VERSION "HNNBNNNYNNNNNNNNNNNNNNNNNNNNNNNNNNNNNNNNNN/4/%%%/4/'%**4NNN///"

NS_ :

BS_:

BU_: Allrad_Haldex AreaView_MQB BAP_Tester Bremse_ABS_MK100 Bremse_ESP_EPB_EBC460Vi Bremse_ESP_EPB_MK100 Bremse_ESP_MK100 Daempfer Gateway_MQB Lenkhilfe_EPS PDC PDC_PLA

BO_ 2617020934 DEV_Lenkhilfe_Resp_06: 8 Lenkhilfe_EPS
 SG_ DEV_Lenkhilfe_Resp_06_Data : 0|64@1+ (1.0,0.0) [0.0|18446744073709551615] ""  Vector__XXX

BO_ 2617020935 DEV_Lenkhilfe_Resp_07: 8 Lenkhilfe_EPS
 SG_ DEV_Lenkhilfe_Resp_07_Data : 0|64@1+ (1.0,0.0) [0.0|18446744073709551615] ""  Vector__XXX

BO_ 2617020936 DEV_Lenkhilfe_Resp_08: 8 Lenkhilfe_EPS
 SG_ DEV_Lenkhilfe_Resp_08_Data : 0|64@1+ (1.0,0.0) [0.0|18446744073709551615] ""  Vector__XXX

BO_ 2617020937 DEV_Lenkhilfe_Resp_09: 8 Lenkhilfe_EPS
 SG_ DEV_Lenkhilfe_Resp_09_Data : 0|64@1+ (1.0,0.0) [0.0|18446744073709551615] ""  Vector__XXX

BO_ 2617020938 DEV_Lenkhilfe_Resp_10: 8 Lenkhilfe_EPS
 SG_ DEV_Lenkhilfe_Resp_10_Data : 0|64@1+ (1.0,0.0) [0.0|18446744073709551615] ""  Vector__XXX

BO_ 2617020939 DEV_Lenkhilfe_Resp_11: 8 Lenkhilfe_EPS
 SG_ DEV_Lenkhilfe_Resp_11_Data : 0|64@1+ (1.0,0.0) [0.0|18446744073709551615] ""  Vector__XXX

BO_ 2617020940 DEV_Lenkhilfe_Resp_12: 8 Lenkhilfe_EPS
 SG_ DEV_Lenkhilfe_Resp_12_Data : 0|64@1+ (1.0,0.0) [0.0|18446744073709551615] ""  Vector__XXX

BO_ 2617020941 DEV_Lenkhilfe_Resp_13: 8 Lenkhilfe_EPS
 SG_ DEV_Lenkhilfe_Resp_13_Data : 0|64@1+ (1.0,0.0) [0.0|18446744073709551615] ""  Vector__XXX

BO_ 2617020960 DEV_Lenkhilfe_SIC_Resp_01: 8 Lenkhilfe_EPS
 SG_ DEV_Lenkhilfe_SIC_Resp_01_Data : 0|64@1+ (1.0,0.0) [0.0|18446744073709551615] ""  Vector__XXX

BO_ 2617020961 DEV_Lenkhilfe_SIC_Resp_02: 8 Lenkhilfe_EPS
 SG_ DEV_Lenkhilfe_SIC_Resp_02_Data : 0|64@1+ (1.0,0.0) [0.0|18446744073709551615] ""  Vector__XXX

BO_ 2617004544 DEV_PDC_Resp_00: 8 PDC
 SG_ DEV_PDC_Resp_00_Data : 0|64@1+ (1.0,0.0) [0.0|18446744073709551615] ""  Vector__XXX

BO_ 2617004545 DEV_PDC_Resp_01: 8 PDC
 SG_ DEV_PDC_Resp_01_Data : 0|64@1+ (1.0,0.0) [0.0|18446744073709551615] ""  Vector__XXX

BO_ 2617004546 DEV_PDC_Resp_02: 8 PDC
 SG_ DEV_PDC_Resp_02_Data : 0|64@1+ (1.0,0.0) [0.0|18446744073709551615] ""  Vector__XXX

BO_ 2617004547 DEV_PDC_Resp_03: 8 PDC
 SG_ DEV_PDC_Resp_03_Data : 0|64@1+ (1.0,0.0) [0.0|18446744073709551615] ""  Vector__XXX

BO_ 2617004548 DEV_PDC_Resp_04: 8 PDC
 SG_ DEV_PDC_Resp_04_Data : 0|64@1+ (1.0,0.0) [0.0|18446744073709551615] ""  Vector__XXX

BO_ 2617004549 DEV_PDC_Resp_05: 8 PDC
 SG_ DEV_PDC_Resp_05_Data : 0|64@1+ (1.0,0.0) [0.0|18446744073709551615] ""  Vector__XXX

BO_ 2617004550 DEV_PDC_Resp_06: 8 PDC
 SG_ DEV_PDC_Resp_06_Data : 0|64@1+ (1.0,0.0) [0.0|18446744073709551615] ""  Vector__XXX

BO_ 2617004551 DEV_PDC_Resp_07: 8 PDC
 SG_ DEV_PDC_Resp_07_Data : 0|64@1+ (1.0,0.0) [0.0|18446744073709551615] ""  Vector__XXX

BO_ 2617004552 DEV_PDC_Resp_08: 8 PDC
 SG_ DEV_PDC_Resp_08_Data : 0|64@1+ (1.0,0.0) [0.0|18446744073709551615] ""  Vector__XXX

BO_ 2617004553 DEV_PDC_Resp_09: 8 PDC
 SG_ DEV_PDC_Resp_09_Data : 0|64@1+ (1.0,0.0) [0.0|18446744073709551615] ""  Vector__XXX

BO_ 2617004554 DEV_PDC_Resp_10: 8 PDC
 SG_ DEV_PDC_Resp_10_Data : 0|64@1+ (1.0,0.0) [0.0|18446744073709551615] ""  Vector__XXX

BO_ 2617004555 DEV_PDC_Resp_11: 8 PDC
 SG_ DEV_PDC_Resp_11_Data : 0|64@1+ (1.0,0.0) [0.0|18446744073709551615] ""  Vector__XXX

BO_ 2617004556 DEV_PDC_Resp_12: 8 PDC
 SG_ DEV_PDC_Resp_12_Data : 0|64@1+ (1.0,0.0) [0.0|18446744073709551615] ""  Vector__XXX

BO_ 2617004557 DEV_PDC_Resp_13: 8 PDC
 SG_ DEV_PDC_Resp_13_Data : 0|64@1+ (1.0,0.0) [0.0|18446744073709551615] ""  Vector__XXX

BO_ 2617004558 DEV_PDC_Resp_14: 8 PDC
 SG_ DEV_PDC_Resp_14_Data : 0|64@1+ (1.0,0.0) [0.0|18446744073709551615] ""  Vector__XXX

BO_ 2617004559 DEV_PDC_Resp_15: 8 PDC
 SG_ DEV_PDC_Resp_15_Data : 0|64@1+ (1.0,0.0) [0.0|18446744073709551615] ""  Vector__XXX

BO_ 2617004560 DEV_PDC_Resp_16: 8 PDC_PLA
 SG_ DEV_PDC_Resp_16_Data : 0|64@1+ (1.0,0.0) [0.0|18446744073709551615] ""  Vector__XXX

BO_ 2617004561 DEV_PDC_Resp_17: 8 PDC_PLA
 SG_ DEV_PDC_Resp_17_Data : 0|64@1+ (1.0,0.0) [0.0|18446744073709551615] ""  Vector__XXX

BO_ 2617004562 DEV_PDC_Resp_18: 8 PDC_PLA
 SG_ DEV_PDC_Resp_18_Data : 0|64@1+ (1.0,0.0) [0.0|18446744073709551615] ""  Vector__XXX

BO_ 2617004563 DEV_PDC_Resp_19: 8 PDC_PLA
 SG_ DEV_PDC_Resp_19_Data : 0|64@1+ (1.0,0.0) [0.0|18446744073709551615] ""  Vector__XXX

BO_ 2617004564 DEV_PDC_Resp_20: 8 PDC_PLA
 SG_ DEV_PDC_Resp_20_Data : 0|64@1+ (1.0,0.0) [0.0|18446744073709551615] ""  Vector__XXX

BO_ 2617004565 DEV_PDC_Resp_21: 8 PDC_PLA
 SG_ DEV_PDC_Resp_21_Data : 0|64@1+ (1.0,0.0) [0.0|18446744073709551615] ""  Vector__XXX

BO_ 2617004566 DEV_PDC_Resp_22: 8 PDC_PLA
 SG_ DEV_PDC_Resp_22_Data : 0|64@1+ (1.0,0.0) [0.0|18446744073709551615] ""  Vector__XXX

BO_ 2617004567 DEV_PDC_Resp_23: 8 PDC_PLA
 SG_ DEV_PDC_Resp_23_Data : 0|64@1+ (1.0,0.0) [0.0|18446744073709551615] ""  Vector__XXX

BO_ 2617004568 DEV_PDC_Resp_24: 8 PDC_PLA
 SG_ DEV_PDC_Resp_24_Data : 0|64@1+ (1.0,0.0) [0.0|18446744073709551615] ""  Vector__XXX

BO_ 2617004569 DEV_PDC_Resp_25: 8 PDC_PLA
 SG_ DEV_PDC_Resp_25_Data : 0|64@1+ (1.0,0.0) [0.0|18446744073709551615] ""  Vector__XXX

BO_ 2617004570 DEV_PDC_Resp_26: 8 PDC_PLA
 SG_ DEV_PDC_Resp_26_Data : 0|64@1+ (1.0,0.0) [0.0|18446744073709551615] ""  Vector__XXX

BO_ 2617004571 DEV_PDC_Resp_27: 8 PDC_PLA
 SG_ DEV_PDC_Resp_27_Data : 0|64@1+ (1.0,0.0) [0.0|18446744073709551615] ""  Vector__XXX

BO_ 2617004572 DEV_PDC_Resp_28: 8 PDC_PLA
 SG_ DEV_PDC_Resp_28_Data : 0|64@1+ (1.0,0.0) [0.0|18446744073709551615] ""  Vector__XXX

BO_ 2617004573 DEV_PDC_Resp_29: 8 PDC_PLA
 SG_ DEV_PDC_Resp_29_Data : 0|64@1+ (1.0,0.0) [0.0|18446744073709551615] ""  Vector__XXX

BO_ 2617004574 DEV_PDC_Resp_30: 8 PDC_PLA
 SG_ DEV_PDC_Resp_30_Data : 0|64@1+ (1.0,0.0) [0.0|18446744073709551615] ""  Vector__XXX

BO_ 2617004575 DEV_PDC_Resp_31: 8 PDC_PLA
 SG_ DEV_PDC_Resp_31_Data : 0|64@1+ (1.0,0.0) [0.0|18446744073709551615] ""  Vector__XXX

BO_ 2617199104 DEV_RearView_Resp_00: 8 AreaView_MQB
 SG_ DEV_RearView_Resp_00_Data : 0|64@1+ (1.0,0.0) [0.0|18446744073709551615] ""  Vector__XXX

BO_ 2617199105 DEV_RearView_Resp_01: 8 AreaView_MQB
 SG_ DEV_RearView_Resp_01_Data : 0|64@1+ (1.0,0.0) [0.0|18446744073709551615] ""  Vector__XXX

BO_ 2617199106 DEV_RearView_Resp_02: 8 AreaView_MQB
 SG_ DEV_RearView_Resp_02_Data : 0|64@1+ (1.0,0.0) [0.0|18446744073709551615] ""  Vector__XXX

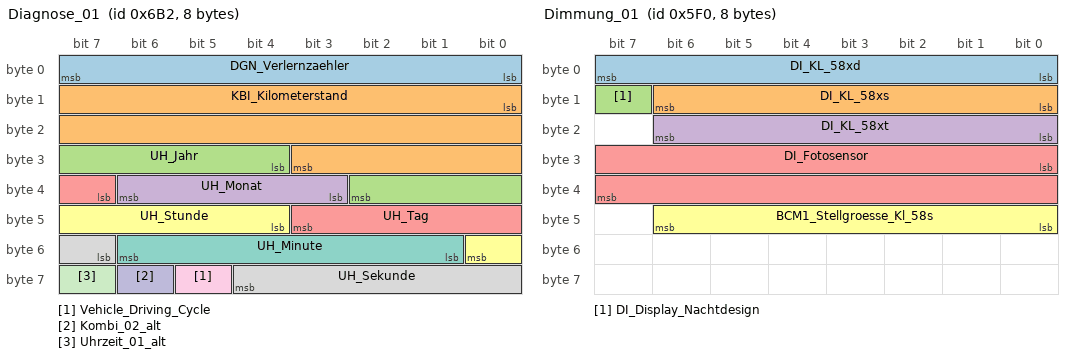
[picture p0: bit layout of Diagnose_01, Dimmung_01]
BO_ 1714 Diagnose_01: 8 Gateway_MQB
 SG_ DGN_Verlernzaehler : 0|8@1+ (1,0) [0|254] ""  Allrad_Haldex,AreaView_MQB,Bremse_ABS_MK100,Bremse_ESP_EPB_EBC460Vi,Bremse_ESP_EPB_MK100,Bremse_ESP_MK100,Daempfer,Lenkhilfe_EPS,PDC,PDC_PLA
 SG_ KBI_Kilometerstand : 8|20@1+ (1,0) [0|1048573] "Unit_KiloMeter"  Allrad_Haldex,AreaView_MQB,Bremse_ABS_MK100,Bremse_ESP_EPB_EBC460Vi,Bremse_ESP_EPB_MK100,Bremse_ESP_MK100,Daempfer,Lenkhilfe_EPS,PDC,PDC_PLA
 SG_ UH_Jahr : 28|7@1+ (1,2000) [2000|2127] "Unit_Year"  Allrad_Haldex,AreaView_MQB,Bremse_ABS_MK100,Bremse_ESP_EPB_EBC460Vi,Bremse_ESP_EPB_MK100,Bremse_ESP_MK100,Daempfer,Lenkhilfe_EPS,PDC,PDC_PLA
 SG_ UH_Monat : 35|4@1+ (1,0) [1|12] "Unit_Month"  Allrad_Haldex,AreaView_MQB,Bremse_ABS_MK100,Bremse_ESP_EPB_EBC460Vi,Bremse_ESP_EPB_MK100,Bremse_ESP_MK100,Daempfer,Lenkhilfe_EPS,PDC,PDC_PLA
 SG_ UH_Tag : 39|5@1+ (1,0) [1|31] "Unit_Day"  Allrad_Haldex,AreaView_MQB,Bremse_ABS_MK100,Bremse_ESP_EPB_EBC460Vi,Bremse_ESP_EPB_MK100,Bremse_ESP_MK100,Daempfer,Lenkhilfe_EPS,PDC,PDC_PLA
 SG_ UH_Stunde : 44|5@1+ (1,0) [0|23] "Unit_Hours"  Allrad_Haldex,AreaView_MQB,Bremse_ABS_MK100,Bremse_ESP_EPB_EBC460Vi,Bremse_ESP_EPB_MK100,Bremse_ESP_MK100,Daempfer,Lenkhilfe_EPS,PDC,PDC_PLA
 SG_ UH_Minute : 49|6@1+ (1,0) [0|59] "Unit_Minut"  Allrad_Haldex,AreaView_MQB,Bremse_ABS_MK100,Bremse_ESP_EPB_EBC460Vi,Bremse_ESP_EPB_MK100,Bremse_ESP_MK100,Daempfer,Lenkhilfe_EPS,PDC,PDC_PLA
 SG_ UH_Sekunde : 55|6@1+ (1,0) [0|59] "Unit_Secon"  Allrad_Haldex,AreaView_MQB,Bremse_ABS_MK100,Bremse_ESP_EPB_EBC460Vi,Bremse_ESP_EPB_MK100,Bremse_ESP_MK100,Daempfer,Lenkhilfe_EPS,PDC,PDC_PLA
 SG_ Vehicle_Driving_Cycle : 61|1@1+ (1.0,0.0) [0.0|1] ""  Vector__XXX
 SG_ Kombi_02_alt : 62|1@1+ (1.0,0.0) [0.0|1] ""  AreaView_MQB,Bremse_ABS_MK100,Bremse_ESP_EPB_EBC460Vi,Bremse_ESP_EPB_MK100,Bremse_ESP_MK100,Lenkhilfe_EPS
 SG_ Uhrzeit_01_alt : 63|1@1+ (1.0,0.0) [0.0|1] ""  AreaView_MQB,Bremse_ABS_MK100,Bremse_ESP_EPB_EBC460Vi,Bremse_ESP_EPB_MK100,Bremse_ESP_MK100,Lenkhilfe_EPS,PDC,PDC_PLA

BO_ 1520 Dimmung_01: 8 Gateway_MQB
 SG_ DI_KL_58xd : 0|8@1+ (1,0) [0|253] ""  AreaView_MQB,Bremse_ESP_EPB_EBC460Vi,Bremse_ESP_EPB_MK100,PDC,PDC_PLA
 SG_ DI_KL_58xs : 8|7@1+ (1,0) [0|100] "Unit_PerCent"  Vector__XXX
 SG_ DI_Display_Nachtdesign : 15|1@1+ (1.0,0.0) [0.0|1] ""  Vector__XXX
 SG_ DI_KL_58xt : 16|7@1+ (1,0) [0|100] "Unit_PerCent"  Vector__XXX
 SG_ DI_Fotosensor : 24|16@1+ (1,0) [0|65535] ""  Vector__XXX
 SG_ BCM1_Stellgroesse_Kl_58s : 40|7@1+ (1,0) [0|100] ""  Vector__XXX

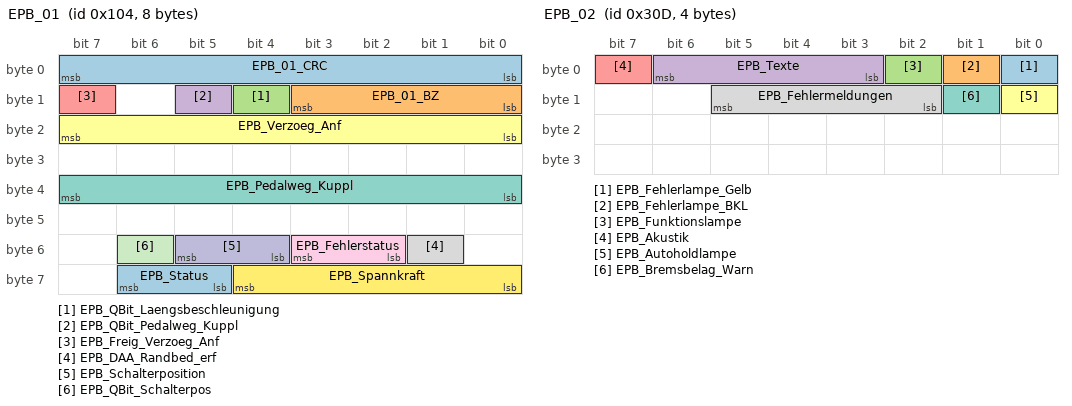
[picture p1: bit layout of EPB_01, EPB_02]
BO_ 260 EPB_01: 8 Bremse_ESP_EPB_EBC460Vi
 SG_ EPB_01_CRC : 0|8@1+ (1,0) [0|255] ""  Gateway_MQB
 SG_ EPB_01_BZ : 8|4@1+ (1,0) [0|15] ""  Gateway_MQB
 SG_ EPB_QBit_Laengsbeschleunigung : 12|1@1+ (1.0,0.0) [0.0|1] ""  Gateway_MQB
 SG_ EPB_QBit_Pedalweg_Kuppl : 13|1@1+ (1.0,0.0) [0.0|1] ""  Gateway_MQB
 SG_ EPB_Freig_Verzoeg_Anf : 15|1@1+ (1.0,0.0) [0.0|1] ""  Daempfer,Gateway_MQB
 SG_ EPB_Verzoeg_Anf : 16|8@1+ (0.048,-7.968) [-7.968|4.224] "Unit_MeterPerSeconSquar"  Daempfer,Gateway_MQB
 SG_ EPB_Pedalweg_Kuppl : 32|8@1+ (0.4,0) [8.0|92.0] "Unit_PerCent"  Gateway_MQB
 SG_ EPB_DAA_Randbed_erf : 49|1@1+ (1.0,0.0) [0.0|1] ""  Gateway_MQB
 SG_ EPB_Fehlerstatus : 50|2@1+ (1.0,0.0) [0.0|3] ""  Gateway_MQB,PDC,PDC_PLA
 SG_ EPB_Schalterposition : 52|2@1+ (1.0,0.0) [0.0|3] ""  Gateway_MQB
 SG_ EPB_QBit_Schalterpos : 54|1@1+ (1.0,0.0) [0.0|1] ""  Gateway_MQB
 SG_ EPB_Spannkraft : 56|5@1+ (1,0) [0|29] "Unit_KiloNewto"  Gateway_MQB
 SG_ EPB_Status : 61|2@1+ (1.0,0.0) [0.0|3] ""  AreaView_MQB,Gateway_MQB,PDC,PDC_PLA

BO_ 781 EPB_02: 4 Bremse_ESP_EPB_EBC460Vi
 SG_ EPB_Fehlerlampe_Gelb : 0|1@1+ (1.0,0.0) [0.0|1] ""  Gateway_MQB
 SG_ EPB_Fehlerlampe_BKL : 1|1@1+ (1.0,0.0) [0.0|1] ""  Gateway_MQB
 SG_ EPB_Funktionslampe : 2|1@1+ (1.0,0.0) [0.0|1] ""  Gateway_MQB
 SG_ EPB_Texte : 3|4@1+ (1.0,0.0) [0.0|15] ""  Gateway_MQB
 SG_ EPB_Akustik : 7|1@1+ (1.0,0.0) [0.0|1] ""  Gateway_MQB
 SG_ EPB_Autoholdlampe : 8|1@1+ (1.0,0.0) [0.0|1] ""  Gateway_MQB
 SG_ EPB_Bremsbelag_Warn : 9|1@1+ (1.0,0.0) [0.0|1] ""  Gateway_MQB
 SG_ EPB_Fehlermeldungen : 10|4@1+ (1.0,0.0) [0.0|15] ""  Gateway_MQB

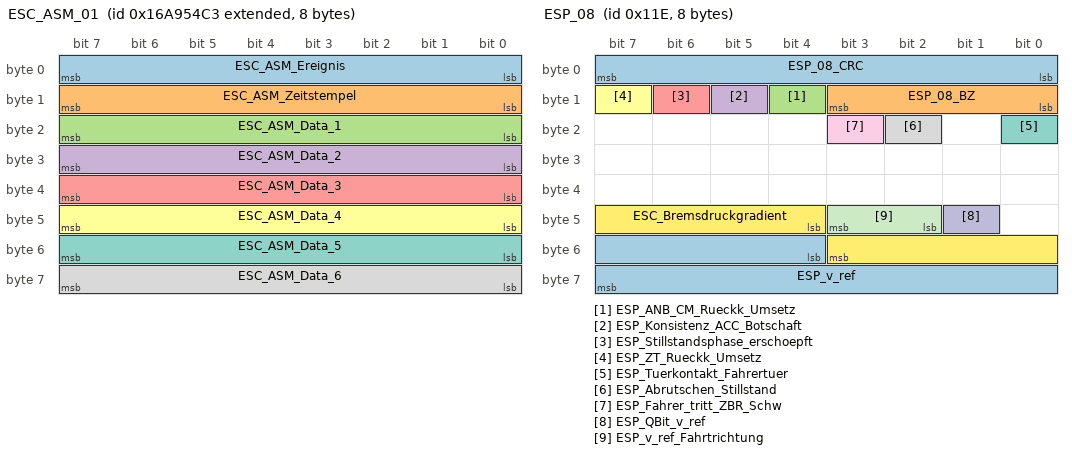
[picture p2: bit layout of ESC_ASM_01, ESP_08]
BO_ 2527679683 ESC_ASM_01: 8 Bremse_ESP_EPB_EBC460Vi
 SG_ ESC_ASM_Ereignis : 0|8@1+ (1.0,0.0) [0.0|255] ""  Gateway_MQB
 SG_ ESC_ASM_Zeitstempel : 8|8@1+ (0.08,0) [0.00|20.32] "Unit_Secon"  Gateway_MQB
 SG_ ESC_ASM_Data_1 : 16|8@1+ (1,0) [0|255] ""  Gateway_MQB
 SG_ ESC_ASM_Data_2 : 24|8@1+ (1,0) [0|255] ""  Gateway_MQB
 SG_ ESC_ASM_Data_3 : 32|8@1+ (1,0) [0|255] ""  Gateway_MQB
 SG_ ESC_ASM_Data_4 : 40|8@1+ (1,0) [0|255] ""  Gateway_MQB
 SG_ ESC_ASM_Data_5 : 48|8@1+ (1,0) [0|255] ""  Gateway_MQB
 SG_ ESC_ASM_Data_6 : 56|8@1+ (1,0) [0|255] ""  Gateway_MQB

BO_ 257 ESP_02: 8 Bremse_ABS_MK100
 SG_ ESP_02_CRC : 0|8@1+ (1,0) [0|255] ""  Gateway_MQB,Lenkhilfe_EPS,PDC_PLA
 SG_ ESP_02_BZ : 8|4@1+ (1,0) [0|15] ""  Allrad_Haldex,Gateway_MQB,Lenkhilfe_EPS,PDC_PLA
 SG_ ESP_QBit_Gierrate : 12|1@1+ (1.0,0.0) [0.0|1] ""  Allrad_Haldex,AreaView_MQB,Daempfer,Gateway_MQB,Lenkhilfe_EPS,PDC_PLA
 SG_ ESP_QBit_Laengsbeschl : 13|1@1+ (1.0,0.0) [0.0|1] ""  Allrad_Haldex,AreaView_MQB,Daempfer,Gateway_MQB,Lenkhilfe_EPS,PDC_PLA
 SG_ ESP_QBit_Querb : 14|1@1+ (1.0,0.0) [0.0|1] ""  Allrad_Haldex,AreaView_MQB,Daempfer,Gateway_MQB,Lenkhilfe_EPS
 SG_ ESP_Stillstandsflag : 15|1@1+ (1.0,0.0) [0.0|1] ""  Gateway_MQB
 SG_ ESP_Querbeschleunigung : 16|8@1+ (0.01,-1.27) [-1.27|1.27] "Unit_ForceOfGravi"  Allrad_Haldex,AreaView_MQB,Daempfer,Gateway_MQB,Lenkhilfe_EPS
 SG_ ESP_Laengsbeschl : 24|10@1+ (0.03125,-16) [-16.00000|15.90625] "Unit_MeterPerSeconSquar"  Allrad_Haldex,AreaView_MQB,Daempfer,Gateway_MQB,Lenkhilfe_EPS,PDC_PLA
 SG_ ESC_Motorstartverzoegerung : 34|1@1+ (1.0,0.0) [0.0|1] ""  Gateway_MQB
 SG_ ESC_SeitenwindAssistent_Eingriff : 35|1@1+ (1.0,0.0) [0.0|1] ""  Gateway_MQB
 SG_ ESP_Anschleppstart_Freigabe : 36|2@1+ (1.0,0.0) [0.0|3] ""  Gateway_MQB
 SG_ ESP_QBit_Anf_Vert_Wank : 39|1@1+ (1.0,0.0) [0.0|1] ""  Gateway_MQB
 SG_ ESP_Gierrate : 40|14@1+ (0.01,0) [0.00|163.82] "Unit_DegreOfArcPerSecon"  Allrad_Haldex,AreaView_MQB,Daempfer,Gateway_MQB,Lenkhilfe_EPS,PDC,PDC_PLA
 SG_ ESP_VZ_Gierrate : 54|1@1+ (1.0,0.0) [0.0|1] ""  Allrad_Haldex,AreaView_MQB,Daempfer,Gateway_MQB,Lenkhilfe_EPS,PDC,PDC_PLA
 SG_ ESP_Notbremsanzeige : 55|1@1+ (1.0,0.0) [0.0|1] ""  Gateway_MQB
 SG_ ESP_SpannungsAnf : 56|1@1+ (1.0,0.0) [0.0|1] ""  Gateway_MQB
 SG_ ESP_PLA_Abbruch : 57|3@1+ (1.0,0.0) [0.0|7] ""  Gateway_MQB,PDC_PLA
 SG_ ESP_Status_ESP_PLA : 60|4@1+ (1.0,0.0) [0.0|15] ""  Gateway_MQB,PDC_PLA

BO_ 262 ESP_05: 8 Bremse_ABS_MK100
 SG_ ESP_05_CRC : 0|8@1+ (1,0) [0|255] ""  Gateway_MQB,Lenkhilfe_EPS,PDC_PLA
 SG_ ESP_05_BZ : 8|4@1+ (1,0) [0|15] ""  Allrad_Haldex,Gateway_MQB,Lenkhilfe_EPS,PDC_PLA
 SG_ ESP_QBit_Bremsdruck : 12|1@1+ (1.0,0.0) [0.0|1] ""  Daempfer,Gateway_MQB,Lenkhilfe_EPS,PDC_PLA
 SG_ ESP_QBit_Fahrer_bremst : 13|1@1+ (1.0,0.0) [0.0|1] ""  Allrad_Haldex,Gateway_MQB,Lenkhilfe_EPS
 SG_ ESP_Schwelle_Unterdruck : 14|2@1+ (1.0,0.0) [0.0|3] ""  Gateway_MQB
 SG_ ESP_Bremsdruck : 16|10@1+ (0.3,-30) [-30.0|276.6] "Unit_Bar"  Allrad_Haldex,Daempfer,Gateway_MQB,Lenkhilfe_EPS,PDC_PLA
 SG_ ESP_Fahrer_bremst : 26|1@1+ (1.0,0.0) [0.0|1] ""  Allrad_Haldex,Gateway_MQB,Lenkhilfe_EPS
 SG_ ESP_Verz_TSK_aktiv : 27|1@1+ (1.0,0.0) [0.0|1] ""  Allrad_Haldex,Gateway_MQB
 SG_ ESP_Lenkeingriff_ADS : 28|1@1+ (1.0,0.0) [0.0|1] ""  Gateway_MQB
 SG_ ESP_Konsistenz_TSK : 29|1@1+ (1.0,0.0) [0.0|1] ""  Gateway_MQB
 SG_ ESP_Bremsruck_AWV2 : 30|1@1+ (1.0,0.0) [0.0|1] ""  Gateway_MQB
 SG_ ESP_Konsistenz_AWV2 : 31|1@1+ (1.0,0.0) [0.0|1] ""  Gateway_MQB
 SG_ ECD_Fehler : 32|1@1+ (1.0,0.0) [0.0|1] ""  Gateway_MQB
 SG_ ECD_nicht_verfuegbar : 33|1@1+ (1.0,0.0) [0.0|1] ""  Gateway_MQB
 SG_ ESP_Status_Bremsentemp : 34|1@1+ (1.0,0.0) [0.0|1] ""  Gateway_MQB
 SG_ ESP_Autohold_Standby : 35|1@1+ (1.0,0.0) [0.0|1] ""  Gateway_MQB
 SG_ ESP_HDC_Standby : 36|1@1+ (1.0,0.0) [0.0|1] ""  Gateway_MQB
 SG_ ESP_HBA_aktiv : 37|1@1+ (1.0,0.0) [0.0|1] ""  Gateway_MQB
 SG_ ESP_Prefill_ausgeloest : 38|1@1+ (1.0,0.0) [0.0|1] ""  Gateway_MQB
 SG_ ESP_Rueckwaertsfahrt_erkannt : 39|1@1+ (1.0,0.0) [0.0|1] ""  Gateway_MQB
 SG_ ESP_Status_Anfahrhilfe : 40|1@1+ (1.0,0.0) [0.0|1] ""  Gateway_MQB
 SG_ ESP_HDC_aktiv : 41|1@1+ (1.0,0.0) [0.0|1] ""  Gateway_MQB
 SG_ ESP_StartStopp_Info : 42|2@1+ (1.0,0.0) [0.0|3] ""  Gateway_MQB
 SG_ ESP_Eingr_HL : 44|1@1+ (1.0,0.0) [0.0|1] ""  Gateway_MQB
 SG_ ESP_Eingr_HR : 45|1@1+ (1.0,0.0) [0.0|1] ""  Gateway_MQB
 SG_ ESP_Eingr_VL : 46|1@1+ (1.0,0.0) [0.0|1] ""  Gateway_MQB
 SG_ ESP_Eingr_VR : 47|1@1+ (1.0,0.0) [0.0|1] ""  Gateway_MQB
 SG_ ESP_BKV_Unterdruck : 48|8@1+ (4,0) [4|1012] "Unit_MilliBar"  Gateway_MQB
 SG_ ESP_Autohold_aktiv : 56|1@1+ (1.0,0.0) [0.0|1] ""  Gateway_MQB
 SG_ ESP_FStatus_Anfahrhilfe : 57|1@1+ (1.0,0.0) [0.0|1] ""  Gateway_MQB
 SG_ ESP_Verz_EPB_aktiv : 58|1@1+ (1.0,0.0) [0.0|1] ""  Allrad_Haldex,Gateway_MQB
 SG_ ECD_Bremslicht : 59|1@1+ (1.0,0.0) [0.0|1] ""  Gateway_MQB
 SG_ ESP_Verzoeg_EPB_verf : 60|1@1+ (1.0,0.0) [0.0|1] ""  Gateway_MQB
 SG_ ESP_Status_Bremsdruck : 61|1@1+ (1.0,0.0) [0.0|1] ""  Gateway_MQB
 SG_ ESP_Anforderung_EPB : 62|2@1+ (1.0,0.0) [0.0|3] ""  Gateway_MQB

BO_ 914 ESP_07: 8 Bremse_ABS_MK100
 SG_ ESP_07_CRC : 0|8@1+ (1,0) [0|255] ""  Gateway_MQB
 SG_ ESP_07_BZ : 8|4@1+ (1,0) [0|15] ""  Gateway_MQB
 SG_ ESP_ACC_LDE : 12|1@1+ (1.0,0.0) [0.0|1] ""  Gateway_MQB
 SG_ ESP_Allrad_Antrieb : 13|1@1+ (1.0,0.0) [0.0|1] ""  Gateway_MQB
 SG_ ESP_Codierung_ADS : 14|2@1+ (1.0,0.0) [0.0|3] ""  Gateway_MQB
 SG_ ESP_RTA_HL : 16|8@1+ (0.048828125,-6.20117) [-6.201170000|6.152345625] "Unit_PerCent"  Gateway_MQB
 SG_ ESP_RTA_HR : 24|8@1+ (0.048828125,-6.20117) [-6.201170000|6.152345625] "Unit_PerCent"  Gateway_MQB
 SG_ ESP_RTA_VR : 32|8@1+ (0.048828125,-6.20117) [-6.201170000|6.152345625] "Unit_PerCent"  Gateway_MQB
 SG_ OBD_Fehler_Radsensor_HL : 40|4@1+ (1.0,0.0) [0.0|15] ""  Gateway_MQB
 SG_ OBD_Fehler_Radsensor_HR : 44|4@1+ (1.0,0.0) [0.0|15] ""  Gateway_MQB
 SG_ OBD_Fehler_Radsensor_VL : 48|4@1+ (1.0,0.0) [0.0|15] ""  Gateway_MQB
 SG_ OBD_Fehler_Radsensor_VR : 52|4@1+ (1.0,0.0) [0.0|15] ""  Gateway_MQB
 SG_ ESP_Qualifizierung_Antriebsart : 56|1@1+ (1.0,0.0) [0.0|1] ""  Gateway_MQB
 SG_ ESP_Offroad_Modus : 57|1@1+ (1.0,0.0) [0.0|1] ""  Gateway_MQB
 SG_ ESP_MKB_ausloesbar : 58|1@1+ (1.0,0.0) [0.0|1] ""  Gateway_MQB
 SG_ ESP_Stat_FallBack_eBKV : 59|1@1+ (1.0,0.0) [0.0|1] ""  Gateway_MQB
 SG_ ESP_CM_Variante : 60|1@1+ (1.0,0.0) [0.0|1] ""  Gateway_MQB
 SG_ ESP_OBD_Status : 61|1@1+ (1.0,0.0) [0.0|1] ""  Gateway_MQB
 SG_ ESP_Rollenmodus_Deaktivieren : 62|1@1+ (1.0,0.0) [0.0|1] ""  Allrad_Haldex,Daempfer,Gateway_MQB,PDC,PDC_PLA
 SG_ ESP_nachtr_Stopp_Anf : 63|1@1+ (1.0,0.0) [0.0|1] ""  Gateway_MQB

BO_ 286 ESP_08: 8 Bremse_ESP_EPB_EBC460Vi
 SG_ ESP_08_CRC : 0|8@1+ (1,0) [0|255] ""  Gateway_MQB
 SG_ ESP_08_BZ : 8|4@1+ (1,0) [0|15] ""  Gateway_MQB
 SG_ ESP_ANB_CM_Rueckk_Umsetz : 12|1@1+ (1.0,0.0) [0.0|1] ""  Gateway_MQB
 SG_ ESP_Konsistenz_ACC_Botschaft : 13|1@1+ (1.0,0.0) [0.0|1] ""  Gateway_MQB
 SG_ ESP_Stillstandsphase_erschoepft : 14|1@1+ (1.0,0.0) [0.0|1] ""  Gateway_MQB
 SG_ ESP_ZT_Rueckk_Umsetz : 15|1@1+ (1.0,0.0) [0.0|1] ""  Gateway_MQB
 SG_ ESP_Tuerkontakt_Fahrertuer : 16|1@1+ (1.0,0.0) [0.0|1] ""  Gateway_MQB
 SG_ ESP_Abrutschen_Stillstand : 18|1@1+ (1.0,0.0) [0.0|1] ""  Gateway_MQB
 SG_ ESP_Fahrer_tritt_ZBR_Schw : 19|1@1+ (1.0,0.0) [0.0|1] ""  Gateway_MQB
 SG_ ESP_QBit_v_ref : 41|1@1+ (1.0,0.0) [0.0|1] ""  Gateway_MQB
 SG_ ESP_v_ref_Fahrtrichtung : 42|2@1+ (1.0,0.0) [0.0|3] ""  Gateway_MQB
 SG_ ESC_Bremsdruckgradient : 44|8@1+ (10,0) [0|2500] "Unit_BarPerSecon"  Gateway_MQB
 SG_ ESP_v_ref : 52|12@1+ (0.125,0) [0.000|511.500] "Unit_KiloMeterPerHour"  Gateway_MQB

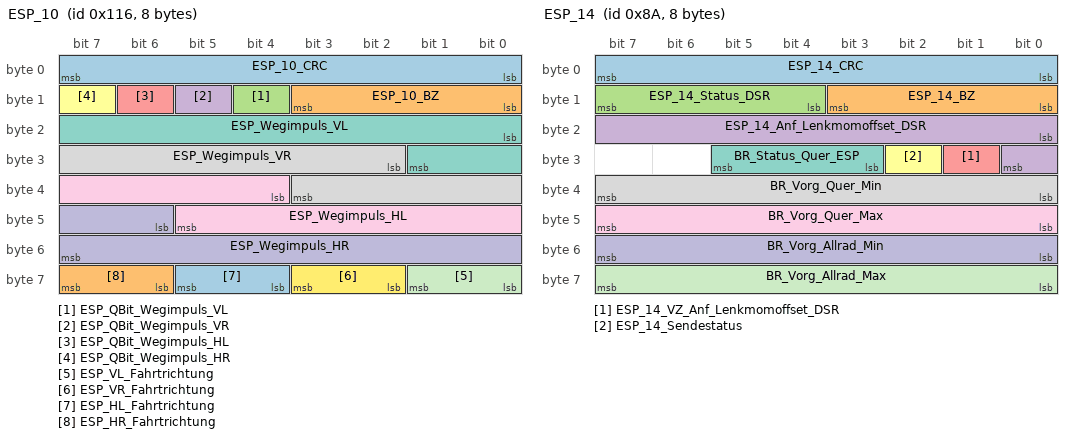
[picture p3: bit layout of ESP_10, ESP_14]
BO_ 278 ESP_10: 8 Bremse_ABS_MK100
 SG_ ESP_10_CRC : 0|8@1+ (1,0) [0|255] ""  Gateway_MQB,Lenkhilfe_EPS,PDC,PDC_PLA
 SG_ ESP_10_BZ : 8|4@1+ (1,0) [0|15] ""  Gateway_MQB,Lenkhilfe_EPS,PDC,PDC_PLA
 SG_ ESP_QBit_Wegimpuls_VL : 12|1@1+ (1.0,0.0) [0.0|1] ""  AreaView_MQB,Gateway_MQB,Lenkhilfe_EPS,PDC,PDC_PLA
 SG_ ESP_QBit_Wegimpuls_VR : 13|1@1+ (1.0,0.0) [0.0|1] ""  AreaView_MQB,Gateway_MQB,Lenkhilfe_EPS,PDC,PDC_PLA
 SG_ ESP_QBit_Wegimpuls_HL : 14|1@1+ (1.0,0.0) [0.0|1] ""  AreaView_MQB,Gateway_MQB,Lenkhilfe_EPS,PDC,PDC_PLA
 SG_ ESP_QBit_Wegimpuls_HR : 15|1@1+ (1.0,0.0) [0.0|1] ""  AreaView_MQB,Gateway_MQB,Lenkhilfe_EPS,PDC,PDC_PLA
 SG_ ESP_Wegimpuls_VL : 16|10@1+ (1,0) [0|1000] ""  AreaView_MQB,Gateway_MQB,Lenkhilfe_EPS,PDC,PDC_PLA
 SG_ ESP_Wegimpuls_VR : 26|10@1+ (1,0) [0|1000] ""  AreaView_MQB,Gateway_MQB,Lenkhilfe_EPS,PDC,PDC_PLA
 SG_ ESP_Wegimpuls_HL : 36|10@1+ (1,0) [0|1000] ""  AreaView_MQB,Gateway_MQB,Lenkhilfe_EPS,PDC,PDC_PLA
 SG_ ESP_Wegimpuls_HR : 46|10@1+ (1,0) [0|1000] ""  AreaView_MQB,Gateway_MQB,Lenkhilfe_EPS,PDC,PDC_PLA
 SG_ ESP_VL_Fahrtrichtung : 56|2@1+ (1.0,0.0) [0.0|3] ""  AreaView_MQB,Gateway_MQB,Lenkhilfe_EPS,PDC,PDC_PLA
 SG_ ESP_VR_Fahrtrichtung : 58|2@1+ (1.0,0.0) [0.0|3] ""  AreaView_MQB,Gateway_MQB,Lenkhilfe_EPS,PDC,PDC_PLA
 SG_ ESP_HL_Fahrtrichtung : 60|2@1+ (1.0,0.0) [0.0|3] ""  AreaView_MQB,Gateway_MQB,Lenkhilfe_EPS,PDC,PDC_PLA
 SG_ ESP_HR_Fahrtrichtung : 62|2@1+ (1.0,0.0) [0.0|3] ""  AreaView_MQB,Gateway_MQB,Lenkhilfe_EPS,PDC,PDC_PLA

BO_ 138 ESP_14: 8 Bremse_ABS_MK100
 SG_ ESP_14_CRC : 0|8@1+ (1,0) [0|255] ""  Lenkhilfe_EPS
 SG_ ESP_14_BZ : 8|4@1+ (1,0) [0|15] ""  Lenkhilfe_EPS
 SG_ ESP_14_Status_DSR : 12|4@1+ (1.0,0.0) [0.0|15] ""  Gateway_MQB,Lenkhilfe_EPS
 SG_ ESP_14_Anf_Lenkmomoffset_DSR : 16|9@1+ (0.01,0) [0.00|5.11] "Unit_NewtoMeter"  Gateway_MQB,Lenkhilfe_EPS
 SG_ ESP_14_VZ_Anf_Lenkmomoffset_DSR : 25|1@1+ (1.0,0.0) [0.0|1] ""  Gateway_MQB,Lenkhilfe_EPS
 SG_ ESP_14_Sendestatus : 26|1@1+ (1.0,0.0) [0.0|1] ""  Vector__XXX
 SG_ BR_Status_Quer_ESP : 27|3@1+ (1.0,0.0) [0.0|7] ""  Vector__XXX
 SG_ BR_Vorg_Quer_Min : 32|8@1+ (0.4,0) [0.0|100.0] "Unit_PerCent"  Vector__XXX
 SG_ BR_Vorg_Quer_Max : 40|8@1+ (0.4,0) [0.0|100.0] "Unit_PerCent"  Vector__XXX
 SG_ BR_Vorg_Allrad_Min : 48|8@1+ (0.4,0) [0.0|100.0] "Unit_PerCent"  Allrad_Haldex
 SG_ BR_Vorg_Allrad_Max : 56|8@1+ (0.4,0) [0.0|100.0] "Unit_PerCent"  Allrad_Haldex

BO_ 418 ESP_15: 8 Bremse_ESP_EPB_MK100
 SG_ ESP_15_CRC : 0|8@1+ (1,0) [0|255] ""  Gateway_MQB
 SG_ ESP_15_BZ : 8|4@1+ (1,0) [0|15] ""  Gateway_MQB
 SG_ HMS_P_beibehalten_GE : 12|2@1+ (1.0,0.0) [0.0|3] ""  Gateway_MQB
 SG_ HMS_Konsistenz_GE : 14|1@1+ (1.0,0.0) [0.0|1] ""  Gateway_MQB
 SG_ HMS_Konsistenz_IPA : 15|1@1+ (1.0,0.0) [0.0|1] ""  Gateway_MQB,PDC_PLA
 SG_ HMS_Konsistenz_EBKV : 16|1@1+ (1.0,0.0) [0.0|1] ""  Gateway_MQB
 SG_ HMS_Konsistenz_RCTA : 17|1@1+ (1.0,0.0) [0.0|1] ""  Gateway_MQB
 SG_ HMS_Konsistenz_STA : 18|1@1+ (1.0,0.0) [0.0|1] ""  Gateway_MQB
 SG_ HMS_Konsistenz_MO : 19|1@1+ (1.0,0.0) [0.0|1] ""  Gateway_MQB
 SG_ HMS_halten_nicht_verfuegbar : 20|1@1+ (1.0,0.0) [0.0|1] ""  Gateway_MQB
 SG_ NL_PRIM_STP_01_Status : 21|3@1+ (1.0,0.0) [0.0|7] ""  Gateway_MQB
 SG_ HMS_Notstopp_Status : 29|3@1+ (1.0,0.0) [0.0|7] ""  Gateway_MQB
 SG_ HMS_parken_nicht_verfuegbar : 32|1@1+ (1.0,0.0) [0.0|1] ""  Gateway_MQB
 SG_ HMS_Anforderung_GE : 33|3@1+ (1.0,0.0) [0.0|7] ""  Gateway_MQB
 SG_ HMS_Systemstatus : 36|4@1+ (1.0,0.0) [0.0|15] ""  Gateway_MQB,PDC_PLA
 SG_ HMS_Stillstand : 40|3@1+ (1.0,0.0) [0.0|7] ""  Gateway_MQB,PDC_PLA
 SG_ HMS_aktives_System : 43|5@1+ (1.0,0.0) [0.0|31] ""  Gateway_MQB,PDC_PLA
 SG_ HMS_Konsistenz_HVLM : 48|1@1+ (1.0,0.0) [0.0|1] ""  Gateway_MQB
 SG_ HMS_Konsistenz_ACC : 49|1@1+ (1.0,0.0) [0.0|1] ""  Gateway_MQB
 SG_ HMS_Fehlerstatus : 50|3@1+ (1.0,0.0) [0.0|7] ""  Gateway_MQB,PDC_PLA
 SG_ ESP_Index_Haltemoment : 53|1@1+ (1.0,0.0) [0.0|1] ""  Gateway_MQB
 SG_ ESP_Haltemoment : 54|10@1+ (10,0) [0|10210] "Unit_NewtoMeter"  Gateway_MQB

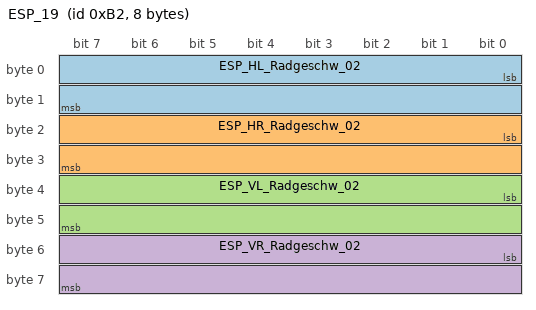
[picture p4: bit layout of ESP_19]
BO_ 178 ESP_19: 8 Bremse_ABS_MK100
 SG_ ESP_HL_Radgeschw_02 : 0|16@1+ (0.0075,0) [0.0000|491.4900] "Unit_KiloMeterPerHour"  Allrad_Haldex,AreaView_MQB,Gateway_MQB,Lenkhilfe_EPS,PDC,PDC_PLA
 SG_ ESP_HR_Radgeschw_02 : 16|16@1+ (0.0075,0) [0.0000|491.4900] "Unit_KiloMeterPerHour"  Allrad_Haldex,AreaView_MQB,Gateway_MQB,Lenkhilfe_EPS,PDC,PDC_PLA
 SG_ ESP_VL_Radgeschw_02 : 32|16@1+ (0.0075,0) [0.0000|491.4900] "Unit_KiloMeterPerHour"  Allrad_Haldex,AreaView_MQB,Gateway_MQB,Lenkhilfe_EPS,PDC,PDC_PLA
 SG_ ESP_VR_Radgeschw_02 : 48|16@1+ (0.0075,0) [0.0000|491.4900] "Unit_KiloMeterPerHour"  Allrad_Haldex,AreaView_MQB,Gateway_MQB,Lenkhilfe_EPS,PDC,PDC_PLA

BO_ 1629 ESP_20: 8 Bremse_ABS_MK100
 SG_ ESP_20_CRC : 0|8@1+ (1,0) [0|255] ""  Gateway_MQB,Lenkhilfe_EPS
 SG_ ESP_20_BZ : 8|4@1+ (1,0) [0|15] ""  Gateway_MQB,Lenkhilfe_EPS
 SG_ BR_Systemart : 12|2@1+ (1.0,0.0) [0.0|3] ""  Allrad_Haldex,Gateway_MQB
 SG_ ESP_SpannungsAnf_02 : 14|2@1+ (1.0,0.0) [0.0|3] ""  Gateway_MQB
 SG_ ESP_Zaehnezahl : 16|8@1+ (1,0) [0|255] ""  AreaView_MQB,Gateway_MQB,Lenkhilfe_EPS,PDC_PLA
 SG_ ESP_Charisma_FahrPr : 24|4@1+ (1.0,0.0) [0.0|15] ""  Gateway_MQB
 SG_ ESP_Charisma_Status : 28|2@1+ (1.0,0.0) [0.0|3] ""  Gateway_MQB
 SG_ ESP_Wiederstart_Anz_01 : 30|1@1+ (1.0,0.0) [0.0|1] ""  Gateway_MQB
 SG_ ESP_Wiederstart_Anz_02 : 31|1@1+ (1.0,0.0) [0.0|1] ""  Gateway_MQB
 SG_ ESP_Wiederstart_Anz_03 : 32|1@1+ (1.0,0.0) [0.0|1] ""  Gateway_MQB
 SG_ ESP_Wiederstart_Anz_04 : 33|1@1+ (1.0,0.0) [0.0|1] ""  Gateway_MQB
 SG_ ESP_Stoppverbot_Anz_01 : 34|1@1+ (1.0,0.0) [0.0|1] ""  Gateway_MQB
 SG_ ESP_Stoppverbot_Anz_02 : 35|1@1+ (1.0,0.0) [0.0|1] ""  Gateway_MQB
 SG_ ESP_Stoppverbot_Anz_03 : 36|1@1+ (1.0,0.0) [0.0|1] ""  Gateway_MQB
 SG_ ESP_Stoppverbot_Anz_04 : 37|1@1+ (1.0,0.0) [0.0|1] ""  Gateway_MQB
 SG_ ESP_Stoppverbot_Anz_05 : 38|1@1+ (1.0,0.0) [0.0|1] ""  Gateway_MQB
 SG_ ESP_Stoppverbot_Anz_06 : 39|1@1+ (1.0,0.0) [0.0|1] ""  Gateway_MQB
 SG_ ESP_Stoppverbot_Anz_07 : 40|1@1+ (1.0,0.0) [0.0|1] ""  Gateway_MQB
 SG_ ESP_Stoppverbot_Anz_Std : 41|1@1+ (1.0,0.0) [0.0|1] ""  Gateway_MQB
 SG_ ESP_Dachrelingsensor : 42|2@1+ (1.0,0.0) [0.0|3] ""  Gateway_MQB
 SG_ ESP_Stoppverbot_Anz_08 : 44|1@1+ (1.0,0.0) [0.0|1] ""  Gateway_MQB
 SG_ HDC_Charisma_FahrPr : 45|4@1+ (1.0,0.0) [0.0|15] ""  Gateway_MQB
 SG_ HDC_Charisma_Status : 49|2@1+ (1.0,0.0) [0.0|3] ""  Gateway_MQB
 SG_ BR_QBit_Reifenumfang : 51|1@1+ (1.0,0.0) [0.0|1] ""  Allrad_Haldex,AreaView_MQB,Gateway_MQB,Lenkhilfe_EPS
 SG_ BR_Reifenumfang : 52|12@1+ (1,0) [0|4095] "Unit_MilliMeter"  Allrad_Haldex,AreaView_MQB,Gateway_MQB,Lenkhilfe_EPS

BO_ 253 ESP_21: 8 Bremse_ABS_MK100
 SG_ ESP_21_CRC : 0|8@1+ (1,0) [0|255] ""  Gateway_MQB,Lenkhilfe_EPS,PDC,PDC_PLA
 SG_ ESP_21_BZ : 8|4@1+ (1,0) [0|15] ""  Allrad_Haldex,Gateway_MQB,Lenkhilfe_EPS,PDC,PDC_PLA
 SG_ BR_Eingriffsmoment : 12|10@1+ (1,-509) [-509|509] ""  Gateway_MQB
 SG_ ESP_PLA_Bremseingriff : 22|1@1+ (1.0,0.0) [0.0|1] ""  Gateway_MQB
 SG_ ESP_Diagnose : 23|1@1+ (1.0,0.0) [0.0|1] ""  Gateway_MQB
 SG_ ESC_Reku_Freigabe : 24|1@1+ (1.0,0.0) [0.0|1] ""  Gateway_MQB
 SG_ ESC_v_Signal_Qualifier_High_Low : 25|3@1+ (1.0,0.0) [0.0|7] ""  Gateway_MQB
 SG_ ESP_Vorsteuerung : 28|1@1+ (1.0,0.0) [0.0|1] ""  Gateway_MQB,PDC_PLA
 SG_ ESP_AWV3_Brems_aktiv : 29|1@1+ (1.0,0.0) [0.0|1] ""  Gateway_MQB
 SG_ OBD_Schlechtweg : 30|1@1+ (1.0,0.0) [0.0|1] ""  Gateway_MQB
 SG_ OBD_QBit_Schlechtweg : 31|1@1+ (1.0,0.0) [0.0|1] ""  Gateway_MQB
 SG_ ESP_v_Signal : 32|16@1+ (0.01,0) [0.00|655.32] "Unit_KiloMeterPerHour"  AreaView_MQB,Daempfer,Gateway_MQB,Lenkhilfe_EPS,PDC,PDC_PLA
 SG_ ASR_Tastung_passiv : 48|1@1+ (1.0,0.0) [0.0|1] ""  AreaView_MQB,Gateway_MQB,PDC,PDC_PLA
 SG_ ESP_Tastung_passiv : 49|1@1+ (1.0,0.0) [0.0|1] ""  AreaView_MQB,Gateway_MQB,PDC,PDC_PLA
 SG_ ESP_Systemstatus : 50|1@1+ (1.0,0.0) [0.0|1] ""  AreaView_MQB,Gateway_MQB,PDC,PDC_PLA
 SG_ ASR_Schalteingriff : 51|2@1+ (1.0,0.0) [0.0|3] ""  Gateway_MQB,Lenkhilfe_EPS
 SG_ ESP_Haltebestaetigung : 53|1@1+ (1.0,0.0) [0.0|1] ""  Gateway_MQB,PDC,PDC_PLA
 SG_ ESP_MKB_Abbruch_Geschw : 54|1@1+ (1.0,0.0) [0.0|1] ""  Gateway_MQB
 SG_ ESP_QBit_v_Signal : 55|1@1+ (1.0,0.0) [0.0|1] ""  AreaView_MQB,Daempfer,Gateway_MQB,Lenkhilfe_EPS,PDC,PDC_PLA
 SG_ ABS_Bremsung : 56|1@1+ (1.0,0.0) [0.0|1] ""  Allrad_Haldex,AreaView_MQB,Daempfer,Gateway_MQB,Lenkhilfe_EPS,PDC,PDC_PLA
 SG_ ASR_Anf : 57|1@1+ (1.0,0.0) [0.0|1] ""  Allrad_Haldex,AreaView_MQB,Daempfer,Gateway_MQB,Lenkhilfe_EPS,PDC,PDC_PLA
 SG_ MSR_Anf : 58|1@1+ (1.0,0.0) [0.0|1] ""  AreaView_MQB,Gateway_MQB,Lenkhilfe_EPS,PDC,PDC_PLA
 SG_ EBV_Eingriff : 59|1@1+ (1.0,0.0) [0.0|1] ""  AreaView_MQB,Daempfer,Gateway_MQB,Lenkhilfe_EPS
 SG_ EDS_Eingriff : 60|1@1+ (1.0,0.0) [0.0|1] ""  Allrad_Haldex,AreaView_MQB,Daempfer,Gateway_MQB,Lenkhilfe_EPS,PDC,PDC_PLA
 SG_ ESP_Eingriff : 61|1@1+ (1.0,0.0) [0.0|1] ""  Allrad_Haldex,AreaView_MQB,Daempfer,Gateway_MQB,Lenkhilfe_EPS,PDC,PDC_PLA
 SG_ ESP_ASP : 62|1@1+ (1.0,0.0) [0.0|1] ""  Gateway_MQB
 SG_ ESP_Anhaltevorgang_ACC_aktiv : 63|1@1+ (1.0,0.0) [0.0|1] ""  Gateway_MQB

BO_TX_BU_ 2617004544 :PDC,PDC_PLA;
BO_TX_BU_ 2617004545 :PDC,PDC_PLA;
BO_TX_BU_ 2617004546 :PDC,PDC_PLA;
BO_TX_BU_ 2617004547 :PDC,PDC_PLA;
BO_TX_BU_ 2617004548 :PDC,PDC_PLA;
BO_TX_BU_ 2617004549 :PDC,PDC_PLA;
BO_TX_BU_ 2617004550 :PDC,PDC_PLA;
BO_TX_BU_ 2617004551 :PDC,PDC_PLA;
BO_TX_BU_ 2617004552 :PDC,PDC_PLA;
BO_TX_BU_ 2617004553 :PDC,PDC_PLA;
BO_TX_BU_ 2617004554 :PDC,PDC_PLA;
BO_TX_BU_ 2617004555 :PDC,PDC_PLA;
BO_TX_BU_ 2617004556 :PDC,PDC_PLA;
BO_TX_BU_ 2617004557 :PDC,PDC_PLA;
BO_TX_BU_ 2617004558 :PDC,PDC_PLA;
BO_TX_BU_ 2617004559 :PDC,PDC_PLA;
BO_TX_BU_ 260 :Bremse_ESP_EPB_EBC460Vi,Bremse_ESP_EPB_MK100;
BO_TX_BU_ 781 :Bremse_ESP_EPB_EBC460Vi,Bremse_ESP_EPB_MK100;
BO_TX_BU_ 2527679683 :Bremse_ESP_EPB_EBC460Vi,Bremse_ESP_EPB_MK100,Bremse_ESP_MK100;
BO_TX_BU_ 257 :Bremse_ABS_MK100,Bremse_ESP_EPB_EBC460Vi,Bremse_ESP_EPB_MK100,Bremse_ESP_MK100;
BO_TX_BU_ 262 :Bremse_ABS_MK100,Bremse_ESP_EPB_EBC460Vi,Bremse_ESP_EPB_MK100,Bremse_ESP_MK100;
BO_TX_BU_ 914 :Bremse_ABS_MK100,Bremse_ESP_EPB_EBC460Vi,Bremse_ESP_EPB_MK100,Bremse_ESP_MK100;
BO_TX_BU_ 286 :Bremse_ESP_EPB_EBC460Vi,Bremse_ESP_EPB_MK100,Bremse_ESP_MK100;
BO_TX_BU_ 278 :Bremse_ABS_MK100,Bremse_ESP_EPB_EBC460Vi,Bremse_ESP_EPB_MK100,Bremse_ESP_MK100;
BO_TX_BU_ 138 :Bremse_ABS_MK100,Bremse_ESP_EPB_EBC460Vi,Bremse_ESP_EPB_MK100,Bremse_ESP_MK100;
BO_TX_BU_ 178 :Bremse_ABS_MK100,Bremse_ESP_EPB_EBC460Vi,Bremse_ESP_EPB_MK100,Bremse_ESP_MK100;
BO_TX_BU_ 1629 :Bremse_ABS_MK100,Bremse_ESP_EPB_EBC460Vi,Bremse_ESP_EPB_MK100,Bremse_ESP_MK100;
BO_TX_BU_ 253 :Bremse_ABS_MK100,Bremse_ESP_EPB_EBC460Vi,Bremse_ESP_EPB_MK100,Bremse_ESP_MK100;
CM_ BO_ 1520 "ab MQB nach abgestimmten FLH Dimmung";
CM_ BO_ 260 "ab MQB mit CRC-8";
CM_ BO_ 286 "ab MQB mit DLC 8";
CM_ BO_ 418 "MLBevo verlangsamte 100ms-Botscahft";
CM_ BO_ 1629 "neu im MQB";
CM_ BO_ 253 "Neue Momente im MQB
Struktur ab MQB mit CRC8 entstanden aus ESP_01";

CM_ SG_ 1714 DGN_Verlernzaehler "wrap around 254 --> 0";
CM_ SG_ 1714 KBI_Kilometerstand "Fehler wird ausgegeben, falls Kilometerstand nicht restaurierbar
";
CM_ SG_ 1714 UH_Minute "0x3C- 0x3f = Werte ungültig";
CM_ SG_ 1714 UH_Monat "0x0D, 0xF =  Werte ungültig
0x0E = reserviert (nur VW)";
CM_ SG_ 1714 UH_Sekunde "0x3C- 0x3f = Werte ungültig";
CM_ SG_ 1714 UH_Stunde "0x18 - 0x1F = Werte ungültig";
CM_ SG_ 1714 UH_Tag "0x0: reserviert bei VW";
CM_ SG_ 1714 Uhrzeit_01_alt "
";
CM_ SG_ 1714 Vehicle_Driving_Cycle "Optimierung der Inbetriebnahme von Steuergeräten in einem Teilverbau in der Produktion.
Siehe VW80114. Signal bildet (durch eine Gateway-Funktion) den Inhalt des Signals OBD_Driving_Cycle ab.";

CM_ SG_ 1520 BCM1_Stellgroesse_Kl_58s "Rohwert Dimmpoti";
CM_ SG_ 1520 DI_Display_Nachtdesign "Für Displays sind oft  automatische Umschaltungen von Tag-/Nachtdesign vorgesehen.
Es gibt jedoch Zustände, an denen auch tagsüber das Abblendlicht eingeschaltet ist.
z.B. Dauerfahrlicht, Geschwindigkeitsabhängiges 'Licht-An-Bei-Autobahn', 'Regenlicht',";
CM_ SG_ 1520 DI_Fotosensor "Helligkeitswert Fotosensor
Für die Dimmung relevanter Wert zur Sensierung der Umgebungshelligkeit
Im Detail beschrieben im 'Funktionslastenheft Dimmung MQB'.";
CM_ SG_ 1520 DI_KL_58xd "Klemme 58xd Display- und Funktionsbeleuchtung
Mit der Klemme 58xd wird die Helligkeit der Display- und der Funktionsbeleuchtungen der Schalter gesteuert.
Im Detail beschrieben im 'Funktionslastenheft Dimmung MQB'.";
CM_ SG_ 1520 DI_KL_58xs "Suchbeleuchtung Schalter
EIN-AUS-Schaltalgorithmus der allgemeinen Schaltersuchbeleuchtung. 
Im Detail beschrieben im 'Funktionslastenheft Dimmung MQB'.
";
CM_ SG_ 1520 DI_KL_58xt "Timergesteuerte Suchbeleuchtung
Der EIN-AUS-Schaltalgorithmus für die vor- und nachlaufende Schaltersuchbeleuchtungen beim Ein- & Aussteigen; z.B.: Start/Stop-Taster.
Im Detail beschrieben im 'Funktionslastenheft Dimmung MQB'.";

CM_ SG_ 260 EPB_01_CRC "Für MLB:
'Berechnung siehe Lastenheft 'Kommunikationsabsicherung für FlexRay und CAN''

Ab MQB und MLBevo:
'Berechnung siehe Lastenheft 'End-to-End Kommunikationsabsicherung''

Endwerte siehe Begleitdokument 'S-PDU Kennungsfolgen'";
CM_ SG_ 260 EPB_DAA_Randbed_erf "Die Randbedingungen zum automatischen Öffnen der EPB (Funktion DAA) sind erfüllt und ein Betätigen des Fahrpedals führt zum Öffnen der EPB.";
CM_ SG_ 260 EPB_Fehlerstatus "PAG/VW526: Werte 1 und 2 werden nur bei PAG und VW526 verwendet. Genauere Informationen bitte in den Fachabteilungen erfragen!";
CM_ SG_ 260 EPB_Freig_Verzoeg_Anf "Verzögerungsanforderung	";
CM_ SG_ 260 EPB_Pedalweg_Kuppl "Signal entspricht Tastverhältnis des PWM. Gesamtweg Kupplungspedal 10% bis 90%, damit zu erwartende Werte 25 bis 225. 25 bei Kupplungspedal nicht getreten, 225 bei Kupplungspedal voll durchgetreten.
2% Toleranz wird im Wertebereich ermöglicht (8%-92%).
";
CM_ SG_ 260 EPB_QBit_Laengsbeschleunigung "Mitteilung z.Zt. für ACC, um unter bestimmten Zuständen mitzuteilen, daß Längsbeschleunigung temporär ungültig ist. Bsp.: Selbsttest Längsbeschleunigungssensor.";
CM_ SG_ 260 EPB_Schalterposition "Spiegelt die Schalterstellung wieder.

0x3 = Schalterfehler ";
CM_ SG_ 260 EPB_Spannkraft "Erzeugte Spannkraft. Bezieht sich auf die Aktuatoren.

MQB: Spannkraftwerte entsprechen nicht den tatsächlichen Spannkräften. Genauere Informationen bitte in der Fachabteilung erfragen! ";
CM_ SG_ 260 EPB_Status "Gibt den Zustand der EPB-Aktuatoren an.

Nur VW526/PAG E2: Wert 0x3 bedeutet 'unbekannt'

";
CM_ SG_ 260 EPB_Verzoeg_Anf "Steuerungsanforderung an andere Systeme (z.B. ESP), um während der Fahrt, durch den Handbremsschalter ausgelöst, zu bremsen (ECD-Funktion)";

CM_ SG_ 781 EPB_Akustik "Bit wird gesetzt, wenn bei v > 0 eine Fahreran-forderung schließen vorhanden ist (ECD angefordert). PQ46-Kombi sendet Warnton (600Hz) solange dieses Bit gesetzt ist.
Anzeige eines Warntextes
";
CM_ SG_ 781 EPB_Autoholdlampe "Autoholdlampe im Kombi, grünes P
";
CM_ SG_ 781 EPB_Bremsbelag_Warn "Mindestens ein Bremsbelag an der Hinterachse am Fahrzeug ist unter Minimum";
CM_ SG_ 781 EPB_Fehlerlampe_BKL "Die BKL dient als rote Fehlerlampe für die EPB. Sie wird vom EPB-SG aktiv ausgeschaltet.";
CM_ SG_ 781 EPB_Fehlerlampe_Gelb "Fehlerlampe für nicht liegenbleiberreleavante Fehler";
CM_ SG_ 781 EPB_Fehlermeldungen "Über das Signal werden bestimmteFehlertexte und -lampen im Kombi angefordert.";
CM_ SG_ 781 EPB_Funktionslampe "Bit wird nur gesetzt, wenn volle Spannkraft auf beiden Seiten erreicht. PQ46: Bit wird gesetzt, wenn BKL direkt vom EPB-SG als Funktionslampe angesteuert wird.

Bei Audi: Rote Lampe (rotes P) im Kombiinstrument
";
CM_ SG_ 781 EPB_Texte "EPB-Texte für Kombi
9 bei Audi aktuell nicht bedient.
10 bei Audi hinzugefügt für RSe
11 bei PAG Duo Servo Parkbremse aktuell nicht bedient 
12 bei PAG Duo Servo Parkbremse aktuell nicht bedient 
13 nur bei ParkPilot/IPA verwendet";

CM_ SG_ 2527679683 ESC_ASM_Data_1 "Diese Signal wird von mehreren Funktionen auf dem ESC-SG gemäß der ASM-Datendefinition befüllt und an den Assistenzsystemmonitor ASM gesendet";
CM_ SG_ 2527679683 ESC_ASM_Data_2 "Diese Signal wird von mehreren Funktionen auf dem ESC-SG gemäß der ASM-Datendefinition befüllt und an den Assistenzsystemmonitor ASM gesendet";
CM_ SG_ 2527679683 ESC_ASM_Data_3 "Diese Signal wird von mehreren Funktionen auf dem ESC-SG gemäß der ASM-Datendefinition befüllt und an den Assistenzsystemmonitor ASM gesendet";
CM_ SG_ 2527679683 ESC_ASM_Data_4 "Diese Signal wird von mehreren Funktionen auf dem ESC-SG gemäß der ASM-Datendefinition befüllt und an den Assistenzsystemmonitor ASM gesendet";
CM_ SG_ 2527679683 ESC_ASM_Data_5 "Diese Signal wird von mehreren Funktionen auf dem ESC-SG gemäß der ASM-Datendefinition befüllt und an den Assistenzsystemmonitor ASM gesendet";
CM_ SG_ 2527679683 ESC_ASM_Data_6 "Diese Signal wird von mehreren Funktionen auf dem ESC-SG gemäß der ASM-Datendefinition befüllt und an den Assistenzsystemmonitor ASM gesendet";
CM_ SG_ 2527679683 ESC_ASM_Ereignis "Dieses Signal definiert, welche Funktion und welche Art von Aktivität das Senden der Botschaft an den Assistenzsystemmonitor ASM veranlasst hat.";
CM_ SG_ 2527679683 ESC_ASM_Zeitstempel "Dieses Signal ermöglicht die zeitliche Zuordnung der von mehreren Funktionen auf dem ESC-SG an den Assistenzsystemmonitor ASM gesendeten Statusbotschaften";

CM_ SG_ 257 ESC_Motorstartverzoegerung "Mit dem Signal 'Motorstartverzögerung' wird den aktiven Teilnehmern ermöglicht, einen Motorstart durch die Start-Stop-Funktion zu verzögern.";
CM_ SG_ 257 ESC_SeitenwindAssistent_Eingriff "Mit diesem Statusbit wird eine aktive Regelung durch den Seitenwindassistenten signalisiert.";
CM_ SG_ 257 ESP_02_CRC "Für MLB:
'Berechnung siehe Lastenheft 'Kommunikationsabsicherung für FlexRay und CAN''

Ab MQB und MLBevo:
'Berechnung siehe Lastenheft 'End-to-End Kommunikationsabsicherung''

Endwerte siehe Begleitdokument 'S-PDU Kennungsfolgen'";
CM_ SG_ 257 ESP_Anschleppstart_Freigabe "Bilden einer Schleppstartfreigabe aus Fahrdynamiksicht. Schleppstartabbruch bei kritischer Fahrzeugstabilität";
CM_ SG_ 257 ESP_Gierrate "Winkelgeschwindigkeit um die z-Achse, ESP_VZ_Gierrate & ESP_QBit_Gierrate beachten !!!

MLB: gemessener Wert
tatsächliche Auflösung Bosch ESP: 0,27 Grad/s

Ab AU64x Auflösung wie die tatsächliche Skalierung 0,01. Im AU64x und AU57x wird bei ESP-Absch";
CM_ SG_ 257 ESP_Laengsbeschl "Beschleunigungswert in x-Achse

MLB: Im AU64x und AU57x erfolgt die Bereitstellung der Sensorwerte durch SARA-SG! Im AU64x und AU57x wird bei ESP-Abschaltung durch modellgestützte Überwachung das Signal weiterhin ausgegeben.

MQB: reines ABS schickt 0";
CM_ SG_ 257 ESP_Notbremsanzeige "ABS/ASR oder ESP hat Notbremssituation erkannt.
Weiterführende Informationen im Lastenheft spezifiziert und in der entsprechenden Fachabteilung zu erfragen.

";
CM_ SG_ 257 ESP_PLA_Abbruch "Wenn der Bremseingriff abgebrochen wurde, wird in diesem Signal der Grund des Abbruchs dargestellt.
Dies ist nur gültig, wenn der Status ESP_Status_ESP_PLA = '0xA' ist.";
CM_ SG_ 257 ESP_QBit_Anf_Vert_Wank "QBit der Wankmomentenverteilung. Gesetzt bei Ersatzwert, Init oder Fehler.";
CM_ SG_ 257 ESP_QBit_Gierrate "QBit der Gierrate. Gesetzt bei Ersatzwert, Init oder Fehler. 
";
CM_ SG_ 257 ESP_QBit_Laengsbeschl "QBit der Längsbeschleunigung. Gesetzt bei Ersatzwert, Init oder Fehler. 
";
CM_ SG_ 257 ESP_QBit_Querb "QBit der Querbeschleunigung. Gesetzt bei Ersatzwert, Init oder Fehler. ";
CM_ SG_ 257 ESP_Querbeschleunigung "Beschleunigungswert in y-Achse

MLB: Gemessener Wert
0xFF = Fehler (wie bereits im Wertebereich spezifizert)
Bei ESP-Abschaltung durch modellgestützte Überwachung wird das Signal weiterhin ausgegeben.
Im AU64x und AU57x erfolgt die Bereitstellung der";
CM_ SG_ 257 ESP_SpannungsAnf "Die Rekuperation kann mit der Anforderung einer höheren Spannung eingeschränkt werden.";
CM_ SG_ 257 ESP_Status_ESP_PLA "Zustand der Statusmaschine der Bremse für die korrespondierende Statusmaschine in dem PLA-SG";
CM_ SG_ 257 ESP_Stillstandsflag "Bei RB-Projekten wird das Stillstandsflag gesetzt, wenn der absolute Stillstand der Raddrehzahlsensoren erkannt wurde, d.h. kein Zahn bewegt sich mehr. Dieses Bit wird bspw. im MOST für TV-Tuner-Abschaltung Australien verwendet, d.h. leichte Erschütterung";
CM_ SG_ 257 ESP_VZ_Gierrate "Vorzeichen der Gierrate";

CM_ SG_ 262 ECD_Bremslicht "Bremslichtansteuerung durch ECD-Funktion";
CM_ SG_ 262 ECD_Fehler "ESP kann die Verzögerungsregelung/Bremsenregelung aufgrund eines internen Fehlers nicht ausführen, mit Fehlereintrag im ESP.
";
CM_ SG_ 262 ECD_nicht_verfuegbar "ESP kann die Verzögerungsregelung/Bremsenregelung temporär nicht ausführen (z.B. Netzwerkmanagement-Betriebe - KL15 Aus; v<18km/h; ESP in Diagnose, ...), ohne Fehlereintrag im ESP.

";
CM_ SG_ 262 ESP_05_CRC "Für MLB:
'Berechnung siehe Lastenheft 'Kommunikationsabsicherung für FlexRay und CAN''

Ab MQB und MLBevo:
'Berechnung siehe Lastenheft 'End-to-End Kommunikationsabsicherung''

Endwerte siehe Begleitdokument 'S-PDU Kennungsfolgen'";
CM_ SG_ 262 ESP_Anforderung_EPB "ESP fordert von der EPB Öffnen bzw. Schliessen an. Notwendig wegen Autohold-Funktion.";
CM_ SG_ 262 ESP_Autohold_aktiv "Rückmeldung an EPB, dass Autohold aktiv ist.";
CM_ SG_ 262 ESP_Autohold_Standby "Rückmeldung an EPB, dass der Fahrer die Funktion Autohold mindestens einmal angefordert hat. Im Fall eines ESP-Ausfalles oder einer Übernahmeaufforderung erfolgt die EPB-Zuschaltung nur nach Setzen dieses Bits. Bit wird gesetzt nach Betätigung des Autohol";
CM_ SG_ 262 ESP_BKV_Unterdruck "Der maximale Wert wird auf 1012 mbar begrenzt.
Dieses Signal wird im AU64x nicht unterstützt.

Hinweis: Auch bei nicht verbautem BKV-Unterdrucksensor könnte während der Initialisierung der Initialisierungswert gesendet werden.";
CM_ SG_ 262 ESP_Bremsdruck "Rohwert des Bremsdrucks [Vordruck durch Fahrervorgabe (Pvor). Bei aktivem Druckaufbau (Stabilisierungseingriffe) kein Pvor]
";
CM_ SG_ 262 ESP_Bremsruck_AWV2 "Das Signal dient als Rückmeldung zum ACC, dass ein angeforderter AWV2-Bremsruck durchgeführt wird. Die positive Rückmeldung löst u.a. eine entsprechende Fahrerinformation im Kombiinstrument aus";
CM_ SG_ 262 ESP_Eingr_HL "wird von QSP und Neigungsanzeige verwendet

Flag wird vom ESP gesetzt, sobald aufgrund eines ESP-Eingriffs am Rad aktiv Druck aufgebaut wird.
Frühestens mit öffnen des Ventils und spätestens bei einem Bremsmoment von 100Nm. Flag bleibt solange gesetzt ";
CM_ SG_ 262 ESP_Eingr_HR "wird von QSP und Neigungsanzeige verwendet

Flag wird vom ESP gesetzt, sobald aufgrund eines ESP-Eingriffs am Rad aktiv Druck aufgebaut wird.
Frühestens mit öffnen des Ventils und spätestens bei einem Bremsmoment von 100Nm. Flag bleibt solange gesetzt ";
CM_ SG_ 262 ESP_Eingr_VL "wird von QSP und Neigungsanzeige verwendet

Flag wird vom ESP gesetzt, sobald aufgrund eines ESP-Eingriffs am Rad aktiv Druck aufgebaut wird.
Frühestens mit öffnen des Ventils und spätestens bei einem Bremsmoment von 100Nm. Flag bleibt solange gesetzt ";
CM_ SG_ 262 ESP_Eingr_VR "wird von QSP und Neigungsanzeige verwendet

Flag wird vom ESP gesetzt, sobald aufgrund eines ESP-Eingriffs am Rad aktiv Druck aufgebaut wird.
Frühestens mit öffnen des Ventils und spätestens bei einem Bremsmoment von 100Nm. Flag bleibt solange gesetzt ";
CM_ SG_ 262 ESP_Fahrer_bremst "Bit wird gesetzt beim Überschreiten der Bremsdruckschwelle

Weiterführende Informationen im Lastenheft spezifiziert und in der entsprechenden Fachabteilung zu erfragen.
";
CM_ SG_ 262 ESP_FStatus_Anfahrhilfe "Bei gesetztem Bit steht die Funktion Berganfahrassistent (Hillhold) nicht zur Verfügung";
CM_ SG_ 262 ESP_HBA_aktiv "Verwendung/Bedienung ab D4
Signal gibt an, ob der hydraulische Bremsassistent im Regler aktiviert wurde

Im MQB wird das Signal nicht unterstützt!

";
CM_ SG_ 262 ESP_HDC_aktiv "MQB und AU57x Allroad: Mit diesem Statusbit wird eine gerade aktive Regelung des Bergabfahrassistenten (Hill Descent Control) signalisiert.";
CM_ SG_ 262 ESP_HDC_Standby "Verwendung/Bedienung im MQB und AU57x Allroad:
Flag wird vom ESP gesetzt, wenn über den HDC-Taster die HDC-Funktion eingeschalten wurde";
CM_ SG_ 262 ESP_Konsistenz_AWV2 "Rückmeldung zum Sender einer AWV-Anforderung (ACC-Steuergerät) bezüglich Prüfung der Checksumme, des Botschaftszählers, des langen Timeout und DLC.
";
CM_ SG_ 262 ESP_Konsistenz_TSK "Rückmeldung zum Sender einer Verzögerungsanforderung (Triebstrangskoordinator) bezüglich Prüfung der Checksumme, des Botschaftszählers, des langen Timeout und DLC. Wird auch gesetzt bei Verzögerungsanforderung größer einer applizierbaren Schwelle.
";
CM_ SG_ 262 ESP_Lenkeingriff_ADS "Im Falle eines fahrzeugstabilisierenden Lenkeingriffs des ADS-Systems soll ACC/GRA deaktiviert werden.

Im MQB wird dieses Signal nicht unterstützt!";
CM_ SG_ 262 ESP_Prefill_ausgeloest "MLB: Verwendung/Bedienung ab D4
zeigt, ob die Funktion Prefill (aufgrund Fahrpedalgradient) ausgelöst wird; zeigt keinen Funktionszustand bezüglich Fehlerstilllegung

MQB: Wird gesetzt bei jeder Art von aktivem Prefill";
CM_ SG_ 262 ESP_QBit_Bremsdruck "QBit des Bremsdrucks. Gesetzt bei Ersatzwert, Init oder Fehler.";
CM_ SG_ 262 ESP_QBit_Fahrer_bremst "Gültigkeit der Bremsdruckschwelleninformation des Signals ESP_Fahrer_bremst vom ESP SG
0x1 = Druckschwelleninformation kann noch nicht oder aufgrund eines Fehlers nicht ausgegeben werden
";
CM_ SG_ 262 ESP_Rueckwaertsfahrt_erkannt "nur bei AU57x und AU416 sowie Audi B8PA
Info, ob Rückwärtsfahrt über internen Algorithmus sicher erkannt

Im MQB wird das Signal nicht unterstützt!";
CM_ SG_ 262 ESP_Schwelle_Unterdruck "Verwendung im MQB für HBV-Projekte oder wenn für St/St ein Unterdrucksensor verbaut ist";
CM_ SG_ 262 ESP_StartStopp_Info "Stopp-Freigabe und Start-Anforderung an den Start-Stopp-Koordinator";
CM_ SG_ 262 ESP_Status_Anfahrhilfe "Funktionsstatus des Berganfahrassistenten
MQB: Auswertung im Getriebe zwecks Standabkopplung";
CM_ SG_ 262 ESP_Status_Bremsdruck "MLB: Bei gesetztem Bit liegt p > ca. 2 bar an, hervorgerufen durch Fahrer, ASR, FZR, ECD, Bremsregler ... bei Abfall des Bits ist p < X bar, bei aktivem ECD-Eingriff Ende des Eingriffs 

Weiterführende Informationen im Lastenheft spezifiziert und in der";
CM_ SG_ 262 ESP_Status_Bremsentemp "ECD-Bremsscheibentemperaturmodell. Rückmeldung für Sender einer ECD Verzögerungsanforderung, ohne Fehlereintrag im ESP";
CM_ SG_ 262 ESP_Verz_EPB_aktiv "Bei gesetztem Bit wird die Verzögerungsanforderung von EPB umgesetzt.";
CM_ SG_ 262 ESP_Verz_TSK_aktiv "Rückmeldeinformation an den Triebsstrangkoordinator/ACC, dass die ECD-Verzögerungsanforderung aktuell umgesetzt wird";
CM_ SG_ 262 ESP_Verzoeg_EPB_verf "Bei gesetztem Bit ist der Verzögerungsregeler für EPB verfügbar.";

CM_ SG_ 914 ESP_07_CRC "Für MLB:
'Berechnung siehe Lastenheft 'Kommunikationsabsicherung für FlexRay und CAN''

Ab MQB und MLBevo:
'Berechnung siehe Lastenheft 'End-to-End Kommunikationsabsicherung''

Endwerte siehe Begleitdokument 'S-PDU Kennungsfolgen'";
CM_ SG_ 914 ESP_ACC_LDE "Verwendung/Bedienung ab Folgeprojekte D4, aber nicht im D4 selbst
Lebensdauerende für ACC-Bremsung erreicht";
CM_ SG_ 914 ESP_Allrad_Antrieb "Im MQB wird das Signal nicht unterstützt!";
CM_ SG_ 914 ESP_CM_Variante "Signal gibt an welche CM-Variante unterstuetzt wird. 
";
CM_ SG_ 914 ESP_Codierung_ADS "ESP gibt für Empfänger im Fahrzeug aus, ob ADS verbaut/nicht verbaut ist.

Im MQB wird das Signal nicht unterstützt!
";
CM_ SG_ 914 ESP_MKB_ausloesbar "ESP hat Funktion Multi-Kollisions-Bremsung freigeschaltet";
CM_ SG_ 914 ESP_nachtr_Stopp_Anf "Dieses Signal dient dem Motor als Trigger, dass ein nachträglicher Motorstopp eingeleitet werden kann, wenn es die Bedingungen des StSt Koordinators dies zulassen. ";
CM_ SG_ 914 ESP_OBD_Status "Dieses Bit steuert die MIL-Lampe an (Motorsteuergerät reicht diese Info an Kombi weiter).";
CM_ SG_ 914 ESP_Offroad_Modus "Nur VW526: Bei Offroad-Fahrzeugen kann über einen Schalter ein Offroadmodus gewählt werden, dieser wird hier angezeigt. Bei Offroad Plus- Fahrzeugen wird hier der Offroadmodus indirekt durch das Verteilergetriebe vorgegeben (ALR_Offroad = 1) und eingespie";
CM_ SG_ 914 ESP_Qualifizierung_Antriebsart "Signal for Bentley BY83x: ESP_wheel_drive_selector

Bit qualifiziert für neue Projekte (ab D4 ff.) das Signal 'ESP_Quattro_Antrieb', d.h. ist 'ESP_Qualifizierung_Antriebsart'
auf 0x1 gesetzt, ändert sich die bisherige Bedeutung des Signals 'ESP_Quattro";
CM_ SG_ 914 ESP_Rollenmodus_Deaktivieren "Zwang zum Abbruch des Rollenmodus mit anschließender ESP-Vollfunktion.
MQB: Zwang zum Abbruch des Rollenmodus in allen Funktionsteilnehmern (Empfänger) mit anschließender ESP-Vollfunktion (Sender).
Signal wird vom ESP dauerhaft mit gültigen Werten bedat";
CM_ SG_ 914 ESP_RTA_HL "Physikalischer Wertebereich +/-5%. Der Reifentoleranzabgleich bezieht sich auf das linke Vorderrad.

physikalischer Wert = ( (Hex-Wert - 0x7F) / 2048 )*100%

Im MQB wird das Signal nicht unterstützt!";
CM_ SG_ 914 ESP_RTA_HR "Physikalischer Wertebereich +/-5%. Der Reifentoleranzabgleich bezieht sich auf das linke Vorderrad.

physikalischer Wert = ( (Hex-Wert - 0x7F) / 2048 )*100%

Im MQB wird das Signal nicht unterstützt!";
CM_ SG_ 914 ESP_RTA_VR "Physikalischer Wertebereich +/-5%. Der Reifentoleranzabgleich bezieht sich auf das linke Vorderrad.

physikalischer Wert = ( (Hex-Wert - 0x7F) / 2048 )*100%

Im MQB wird das Signal nicht unterstützt!";
CM_ SG_ 914 ESP_Stat_FallBack_eBKV "Das Signal zeigt dem eBKV an, ob seine Rückfallebene im ESP verfügbar ist.";
CM_ SG_ 914 OBD_Fehler_Radsensor_HL "Für Motor-SG (gesetzliche Vorgabe)";
CM_ SG_ 914 OBD_Fehler_Radsensor_HR "Für Motor-SG (gesetzliche Vorgabe)";
CM_ SG_ 914 OBD_Fehler_Radsensor_VL "Für Motor-SG (gesetzliche Vorgabe)";
CM_ SG_ 914 OBD_Fehler_Radsensor_VR "Für Motor-SG (gesetzliche Vorgabe)";

CM_ SG_ 286 ESC_Bremsdruckgradient "Das Signal zeigt den vom Fahrer gedruckten Bremsdruckgradienten";
CM_ SG_ 286 ESP_08_CRC "Für MLB:
'Berechnung siehe Lastenheft 'Kommunikationsabsicherung für FlexRay und CAN''

Ab MQB und MLBevo:
'Berechnung siehe Lastenheft 'End-to-End Kommunikationsabsicherung''

Endwerte siehe Begleitdokument 'S-PDU Kennungsfolgen'";
CM_ SG_ 286 ESP_Abrutschen_Stillstand "Das ESP teilt über dieses Bit mit, dass ein Abrutschen im Stillstand erkannt wurde.

Im MQB wird das Signal nicht unterstützt!";
CM_ SG_ 286 ESP_ANB_CM_Rueckk_Umsetz "Das Signal dient als Rückmeldung zum ACC, dass eine angeforderte ANB-CM durchgeführt wird. Die positive Rückmeldung löst u.a. eine entsprechende Fahrerinformation im Kombiinstrument aus";
CM_ SG_ 286 ESP_Fahrer_tritt_ZBR_Schw "Rückmeldung des ESP an AWV, ob der Fahrer die aktuell gültige ZBR-Schwelle übertritt";
CM_ SG_ 286 ESP_Konsistenz_ACC_Botschaft "Rückmeldung zum Sender der Verzögerungsanforderung ACC bezüglich Prüfung CHK/CRC, BZ und langer Timeout. Wird auch gesetzt bei einer Verzögerungsanforderung größer als eine applizierbare Schwelle.

Im D4/C7: Botschaft ACC_05
Im MQB: Botschaft ACC_07";
CM_ SG_ 286 ESP_QBit_v_ref "QBit der Referenzgeschwindigkeit ESP_v_ref. Gesetzt bei Ersatzwert, Init oder Fehler.
Detailinformationen zu dem Signal sind dem Lastenheft 'Signalexport - Funktionale Anforderungen an ESP' zu entnehmen - Signal ESP_St_v_fzg_ref";
CM_ SG_ 286 ESP_Stillstandsphase_erschoepft "Rückmeldung vom ESP, dass eine angefordertes sicheres Halten im Stillstand nicht mehr länger möglich ist.";
CM_ SG_ 286 ESP_Tuerkontakt_Fahrertuer "Logischer Pegel der HW-Leitung zum Türkontaktschalter im ESP-SG.
0 > Schalter geschlossen
1 > Schalter offen

Ungefilterter und unplausibilisierter Status der HW-Leitung vom Fahrertür-Türkontaktschalter zum ESP.
Redundanz für Systemsicherheit notwend";
CM_ SG_ 286 ESP_v_ref "MLBevo:
Signal wird nur von einem BOSCH ESP System zur Verfügung gestellt. Exklusives Signal vom BOSCH ESP zum BOSCH Airbag für ROSEII Funktion und für Fahrwerkregelsysteme. 
Verwendung nur nach vorheriger Abstimmung mit den verantwortlichen EF Fachbere";
CM_ SG_ 286 ESP_v_ref_Fahrtrichtung "Signal stellt die Informationen über die Fahrtrichtung des Fahrzeuges dar. Sie wird als Vorzeichen der Referenzgeschwindigkeit ESP_v_ref interpretiert und basiert auf den Drehrichtungen der Räder.
Detailinformationen zu dem Signal sind dem Lastenheft 'Si";
CM_ SG_ 286 ESP_ZT_Rueckk_Umsetz "Das Signal dient als Rückmeldung zum ACC, dass eine angeforderte Zielbremsung/Teilbremsung durchgeführt wird. Die positive Rückmeldung löst u.a. eine entsprechende Fahrerinformation im Kombiinstrument aus";

CM_ SG_ 278 ESP_10_BZ "Botschaftszähler

Wird im Projekt D4 und D4Hybrid nicht verwendet!  Wird im D4 PA verwendet";
CM_ SG_ 278 ESP_10_CRC "Für MLB:
'Berechnung siehe Lastenheft 'Kommunikationsabsicherung für FlexRay und CAN''

Ab MQB und MLBevo:
'Berechnung siehe Lastenheft 'End-to-End Kommunikationsabsicherung''

Endwerte siehe Begleitdokument 'S-PDU Kennungsfolgen'

Wird im Projekt";
CM_ SG_ 278 ESP_HL_Fahrtrichtung "Drehrichtung Rad HL

Weiterführende Informationen im Lastenheft spezifiziert und in der entsprechenden Fachabteilung zu erfragen.

Wird im Projekt D4 und D4Hybrid nicht verwendet!  Wird im D4 PA verwendet";
CM_ SG_ 278 ESP_HR_Fahrtrichtung "Drehrichtung Rad HR

Weiterführende Informationen im Lastenheft spezifiziert und in der entsprechenden Fachabteilung zu erfragen.

Wird im Projekt D4 und D4Hybrid nicht verwendet!  Wird im D4 PA verwendet";
CM_ SG_ 278 ESP_QBit_Wegimpuls_HL "Qualifizierungsbit Wegimpulszähler HL

Wird im Projekt D4 und D4Hybrid nicht verwendet!  Wird im D4 PA verwendet";
CM_ SG_ 278 ESP_QBit_Wegimpuls_HR "Qualifizierungsbit Wegimpulszähler HR

Wird im Projekt D4 und D4Hybrid nicht verwendet!  Wird im D4 PA verwendet";
CM_ SG_ 278 ESP_QBit_Wegimpuls_VL "Qualifizierungsbit Wegimpulszähler VL

Wird im Projekt D4 und D4Hybrid nicht verwendet!  Wird im D4 PA verwendet";
CM_ SG_ 278 ESP_QBit_Wegimpuls_VR "Qualifizierungsbit Wegimpulszähler VR

Wird im Projekt D4 und D4Hybrid nicht verwendet!  Wird im D4 PA verwendet";
CM_ SG_ 278 ESP_VL_Fahrtrichtung "Drehrichtung Rad VL

Weiterführende Informationen im Lastenheft spezifiziert und in der entsprechenden Fachabteilung zu erfragen.

Wird im Projekt D4 und D4Hybrid nicht verwendet!  Wird im D4 PA verwendet";
CM_ SG_ 278 ESP_VR_Fahrtrichtung "Drehrichtung Rad VR

Weiterführende Informationen im Lastenheft spezifiziert und in der entsprechenden Fachabteilung zu erfragen.

Wird im Projekt D4 und D4Hybrid nicht verwendet!  Wird im D4 PA verwendet";
CM_ SG_ 278 ESP_Wegimpuls_HL "Wegimpulszähler HL.
Anzahl der Wegimpulse Hinterrad links (steigende und fallende Flanke)
Zähler läuft grundsätzlich vorwärts, auch bei Rückwärtsfahrt.
Nach SG-Reset ist immer, ohne Ausnahme, 1mal der Init Wert 1021 zu senden.

Wird im Projekt D4 und";
CM_ SG_ 278 ESP_Wegimpuls_HR "Wegimpulszähler HR.
Anzahl der Wegimpulse Hinterrad rechts (steigende und fallende Flanke)
Zähler läuft grundsätzlich vorwärts, auch bei Rückwärtsfahrt.
Nach SG-Reset ist immer, ohne Ausnahme, 1mal der Init Wert 1021 zu senden.

Wird im Projekt D4 un";
CM_ SG_ 278 ESP_Wegimpuls_VL "Wegimpulszähler VL.
Anzahl der Wegimpulse Vorderrad links (steigende und fallende Flanke)
Zähler läuft grundsätzlich vorwärts, auch bei Rückwärtsfahrt.
Nach SG-Reset ist immer, ohne Ausnahme, 1mal der Init Wert 1021 zu senden.

Wird im Projekt D4 und";
CM_ SG_ 278 ESP_Wegimpuls_VR "Wegimpulszähler VR.
Anzahl der Wegimpulse Vorderrad rechts (steigende und fallende Flanke)
Zähler läuft grundsätzlich vorwärts, auch bei Rückwärtsfahrt.
Nach SG-Reset ist immer, ohne Ausnahme, 1mal der Init Wert 1021 zu senden.

Wird im Projekt D4 un";

CM_ SG_ 138 BR_Status_Quer_ESP "Statusmaschine für Quersperre";
CM_ SG_ 138 BR_Vorg_Allrad_Max "Max. Vorgabegrenzwert des Arbeitsbereiches der Kupplung durch das ESP
MQB Haldex: 100% Moment entsprechen 2000 Nm
MLBevo: Normierfaktor ALR_Norm_Mom_Max beachten
MLB: Wird im Projekt D4 und D4Hybrid nicht verwendet!";
CM_ SG_ 138 BR_Vorg_Allrad_Min "Min. Vorgabegrenzwert des Arbeitsbereiches der Kupplung durch das ESP
MQB Haldex: 100% Moment entsprechen 2000 Nm
MLBevo: Normierfaktor ALR_Norm_Mom_Max beachten
MLB: Wird im Projekt D4 und D4Hybrid nicht verwendet!";
CM_ SG_ 138 BR_Vorg_Quer_Max "Max. Vorgabegrenzwert des Arbeitsbereiches der Kupplung durch das ESP
MQB Haldex: 100% Moment entsprechen 2000 Nm";
CM_ SG_ 138 BR_Vorg_Quer_Min "Min. Vorgabegrenzwert des Arbeitsbereiches der Kupplung durch das ESP
MQB Haldex: 100% Moment entsprechen 2000 Nm";
CM_ SG_ 138 ESP_14_Anf_Lenkmomoffset_DSR "Angeforderter Lenkmomentenoffset durch die Funktion DSR

Wird zu D4 PA verwendet!";
CM_ SG_ 138 ESP_14_BZ "
Wird zu D4 PA verwendet!";
CM_ SG_ 138 ESP_14_CRC "Für MLB:
'Berechnung siehe Lastenheft 'Kommunikationsabsicherung für FlexRay und CAN''

Ab MQB und MLBevo:
'Berechnung siehe Lastenheft 'End-to-End Kommunikationsabsicherung''

Endwerte siehe Begleitdokument 'S-PDU Kennungsfolgen'

Wird zu D4 PA v";
CM_ SG_ 138 ESP_14_Sendestatus "Gibt den Sendestatus der ESP_14 an (notwendig für IL-Unterstützung)";
CM_ SG_ 138 ESP_14_Status_DSR "Status des ABS/ESP bzgl. Verfügbarkeit DSR-Funktionalität

Wird zu D4 PA verwendet!";
CM_ SG_ 138 ESP_14_VZ_Anf_Lenkmomoffset_DSR "Vorzeichen des durch die Funktion DSR angeforderten Lenkmomentenoffsets

Wird zu D4 PA verwendet!";

CM_ SG_ 418 ESP_15_BZ "Botschaftszähler";
CM_ SG_ 418 ESP_15_CRC "Für MLB:
'Berechnung siehe Lastenheft 'Kommunikationsabsicherung für FlexRay und CAN''

Ab MQB und MLBevo:
'Berechnung siehe Lastenheft 'End-to-End Kommunikationsabsicherung''

Endwerte siehe Begleitdokument 'S-PDU Kennungsfolgen'

Wird im Projekt";
CM_ SG_ 418 ESP_Haltemoment "Zeigt in Abhängigkeit von ESP_Index_Haltemoment das notwendige Summen-Radmoment an (bergab: Bremsmoment; bergauf: Antriebsmoment), das mindestens notwendig ist um das Fahrzeug an der aktuellen Neigung zu halten.";
CM_ SG_ 418 ESP_Index_Haltemoment "Zeigt an, ob das Summen-Radmoment von ESP_Haltemoment ein Bremsmoment (bergab) oder ein Antriebsmoment (bergauf) darstellt.";
CM_ SG_ 418 HMS_aktives_System "Zeigt an, von welchem System die Anforderung gerade umgesetzt wird.";
CM_ SG_ 418 HMS_Anforderung_GE "Fordert vom Getriebe bestimmte Schaltstellungen an.";
CM_ SG_ 418 HMS_Fehlerstatus "Zeigt den Fehlerstatus des Haltemanagementsystems HMS an.
Details zu den Werten 3/4:
3=Systemeinschränkung, Parken EPB oder GSG nicht möglich
4=Systemstörung bzw. Parken EPB und GSG nicht möglich  ";
CM_ SG_ 418 HMS_halten_nicht_verfuegbar "Rueckmeldung HMS-Teilfunktion 'Halten' nicht verfuegbar.";
CM_ SG_ 418 HMS_Konsistenz_ACC "Zeigt an, ob die Kommunikation und die Anforderungen plausibel sind.";
CM_ SG_ 418 HMS_Konsistenz_EBKV "Zeigt an, ob die Kommunikation und die Anforderungen plausibel sind.
";
CM_ SG_ 418 HMS_Konsistenz_GE "Zeigt an, ob die Kommunikation und die Anforderungen plausibel sind.";
CM_ SG_ 418 HMS_Konsistenz_HVLM "Zeigt an, ob die Kommunikation und die Anforderungen plausibel sind.";
CM_ SG_ 418 HMS_Konsistenz_IPA "Zeigt an, ob die Kommunikation und die Anforderungen plausibel sind.
";
CM_ SG_ 418 HMS_Konsistenz_MO "Zeigt an, ob die Kommunikation und die Anforderungen plausibel sind.";
CM_ SG_ 418 HMS_Konsistenz_RCTA "Zeigt an, ob die Kommunikation und die Anforderungen plausibel sind.";
CM_ SG_ 418 HMS_Konsistenz_STA "Zeigt an, ob die Kommunikation und die Anforderungen plausibel sind.";
CM_ SG_ 418 HMS_Notstopp_Status "Statusinformation des Notstoppsystems an die beteiligten Systeme.";
CM_ SG_ 418 HMS_P_beibehalten_GE "Fordert das Getriebe auf in Stellung 'P' zu bleiben.";
CM_ SG_ 418 HMS_parken_nicht_verfuegbar "Rueckmeldung HMS-Teilfunktionen 'Parken' nicht verfuegbar.";
CM_ SG_ 418 HMS_Stillstand "Das Signal zeigt, basierend auf den vier ESP-Raddrehzahlinformatioen, gefiltert und/oder entprellt mehrstufig den Fahrzeuggeschwindigkeitszustand an.";
CM_ SG_ 418 HMS_Systemstatus "Zeigt den aktuellen Systemstatus des HMS an.";
CM_ SG_ 418 NL_PRIM_STP_01_Status "Das Primär- Bremsregelsystem übermittelt seinen Systemstatus an zFAS und Sekundär- Bremsregelsystem. 

Der Staupilot ermittelt sich über den Status des Primär-und des Sekundärbremsregelsystems den Gesamtzustand des Notlaufreglers. ";

CM_ SG_ 178 ESP_HL_Radgeschw_02 "Radgeschwindigkeit hinten links";
CM_ SG_ 178 ESP_HR_Radgeschw_02 "Radgeschwindigkeit hinten rechts";
CM_ SG_ 178 ESP_VL_Radgeschw_02 "Radgeschwindigkeit vorne links";
CM_ SG_ 178 ESP_VR_Radgeschw_02 "Radgeschwindigkeit vorne rechts";

CM_ SG_ 1629 BR_QBit_Reifenumfang "Gesetzt bei Ersatzwert, Init oder Fehler.";
CM_ SG_ 1629 BR_Reifenumfang "Mittlerer Radumfang gerechnet in Millimeter.
Von der Bremse plausibilisierter Wert (Kopie von KBI_Reifenumfang wenn dieser plausibel) oder Ersatzwert aus Bremse wenn KBI_Reifenumfang unplausibel. Bitte das QBit beachten!";
CM_ SG_ 1629 BR_Systemart "Identifikation des verbauten Bremssystems

Dient dem Kombi zur Plausibilisierung";
CM_ SG_ 1629 ESP_20_CRC "Für MLB:
'Berechnung siehe Lastenheft 'Kommunikationsabsicherung für FlexRay und CAN''

Ab MQB und MLBevo:
'Berechnung siehe Lastenheft 'End-to-End Kommunikationsabsicherung''

Endwerte siehe Begleitdokument 'S-PDU Kennungsfolgen'";
CM_ SG_ 1629 ESP_Charisma_FahrPr "MLBevo: Aktuelles Fahrprogramm des Charisma-Teilnehmers (siehe Systemlastenheft Drive Select)
MQB: Istwert der Kennlinie (siehe Systemlastenheft MQB FPA)";
CM_ SG_ 1629 ESP_Charisma_Status "Systemstatus des Charismateilnehmers

Wert 0x3 ist nur für Fahrzeuge ab MQB relevant";
CM_ SG_ 1629 ESP_Dachrelingsensor "Erkennung auf Verbau des Dachrelingsensors und Dachquerträger.";
CM_ SG_ 1629 ESP_SpannungsAnf_02 "Forderung des ESP-SG's zur Spannungsanhebung.";
CM_ SG_ 1629 ESP_Stoppverbot_Anz_01 "Dieses Signal gibt die detaillierte Begründung für ein Stoppverbot vom Bremsensteuergerät an.";
CM_ SG_ 1629 ESP_Stoppverbot_Anz_02 "Dieses Signal gibt die detaillierte Begründung für ein Stoppverbot vom Bremsensteuergerät an.";
CM_ SG_ 1629 ESP_Stoppverbot_Anz_03 "Dieses Signal gibt die detaillierte Begründung für ein Stoppverbot vom Bremsensteuergerät an.";
CM_ SG_ 1629 ESP_Stoppverbot_Anz_04 "Dieses Signal gibt die detaillierte Begründung für ein Stoppverbot vom Bremsensteuergerät an.";
CM_ SG_ 1629 ESP_Stoppverbot_Anz_05 "Dieses Signal gibt die detaillierte Begründung für ein Stoppverbot vom Bremsensteuergerät an.";
CM_ SG_ 1629 ESP_Stoppverbot_Anz_06 "Dieses Signal gibt die detaillierte Begründung für ein Stoppverbot vom Bremsensteuergerät an.";
CM_ SG_ 1629 ESP_Stoppverbot_Anz_07 "Dieses Signal gibt die detaillierte Begründung für ein Stoppverbot vom Bremsensteuergerät an.";
CM_ SG_ 1629 ESP_Stoppverbot_Anz_08 "Dieses Signal gibt die detaillierte Begründung für ein Stoppverbot vom Bremsensteuergerät an.";
CM_ SG_ 1629 ESP_Stoppverbot_Anz_Std "Dieses Signal gibt die detaillierte Begründung für ein Stoppverbot vom Bremsensteuergerät an.";
CM_ SG_ 1629 ESP_Wiederstart_Anz_01 "Dieses Signal gibt die detaillierte Begründung für einen Wiederstart vom Bremsensteuergerät an. ";
CM_ SG_ 1629 ESP_Wiederstart_Anz_02 "Dieses Signal gibt die detaillierte Begründung für einen Wiederstart vom Bremsensteuergerät an. ";
CM_ SG_ 1629 ESP_Wiederstart_Anz_03 "Dieses Signal gibt die detaillierte Begründung für einen Wiederstart vom Bremsensteuergerät an. ";
CM_ SG_ 1629 ESP_Wiederstart_Anz_04 "Dieses Signal gibt die detaillierte Begründung für einen Wiederstart vom Bremsensteuergerät an.";
CM_ SG_ 1629 ESP_Zaehnezahl "Konstanter Wert der Zähnezahl des verwendeten Impulsrades wird ausgegeben, jeder Empfänger der Wegimpulse muss die Zähnezahl einlesen, um eine volle Umdrehung des Rades zu erkennen. 

Weiterführende Informationen im Lastenheft spezifiziert und in der en";
CM_ SG_ 1629 HDC_Charisma_FahrPr "MLBevo: Aktuelles Fahrprogramm des Charisma-Teilnehmers (siehe Systemlastenheft Drive Select)
MQB: Istwert der Kennlinie (siehe Systemlastenheft MQB FPA)";
CM_ SG_ 1629 HDC_Charisma_Status "Systemstatus des Charismateilnehmers

Wert 0x3 ist nur für Fahrzeuge ab MQB relevant";

CM_ SG_ 253 ABS_Bremsung "Antiblockiersystem, Bit zeigt auch Druckabbau an (z.B. ESP hat zuviel Druck aufgebaut oder ungebremste Regelung auf Bahnübergang)
Weiterführende Informationen im Lastenheft spezifiziert und in der entsprechenden Fachabteilung zu erfragen.";
CM_ SG_ 253 ASR_Anf "MLB: Die Momentenanforderung 'ASR_MSR_Moment_schnell' und 'ASR_Moment_langsam' sind auszuführen
MQB: Die Momentenanforderung 'BR_Eingriffsmoment' ist auszuführen";
CM_ SG_ 253 ASR_Schalteingriff "Wunsch an das Getriebe während einer ASR Regelung

MLB: Es wird nur 0x0 und 0x1 genutzt

";
CM_ SG_ 253 ASR_Tastung_passiv "ASR deaktiviert oder Schwellen geändert (projektabhängig)
Weiterführende Informationen im Lastenheft spezifiziert und in der entsprechenden Fachabteilung zu erfragen.
";
CM_ SG_ 253 BR_Eingriffsmoment "Einheitenloser Wert! Faktor in MO_Faktor_Momente_02 in Motor_Code_01 beachten!
Schnelle reduzierende (ASR) oder erhöhende (MSR) Momentanforderung an den Motor.";
CM_ SG_ 253 EBV_Eingriff "Elektronische Bremskraftverteilung, aktueller Eingriff (Druckhalten, Druckabbau)

Im MLB: kein ABS / ESP-Eingriff ???";
CM_ SG_ 253 EDS_Eingriff "Elektronische Differentialsperre";
CM_ SG_ 253 ESC_Reku_Freigabe "Mit diesem Bit wird die Rekuperation im Motorsteuergerät erlaubt. Bei Ausfall ESC wird Rekuperation nicht freigegeben.";
CM_ SG_ 253 ESC_v_Signal_Qualifier_High_Low "Das Qualifizerungssignal ESC_v_Signal_Qualifier_High_Low gibt eine Information über die Güte der vom Bremsregelsystem ausgegebenen Geschwindigkeitsinformation 'mittlere Geschwindigkeit', wobei Vertrauensbereiche für das ausgegebene Geschwindigkeitssignal ";
CM_ SG_ 253 ESP_21_CRC "Für MLB:
'Berechnung siehe Lastenheft 'Kommunikationsabsicherung für FlexRay und CAN''

Ab MQB und MLBevo:
'Berechnung siehe Lastenheft 'End-to-End Kommunikationsabsicherung''

Endwerte siehe Begleitdokument 'S-PDU Kennungsfolgen'";
CM_ SG_ 253 ESP_Anhaltevorgang_ACC_aktiv "Zeigt an, ob ACC-Anhaltevorgang aktiv";
CM_ SG_ 253 ESP_ASP "MLB: Anhaenger-Stabilisierungs-Programm
MQB: Gespannstabilisierung";
CM_ SG_ 253 ESP_AWV3_Brems_aktiv "Teil-, Ziel- oder Notbremsung wird im ESP für AWV3 umgesetzt (das MSG nutzt diese Info für den Abwurf der GRA-Regelung).";
CM_ SG_ 253 ESP_Diagnose "MLB: Nach Diagnoseende wird ein SW-Reset ausgelöst welcher einen Kommunikatiosausfall für max. 150ms verursacht. Dies ist bei SG mit verschärfter Timeoutüberwachung (nicht nach Konzern-LH) zu beachten.

MQB: Weiterführende Informationen im Lastenheft sp";
CM_ SG_ 253 ESP_Eingriff "Eingriff des Fahrdynamikreglers";
CM_ SG_ 253 ESP_Haltebestaetigung "Rückmeldung vom ESP-SG, dass das Fahrzeug aufgrund einer externen Bremsanforderung (z. B. ACC, PLA, ANB, o. ä.) abgebremst wurde und im Stillstand gehalten wird.";
CM_ SG_ 253 ESP_MKB_Abbruch_Geschw "Im Falle einer Multikollisionsbremsung teilt das ESP den Abbruch der MKB aufgrund der unteren Geschwindigkeitsschwelle mit.";
CM_ SG_ 253 ESP_PLA_Bremseingriff "Signalisierung des aktiven Bremseingriffes des ESP aufgrund einer Bremsanforderung vom PLA.";
CM_ SG_ 253 ESP_QBit_v_Signal "Geschwindigkeit wird vom ABS/ASR oder ESP aus Ersatzwerten errechnet, wenn Bit gesetzt ist. Güte des Signals ist verändert.";
CM_ SG_ 253 ESP_Systemstatus "Fehler steht für Stillegung ESP mit Fehlereintrag.

MLB: Flag wird bei Unterspannung im Stand bis einmalig 6km/h (AU48x) oder 10 km/h (AU641, AU57x) überschritten nicht gesetzt (Ausblendung Startvorgang)
Im AU64x, AU57x gilt ESP D4 Funktionsanforderung";
CM_ SG_ 253 ESP_Tastung_passiv "ESP deaktiviert oder Schwellen geändert (projektabhängig)
Weiterführende Informationen im Lastenheft spezifiziert und in der entsprechenden Fachabteilung zu erfragen.";
CM_ SG_ 253 ESP_v_Signal "Geschwindigkeitssignal vom ABS/ASR oder ESP. Mittelwert der angetriebenen Räder.
Bei MSR oder ABS Eingriffen wird die ABS-Referenzgeschwindigkeit für >= 200ms eingespiegelt (Zeit wird mit Aktiv-Flanke der Funktionsbits getriggert)

MQB: Bei Frontantrie";
CM_ SG_ 253 ESP_Vorsteuerung "zur Unterscheidung zwischen ESP-Vorsteuermaßnahmen und ESP-Regeleingriffen";
CM_ SG_ 253 MSR_Anf "MLB: Die Momentenanforderung 'ASR_MSR_Moment_schnell' ist auszuführen.
MQB: Die Momentenanforderung 'BR_Eingriffsmoment' ist auszuführen";
CM_ SG_ 253 OBD_Schlechtweg "Für Ausblendung der Zündaussetzererkennung im Motorsteuergerät (Otto). Bit wird gesetzt, wenn Rad-Drehbeschleunigung im ESP > Grenzwert ist. Vorteil gegenüber Radgeschwindigkeiten, dass ESP alle 2 ms dynamisch die Rad-Drehbeschleunigung errechnet und dem ";
BA_DEF_REL_ BU_SG_REL_  "GenSigTimeoutTime" INT 0 65535;
BA_DEF_ BO_  "DiagRequest" ENUM "No", "Yes";
BA_DEF_ BO_  "DiagResponse" ENUM "No", "Yes";
BA_DEF_ BO_  "DiagState" ENUM "No", "Yes";
BA_DEF_ BO_  "GenMsgChkConstant" HEX 0 4095;
BA_DEF_ BO_  "GenMsgCycleTime" INT 0 65535;
BA_DEF_ BO_  "GenMsgCycleTimeFast" INT 0 65535;
BA_DEF_ BO_  "GenMsgDelayTime" INT 0 100000;
BA_DEF_ BO_  "GenMsgILSupport" ENUM "No", "Yes";
BA_DEF_ BO_  "GenMsgNrOfRepetition" INT 0 100;
BA_DEF_ BO_  "GenMsgPDUConstants" STRING;
BA_DEF_ BO_  "GenMsgSendType" ENUM "Cyclic", "not_used", "not_used", "not_used", "not_used", "not_used", "not_used", "IfActive", "NoMsgSendType";
BA_DEF_ BO_  "GenMsgStartDelayTime" INT 0 100000;
BA_DEF_ BO_  "NmMessage" ENUM "No", "Yes";
BA_DEF_ BO_  "NmhMessage" ENUM "No", "Yes";
BA_DEF_ BO_  "MsgType" ENUM "Application", "NM ", "NMH", "TP2.0", "ISO-TP ", "BAP", "EID", "KS";
BA_DEF_ BO_  "VAGTP20_API" HEX 0 255;
BA_DEF_ BO_  "VAGTP20_DynConnection" ENUM "No", "Yes";
BA_DEF_ BO_  "VAGTP20_DynSetup" ENUM "No", "Yes";
BA_DEF_ BO_  "VAGTP20_StatConnection" ENUM "No", "Yes";
BA_DEF_ SG_  "GenSigActiveRepetitions" INT -2147483648 2147483647;
BA_DEF_ SG_  "GenSigInactiveValue" INT -2147483648 2147483647;
BA_DEF_ SG_  "GenSigSendType" ENUM "Cyclic", "OnWrite", "OnWriteWithRepetition", "OnChange", "OnChangeWithRepetition", "IfActive", "IfActiveWithRepetition", "NoSigSendType", "OnChangeAndIfActive", "OnChangeAndIfActiveWithRepetition";
BA_DEF_ SG_  "GenSigStartValue" INT -2147483648 2147483647;
BA_DEF_ SG_  "NWM-WakeupAllowed" ENUM "No", "Yes";
BA_DEF_ SG_  "GenSigFuncType" ENUM "NoFunction", "MsgCounter", "CRC-8", "XOR", "XOR-2", "DatedBit", "SW-Kl15", "CHK", "Constant", "Protocol", "CRC-8-SAE_J1850";
BA_DEF_ SG_  "GenSigSwitchedByIgnition" ENUM "No", "Yes";
BA_DEF_ SG_  "Fehlerwert" HEX 0 2147483647;
BA_DEF_ SG_  "GenSigMissingSourceValue" HEX 0 2147483647;
BA_DEF_DEF_REL_  "GenSigTimeoutTime" 0;
BA_DEF_DEF_  "DiagRequest" "No";
BA_DEF_DEF_  "DiagResponse" "No";
BA_DEF_DEF_  "DiagState" "No";
BA_DEF_DEF_  "GenMsgChkConstant" 0;
BA_DEF_DEF_  "GenMsgCycleTime" 0;
BA_DEF_DEF_  "GenMsgCycleTimeFast" 0;
BA_DEF_DEF_  "GenMsgDelayTime" 0;
BA_DEF_DEF_  "GenMsgILSupport" "No";
BA_DEF_DEF_  "GenMsgNrOfRepetition" 0;
BA_DEF_DEF_  "GenMsgPDUConstants" "";
BA_DEF_DEF_  "GenMsgSendType" "NoMsgSendType";
BA_DEF_DEF_  "GenMsgStartDelayTime" 0;
BA_DEF_DEF_  "NmMessage" "No";
BA_DEF_DEF_  "NmhMessage" "No";
BA_DEF_DEF_  "MsgType" "Application";
BA_DEF_DEF_  "VAGTP20_API" 0;
BA_DEF_DEF_  "VAGTP20_DynConnection" "No";
BA_DEF_DEF_  "VAGTP20_DynSetup" "No";
BA_DEF_DEF_  "VAGTP20_StatConnection" "No";
BA_DEF_DEF_  "GenSigActiveRepetitions" 0;
BA_DEF_DEF_  "GenSigInactiveValue" 0;
BA_DEF_DEF_  "GenSigSendType" "NoSigSendType";
BA_DEF_DEF_  "GenSigStartValue" 0;
BA_DEF_DEF_  "NWM-WakeupAllowed" "No";
BA_DEF_DEF_  "GenSigFuncType" "NoFunction";
BA_DEF_DEF_  "GenSigSwitchedByIgnition" "Yes";
BA_DEF_DEF_  "Fehlerwert" 0;
BA_DEF_DEF_  "GenSigMissingSourceValue" 0;
BA_ "MsgType" BO_ 2617020934 6;
BA_ "MsgType" BO_ 2617020935 6;
BA_ "MsgType" BO_ 2617020936 6;
BA_ "MsgType" BO_ 2617020937 6;
BA_ "MsgType" BO_ 2617020938 6;
BA_ "MsgType" BO_ 2617020939 6;
BA_ "MsgType" BO_ 2617020940 6;
BA_ "MsgType" BO_ 2617020941 6;
BA_ "MsgType" BO_ 2617020960 6;
BA_ "MsgType" BO_ 2617020961 6;
BA_ "MsgType" BO_ 2617004544 6;
BA_ "MsgType" BO_ 2617004545 6;
BA_ "MsgType" BO_ 2617004546 6;
BA_ "MsgType" BO_ 2617004547 6;
BA_ "MsgType" BO_ 2617004548 6;
BA_ "MsgType" BO_ 2617004549 6;
BA_ "MsgType" BO_ 2617004550 6;
BA_ "MsgType" BO_ 2617004551 6;
BA_ "MsgType" BO_ 2617004552 6;
BA_ "MsgType" BO_ 2617004553 6;
BA_ "MsgType" BO_ 2617004554 6;
BA_ "MsgType" BO_ 2617004555 6;
BA_ "MsgType" BO_ 2617004556 6;
BA_ "MsgType" BO_ 2617004557 6;
BA_ "MsgType" BO_ 2617004558 6;
BA_ "MsgType" BO_ 2617004559 6;
BA_ "MsgType" BO_ 2617004560 6;
BA_ "MsgType" BO_ 2617004561 6;
BA_ "MsgType" BO_ 2617004562 6;
BA_ "MsgType" BO_ 2617004563 6;
BA_ "MsgType" BO_ 2617004564 6;
BA_ "MsgType" BO_ 2617004565 6;
BA_ "MsgType" BO_ 2617004566 6;
BA_ "MsgType" BO_ 2617004567 6;
BA_ "MsgType" BO_ 2617004568 6;
BA_ "MsgType" BO_ 2617004569 6;
BA_ "MsgType" BO_ 2617004570 6;
BA_ "MsgType" BO_ 2617004571 6;
BA_ "MsgType" BO_ 2617004572 6;
BA_ "MsgType" BO_ 2617004573 6;
BA_ "MsgType" BO_ 2617004574 6;
BA_ "MsgType" BO_ 2617004575 6;
BA_ "MsgType" BO_ 2617199104 6;
BA_ "MsgType" BO_ 2617199105 6;
BA_ "MsgType" BO_ 2617199106 6;
BA_ "GenMsgCycleTime" BO_ 1714 1000;
BA_ "GenMsgILSupport" BO_ 1714 1;
BA_ "GenMsgSendType" BO_ 1714 0;
BA_ "GenMsgCycleTime" BO_ 1520 200;
BA_ "GenMsgDelayTime" BO_ 1520 50;
BA_ "GenMsgILSupport" BO_ 1520 1;
BA_ "GenMsgSendType" BO_ 1520 0;
BA_ "GenMsgChkConstant" BO_ 260 5;
BA_ "GenMsgCycleTime" BO_ 260 20;
BA_ "GenMsgILSupport" BO_ 260 1;
BA_ "GenMsgPDUConstants" BO_ 260 "0x05,0x05,0x05,0x05,0x05,0x05,0x05,0x05,0x05,0x05,0x05,0x05,0x05,0x05,0x05,0x05";
BA_ "GenMsgSendType" BO_ 260 0;
BA_ "GenMsgCycleTime" BO_ 781 50;
BA_ "GenMsgDelayTime" BO_ 781 5;
BA_ "GenMsgILSupport" BO_ 781 1;
BA_ "GenMsgSendType" BO_ 781 0;
BA_ "GenMsgCycleTime" BO_ 2527679683 2000;
BA_ "GenMsgDelayTime" BO_ 2527679683 100;
BA_ "GenMsgILSupport" BO_ 2527679683 1;
BA_ "GenMsgSendType" BO_ 2527679683 0;
BA_ "GenMsgChkConstant" BO_ 257 170;
BA_ "GenMsgCycleTime" BO_ 257 20;
BA_ "GenMsgILSupport" BO_ 257 1;
BA_ "GenMsgPDUConstants" BO_ 257 "0xaa,0xaa,0xaa,0xaa,0xaa,0xaa,0xaa,0xaa,0xaa,0xaa,0xaa,0xaa,0xaa,0xaa,0xaa,0xaa";
BA_ "GenMsgSendType" BO_ 257 0;
BA_ "GenMsgChkConstant" BO_ 262 7;
BA_ "GenMsgCycleTime" BO_ 262 20;
BA_ "GenMsgILSupport" BO_ 262 1;
BA_ "GenMsgPDUConstants" BO_ 262 "0x07,0x07,0x07,0x07,0x07,0x07,0x07,0x07,0x07,0x07,0x07,0x07,0x07,0x07,0x07,0x07";
BA_ "GenMsgSendType" BO_ 262 0;
BA_ "GenMsgChkConstant" BO_ 914 145;
BA_ "GenMsgCycleTime" BO_ 914 100;
BA_ "GenMsgILSupport" BO_ 914 1;
BA_ "GenMsgPDUConstants" BO_ 914 "0x91,0x91,0x91,0x91,0x91,0x91,0x91,0x91,0x91,0x91,0x91,0x91,0x91,0x91,0x91,0x91";
BA_ "GenMsgSendType" BO_ 914 0;
BA_ "GenMsgChkConstant" BO_ 286 210;
BA_ "GenMsgCycleTime" BO_ 286 20;
BA_ "GenMsgILSupport" BO_ 286 1;
BA_ "GenMsgPDUConstants" BO_ 286 "0xd2,0xd2,0xd2,0xd2,0xd2,0xd2,0xd2,0xd2,0xd2,0xd2,0xd2,0xd2,0xd2,0xd2,0xd2,0xd2";
BA_ "GenMsgSendType" BO_ 286 0;
BA_ "GenMsgChkConstant" BO_ 278 172;
BA_ "GenMsgCycleTime" BO_ 278 20;
BA_ "GenMsgILSupport" BO_ 278 1;
BA_ "GenMsgPDUConstants" BO_ 278 "0xac,0xac,0xac,0xac,0xac,0xac,0xac,0xac,0xac,0xac,0xac,0xac,0xac,0xac,0xac,0xac";
BA_ "GenMsgSendType" BO_ 278 0;
BA_ "GenMsgChkConstant" BO_ 138 212;
BA_ "GenMsgCycleTime" BO_ 138 1000;
BA_ "GenMsgCycleTimeFast" BO_ 138 10;
BA_ "GenMsgILSupport" BO_ 138 1;
BA_ "GenMsgPDUConstants" BO_ 138 "0xd4,0xd4,0xd4,0xd4,0xd4,0xd4,0xd4,0xd4,0xd4,0xd4,0xd4,0xd4,0xd4,0xd4,0xd4,0xd4";
BA_ "GenMsgSendType" BO_ 138 0;
BA_ "GenMsgCycleTime" BO_ 418 200;
BA_ "GenMsgDelayTime" BO_ 418 20;
BA_ "GenMsgILSupport" BO_ 418 1;
BA_ "GenMsgPDUConstants" BO_ 418 "0xcb,0x47,0xd7,0xd2,0x56,0x3e,0x20,0xea,0x6e,0x6d,0x8c,0x1b,0xdf,0x49,0xaa,0xab";
BA_ "GenMsgSendType" BO_ 418 0;
BA_ "GenMsgCycleTime" BO_ 178 10;
BA_ "GenMsgILSupport" BO_ 178 1;
BA_ "GenMsgSendType" BO_ 178 0;
BA_ "GenMsgCycleTime" BO_ 1629 1000;
BA_ "GenMsgDelayTime" BO_ 1629 200;
BA_ "GenMsgILSupport" BO_ 1629 1;
BA_ "GenMsgPDUConstants" BO_ 1629 "0xac,0xb3,0xab,0xeb,0x7a,0xe1,0x3b,0xf7,0x73,0xba,0x7c,0x9e,0x06,0x5f,0x02,0xd9";
BA_ "GenMsgSendType" BO_ 1629 0;
BA_ "GenMsgCycleTime" BO_ 253 20;
BA_ "GenMsgILSupport" BO_ 253 1;
BA_ "GenMsgPDUConstants" BO_ 253 "0xb4,0xef,0xf8,0x49,0x1e,0xe5,0xc2,0xc0,0x97,0x19,0x3c,0xc9,0xf1,0x98,0xd6,0x61";
BA_ "GenMsgSendType" BO_ 253 0;
BA_ "GenSigSwitchedByIgnition" SG_ 2617020934 DEV_Lenkhilfe_Resp_06_Data 0;
BA_ "GenSigSwitchedByIgnition" SG_ 2617020935 DEV_Lenkhilfe_Resp_07_Data 0;
BA_ "GenSigSwitchedByIgnition" SG_ 2617020936 DEV_Lenkhilfe_Resp_08_Data 0;
BA_ "GenSigSwitchedByIgnition" SG_ 2617020937 DEV_Lenkhilfe_Resp_09_Data 0;
BA_ "GenSigSwitchedByIgnition" SG_ 2617020938 DEV_Lenkhilfe_Resp_10_Data 0;
BA_ "GenSigSwitchedByIgnition" SG_ 2617020939 DEV_Lenkhilfe_Resp_11_Data 0;
BA_ "GenSigSwitchedByIgnition" SG_ 2617020940 DEV_Lenkhilfe_Resp_12_Data 0;
BA_ "GenSigSwitchedByIgnition" SG_ 2617020941 DEV_Lenkhilfe_Resp_13_Data 0;
BA_ "GenSigSwitchedByIgnition" SG_ 2617020960 DEV_Lenkhilfe_SIC_Resp_01_Data 0;
BA_ "GenSigSwitchedByIgnition" SG_ 2617020961 DEV_Lenkhilfe_SIC_Resp_02_Data 0;
BA_ "GenSigSwitchedByIgnition" SG_ 2617199104 DEV_RearView_Resp_00_Data 0;
BA_ "GenSigSwitchedByIgnition" SG_ 2617199105 DEV_RearView_Resp_01_Data 0;
BA_ "GenSigSwitchedByIgnition" SG_ 2617199106 DEV_RearView_Resp_02_Data 0;
BA_ "GenSigSendType" SG_ 1714 DGN_Verlernzaehler 0;
BA_ "GenSigSwitchedByIgnition" SG_ 1714 DGN_Verlernzaehler 0;
BA_ "GenSigSendType" SG_ 1714 KBI_Kilometerstand 0;
BA_ "GenSigStartValue" SG_ 1714 KBI_Kilometerstand 1048574;
BA_ "GenSigSwitchedByIgnition" SG_ 1714 KBI_Kilometerstand 0;
BA_ "Fehlerwert" SG_ 1714 KBI_Kilometerstand 1048575;
BA_ "GenSigSendType" SG_ 1714 Kombi_02_alt 0;
BA_ "GenSigStartValue" SG_ 1714 Kombi_02_alt 1;
BA_ "GenSigFuncType" SG_ 1714 Kombi_02_alt 5;
BA_ "GenSigSwitchedByIgnition" SG_ 1714 Kombi_02_alt 0;
BA_ "GenSigSendType" SG_ 1714 UH_Jahr 0;
BA_ "GenSigSwitchedByIgnition" SG_ 1714 UH_Jahr 0;
BA_ "GenSigSendType" SG_ 1714 UH_Minute 0;
BA_ "GenSigSwitchedByIgnition" SG_ 1714 UH_Minute 0;
BA_ "GenSigSendType" SG_ 1714 UH_Monat 0;
BA_ "GenSigSwitchedByIgnition" SG_ 1714 UH_Monat 0;
BA_ "Fehlerwert" SG_ 1714 UH_Monat 15;
BA_ "GenSigSendType" SG_ 1714 UH_Sekunde 0;
BA_ "GenSigSwitchedByIgnition" SG_ 1714 UH_Sekunde 0;
BA_ "GenSigSendType" SG_ 1714 UH_Stunde 0;
BA_ "GenSigSwitchedByIgnition" SG_ 1714 UH_Stunde 0;
BA_ "GenSigSendType" SG_ 1714 UH_Tag 0;
BA_ "GenSigSwitchedByIgnition" SG_ 1714 UH_Tag 0;
BA_ "GenSigSendType" SG_ 1714 Uhrzeit_01_alt 0;
BA_ "GenSigStartValue" SG_ 1714 Uhrzeit_01_alt 1;
BA_ "GenSigFuncType" SG_ 1714 Uhrzeit_01_alt 5;
BA_ "GenSigSwitchedByIgnition" SG_ 1714 Uhrzeit_01_alt 0;
BA_ "GenSigSendType" SG_ 1714 Vehicle_Driving_Cycle 0;
BA_ "GenSigSwitchedByIgnition" SG_ 1714 Vehicle_Driving_Cycle 0;
BA_ "GenSigSendType" SG_ 1520 BCM1_Stellgroesse_Kl_58s 3;
BA_ "GenSigStartValue" SG_ 1520 BCM1_Stellgroesse_Kl_58s 126;
BA_ "GenSigSwitchedByIgnition" SG_ 1520 BCM1_Stellgroesse_Kl_58s 0;
BA_ "Fehlerwert" SG_ 1520 BCM1_Stellgroesse_Kl_58s 127;
BA_ "GenSigSendType" SG_ 1520 DI_Display_Nachtdesign 3;
BA_ "GenSigSwitchedByIgnition" SG_ 1520 DI_Display_Nachtdesign 0;
BA_ "GenSigSendType" SG_ 1520 DI_Fotosensor 3;
BA_ "GenSigSwitchedByIgnition" SG_ 1520 DI_Fotosensor 0;
BA_ "GenSigSendType" SG_ 1520 DI_KL_58xd 3;
BA_ "GenSigStartValue" SG_ 1520 DI_KL_58xd 254;
BA_ "GenSigSwitchedByIgnition" SG_ 1520 DI_KL_58xd 0;
BA_ "Fehlerwert" SG_ 1520 DI_KL_58xd 255;
BA_ "GenSigSendType" SG_ 1520 DI_KL_58xs 3;
BA_ "GenSigStartValue" SG_ 1520 DI_KL_58xs 126;
BA_ "GenSigSwitchedByIgnition" SG_ 1520 DI_KL_58xs 0;
BA_ "Fehlerwert" SG_ 1520 DI_KL_58xs 127;
BA_ "GenSigSendType" SG_ 1520 DI_KL_58xt 3;
BA_ "GenSigStartValue" SG_ 1520 DI_KL_58xt 126;
BA_ "GenSigSwitchedByIgnition" SG_ 1520 DI_KL_58xt 0;
BA_ "Fehlerwert" SG_ 1520 DI_KL_58xt 127;
BA_ "GenSigSendType" SG_ 260 EPB_01_BZ 0;
BA_ "GenSigFuncType" SG_ 260 EPB_01_BZ 1;
BA_ "GenSigSwitchedByIgnition" SG_ 260 EPB_01_BZ 0;
BA_ "GenSigSendType" SG_ 260 EPB_01_CRC 0;
BA_ "GenSigFuncType" SG_ 260 EPB_01_CRC 2;
BA_ "GenSigSwitchedByIgnition" SG_ 260 EPB_01_CRC 0;
BA_ "GenSigSendType" SG_ 260 EPB_DAA_Randbed_erf 0;
BA_ "GenSigSwitchedByIgnition" SG_ 260 EPB_DAA_Randbed_erf 0;
BA_ "GenSigSendType" SG_ 260 EPB_Fehlerstatus 0;
BA_ "GenSigSwitchedByIgnition" SG_ 260 EPB_Fehlerstatus 0;
BA_ "GenSigSendType" SG_ 260 EPB_Freig_Verzoeg_Anf 0;
BA_ "GenSigSwitchedByIgnition" SG_ 260 EPB_Freig_Verzoeg_Anf 0;
BA_ "GenSigSendType" SG_ 260 EPB_Pedalweg_Kuppl 0;
BA_ "GenSigSwitchedByIgnition" SG_ 260 EPB_Pedalweg_Kuppl 0;
BA_ "Fehlerwert" SG_ 260 EPB_Pedalweg_Kuppl 255;
BA_ "GenSigSendType" SG_ 260 EPB_QBit_Laengsbeschleunigung 0;
BA_ "GenSigStartValue" SG_ 260 EPB_QBit_Laengsbeschleunigung 1;
BA_ "GenSigSwitchedByIgnition" SG_ 260 EPB_QBit_Laengsbeschleunigung 0;
BA_ "GenSigSendType" SG_ 260 EPB_QBit_Pedalweg_Kuppl 0;
BA_ "GenSigStartValue" SG_ 260 EPB_QBit_Pedalweg_Kuppl 1;
BA_ "GenSigSwitchedByIgnition" SG_ 260 EPB_QBit_Pedalweg_Kuppl 0;
BA_ "GenSigSendType" SG_ 260 EPB_QBit_Schalterpos 0;
BA_ "GenSigStartValue" SG_ 260 EPB_QBit_Schalterpos 1;
BA_ "GenSigSwitchedByIgnition" SG_ 260 EPB_QBit_Schalterpos 0;
BA_ "GenSigSendType" SG_ 260 EPB_Schalterposition 0;
BA_ "GenSigSwitchedByIgnition" SG_ 260 EPB_Schalterposition 0;
BA_ "Fehlerwert" SG_ 260 EPB_Schalterposition 3;
BA_ "GenSigSendType" SG_ 260 EPB_Spannkraft 0;
BA_ "GenSigStartValue" SG_ 260 EPB_Spannkraft 30;
BA_ "GenSigSwitchedByIgnition" SG_ 260 EPB_Spannkraft 0;
BA_ "Fehlerwert" SG_ 260 EPB_Spannkraft 31;
BA_ "GenSigSendType" SG_ 260 EPB_Status 0;
BA_ "GenSigSwitchedByIgnition" SG_ 260 EPB_Status 0;
BA_ "GenSigSendType" SG_ 260 EPB_Verzoeg_Anf 0;
BA_ "GenSigStartValue" SG_ 260 EPB_Verzoeg_Anf 166;
BA_ "GenSigSwitchedByIgnition" SG_ 260 EPB_Verzoeg_Anf 0;
BA_ "GenSigSendType" SG_ 781 EPB_Akustik 3;
BA_ "GenSigSwitchedByIgnition" SG_ 781 EPB_Akustik 0;
BA_ "GenSigSendType" SG_ 781 EPB_Autoholdlampe 3;
BA_ "GenSigSwitchedByIgnition" SG_ 781 EPB_Autoholdlampe 0;
BA_ "GenSigSendType" SG_ 781 EPB_Bremsbelag_Warn 0;
BA_ "GenSigSwitchedByIgnition" SG_ 781 EPB_Bremsbelag_Warn 0;
BA_ "GenSigSendType" SG_ 781 EPB_Fehlerlampe_BKL 3;
BA_ "GenSigSwitchedByIgnition" SG_ 781 EPB_Fehlerlampe_BKL 0;
BA_ "GenSigSendType" SG_ 781 EPB_Fehlerlampe_Gelb 3;
BA_ "GenSigSwitchedByIgnition" SG_ 781 EPB_Fehlerlampe_Gelb 0;
BA_ "GenSigSendType" SG_ 781 EPB_Fehlermeldungen 0;
BA_ "GenSigSwitchedByIgnition" SG_ 781 EPB_Fehlermeldungen 0;
BA_ "GenSigSendType" SG_ 781 EPB_Funktionslampe 3;
BA_ "GenSigSwitchedByIgnition" SG_ 781 EPB_Funktionslampe 0;
BA_ "GenSigSendType" SG_ 781 EPB_Texte 3;
BA_ "GenSigSwitchedByIgnition" SG_ 781 EPB_Texte 0;
BA_ "GenSigSendType" SG_ 2527679683 ESC_ASM_Data_1 0;
BA_ "GenSigSwitchedByIgnition" SG_ 2527679683 ESC_ASM_Data_1 0;
BA_ "GenSigSendType" SG_ 2527679683 ESC_ASM_Data_2 0;
BA_ "GenSigSwitchedByIgnition" SG_ 2527679683 ESC_ASM_Data_2 0;
BA_ "GenSigSendType" SG_ 2527679683 ESC_ASM_Data_3 0;
BA_ "GenSigSwitchedByIgnition" SG_ 2527679683 ESC_ASM_Data_3 0;
BA_ "GenSigSendType" SG_ 2527679683 ESC_ASM_Data_4 0;
BA_ "GenSigSwitchedByIgnition" SG_ 2527679683 ESC_ASM_Data_4 0;
BA_ "GenSigSendType" SG_ 2527679683 ESC_ASM_Data_5 0;
BA_ "GenSigSwitchedByIgnition" SG_ 2527679683 ESC_ASM_Data_5 0;
BA_ "GenSigSendType" SG_ 2527679683 ESC_ASM_Data_6 0;
BA_ "GenSigSwitchedByIgnition" SG_ 2527679683 ESC_ASM_Data_6 0;
BA_ "GenSigSendType" SG_ 2527679683 ESC_ASM_Ereignis 3;
BA_ "GenSigSwitchedByIgnition" SG_ 2527679683 ESC_ASM_Ereignis 0;
BA_ "GenSigSendType" SG_ 2527679683 ESC_ASM_Zeitstempel 3;
BA_ "GenSigStartValue" SG_ 2527679683 ESC_ASM_Zeitstempel 255;
BA_ "GenSigSwitchedByIgnition" SG_ 2527679683 ESC_ASM_Zeitstempel 0;
BA_ "GenSigSendType" SG_ 257 ESC_Motorstartverzoegerung 0;
BA_ "GenSigSwitchedByIgnition" SG_ 257 ESC_Motorstartverzoegerung 0;
BA_ "GenSigSendType" SG_ 257 ESC_SeitenwindAssistent_Eingriff 0;
BA_ "GenSigSwitchedByIgnition" SG_ 257 ESC_SeitenwindAssistent_Eingriff 0;
BA_ "GenSigSendType" SG_ 257 ESP_02_BZ 0;
BA_ "GenSigFuncType" SG_ 257 ESP_02_BZ 1;
BA_ "GenSigSwitchedByIgnition" SG_ 257 ESP_02_BZ 0;
BA_ "GenSigSendType" SG_ 257 ESP_02_CRC 0;
BA_ "GenSigFuncType" SG_ 257 ESP_02_CRC 2;
BA_ "GenSigSwitchedByIgnition" SG_ 257 ESP_02_CRC 0;
BA_ "GenSigSendType" SG_ 257 ESP_Anschleppstart_Freigabe 0;
BA_ "GenSigSwitchedByIgnition" SG_ 257 ESP_Anschleppstart_Freigabe 0;
BA_ "GenSigSendType" SG_ 257 ESP_Gierrate 0;
BA_ "GenSigSwitchedByIgnition" SG_ 257 ESP_Gierrate 0;
BA_ "Fehlerwert" SG_ 257 ESP_Gierrate 16383;
BA_ "GenSigSendType" SG_ 257 ESP_Laengsbeschl 0;
BA_ "GenSigStartValue" SG_ 257 ESP_Laengsbeschl 512;
BA_ "GenSigSwitchedByIgnition" SG_ 257 ESP_Laengsbeschl 0;
BA_ "Fehlerwert" SG_ 257 ESP_Laengsbeschl 1023;
BA_ "GenSigSendType" SG_ 257 ESP_Notbremsanzeige 0;
BA_ "GenSigSwitchedByIgnition" SG_ 257 ESP_Notbremsanzeige 0;
BA_ "GenSigSendType" SG_ 257 ESP_PLA_Abbruch 0;
BA_ "GenSigSwitchedByIgnition" SG_ 257 ESP_PLA_Abbruch 0;
BA_ "GenSigSendType" SG_ 257 ESP_QBit_Anf_Vert_Wank 0;
BA_ "GenSigStartValue" SG_ 257 ESP_QBit_Anf_Vert_Wank 1;
BA_ "GenSigSwitchedByIgnition" SG_ 257 ESP_QBit_Anf_Vert_Wank 0;
BA_ "GenSigSendType" SG_ 257 ESP_QBit_Gierrate 0;
BA_ "GenSigStartValue" SG_ 257 ESP_QBit_Gierrate 1;
BA_ "GenSigSwitchedByIgnition" SG_ 257 ESP_QBit_Gierrate 0;
BA_ "GenSigSendType" SG_ 257 ESP_QBit_Laengsbeschl 0;
BA_ "GenSigStartValue" SG_ 257 ESP_QBit_Laengsbeschl 1;
BA_ "GenSigSwitchedByIgnition" SG_ 257 ESP_QBit_Laengsbeschl 0;
BA_ "GenSigSendType" SG_ 257 ESP_QBit_Querb 0;
BA_ "GenSigStartValue" SG_ 257 ESP_QBit_Querb 1;
BA_ "GenSigSwitchedByIgnition" SG_ 257 ESP_QBit_Querb 0;
BA_ "GenSigSendType" SG_ 257 ESP_Querbeschleunigung 0;
BA_ "GenSigStartValue" SG_ 257 ESP_Querbeschleunigung 127;
BA_ "GenSigSwitchedByIgnition" SG_ 257 ESP_Querbeschleunigung 0;
BA_ "Fehlerwert" SG_ 257 ESP_Querbeschleunigung 255;
BA_ "GenSigSendType" SG_ 257 ESP_SpannungsAnf 0;
BA_ "GenSigSwitchedByIgnition" SG_ 257 ESP_SpannungsAnf 0;
BA_ "GenSigSendType" SG_ 257 ESP_Status_ESP_PLA 0;
BA_ "GenSigSwitchedByIgnition" SG_ 257 ESP_Status_ESP_PLA 0;
BA_ "GenSigSendType" SG_ 257 ESP_Stillstandsflag 0;
BA_ "GenSigSwitchedByIgnition" SG_ 257 ESP_Stillstandsflag 0;
BA_ "GenSigSendType" SG_ 257 ESP_VZ_Gierrate 0;
BA_ "GenSigSwitchedByIgnition" SG_ 257 ESP_VZ_Gierrate 0;
BA_ "GenSigSendType" SG_ 262 ECD_Bremslicht 0;
BA_ "GenSigSwitchedByIgnition" SG_ 262 ECD_Bremslicht 0;
BA_ "GenSigSendType" SG_ 262 ECD_Fehler 0;
BA_ "GenSigSwitchedByIgnition" SG_ 262 ECD_Fehler 0;
BA_ "GenSigSendType" SG_ 262 ECD_nicht_verfuegbar 0;
BA_ "GenSigStartValue" SG_ 262 ECD_nicht_verfuegbar 1;
BA_ "GenSigSwitchedByIgnition" SG_ 262 ECD_nicht_verfuegbar 0;
BA_ "GenSigSendType" SG_ 262 ESP_05_BZ 0;
BA_ "GenSigFuncType" SG_ 262 ESP_05_BZ 1;
BA_ "GenSigSwitchedByIgnition" SG_ 262 ESP_05_BZ 0;
BA_ "GenSigSendType" SG_ 262 ESP_05_CRC 0;
BA_ "GenSigFuncType" SG_ 262 ESP_05_CRC 2;
BA_ "GenSigSwitchedByIgnition" SG_ 262 ESP_05_CRC 0;
BA_ "GenSigSendType" SG_ 262 ESP_Anforderung_EPB 0;
BA_ "GenSigSwitchedByIgnition" SG_ 262 ESP_Anforderung_EPB 0;
BA_ "GenSigSendType" SG_ 262 ESP_Autohold_aktiv 0;
BA_ "GenSigSwitchedByIgnition" SG_ 262 ESP_Autohold_aktiv 0;
BA_ "GenSigSendType" SG_ 262 ESP_Autohold_Standby 0;
BA_ "GenSigSwitchedByIgnition" SG_ 262 ESP_Autohold_Standby 0;
BA_ "GenSigSendType" SG_ 262 ESP_BKV_Unterdruck 0;
BA_ "GenSigStartValue" SG_ 262 ESP_BKV_Unterdruck 254;
BA_ "GenSigSwitchedByIgnition" SG_ 262 ESP_BKV_Unterdruck 0;
BA_ "Fehlerwert" SG_ 262 ESP_BKV_Unterdruck 255;
BA_ "GenSigSendType" SG_ 262 ESP_Bremsdruck 0;
BA_ "GenSigStartValue" SG_ 262 ESP_Bremsdruck 100;
BA_ "GenSigSwitchedByIgnition" SG_ 262 ESP_Bremsdruck 0;
BA_ "Fehlerwert" SG_ 262 ESP_Bremsdruck 1023;
BA_ "GenSigSendType" SG_ 262 ESP_Bremsruck_AWV2 0;
BA_ "GenSigSwitchedByIgnition" SG_ 262 ESP_Bremsruck_AWV2 0;
BA_ "GenSigSendType" SG_ 262 ESP_Eingr_HL 0;
BA_ "GenSigSwitchedByIgnition" SG_ 262 ESP_Eingr_HL 0;
BA_ "GenSigSendType" SG_ 262 ESP_Eingr_HR 0;
BA_ "GenSigSwitchedByIgnition" SG_ 262 ESP_Eingr_HR 0;
BA_ "GenSigSendType" SG_ 262 ESP_Eingr_VL 0;
BA_ "GenSigSwitchedByIgnition" SG_ 262 ESP_Eingr_VL 0;
BA_ "GenSigSendType" SG_ 262 ESP_Eingr_VR 0;
BA_ "GenSigSwitchedByIgnition" SG_ 262 ESP_Eingr_VR 0;
BA_ "GenSigSendType" SG_ 262 ESP_Fahrer_bremst 0;
BA_ "GenSigSwitchedByIgnition" SG_ 262 ESP_Fahrer_bremst 0;
BA_ "GenSigSendType" SG_ 262 ESP_FStatus_Anfahrhilfe 0;
BA_ "GenSigSwitchedByIgnition" SG_ 262 ESP_FStatus_Anfahrhilfe 0;
BA_ "Fehlerwert" SG_ 262 ESP_FStatus_Anfahrhilfe 1;
BA_ "GenSigSendType" SG_ 262 ESP_HBA_aktiv 0;
BA_ "GenSigSwitchedByIgnition" SG_ 262 ESP_HBA_aktiv 0;
BA_ "GenSigSendType" SG_ 262 ESP_HDC_aktiv 0;
BA_ "GenSigSwitchedByIgnition" SG_ 262 ESP_HDC_aktiv 0;
BA_ "GenSigSendType" SG_ 262 ESP_HDC_Standby 0;
BA_ "GenSigSwitchedByIgnition" SG_ 262 ESP_HDC_Standby 0;
BA_ "GenSigSendType" SG_ 262 ESP_Konsistenz_AWV2 0;
BA_ "GenSigSwitchedByIgnition" SG_ 262 ESP_Konsistenz_AWV2 0;
BA_ "GenSigSendType" SG_ 262 ESP_Konsistenz_TSK 0;
BA_ "GenSigSwitchedByIgnition" SG_ 262 ESP_Konsistenz_TSK 0;
BA_ "GenSigSendType" SG_ 262 ESP_Lenkeingriff_ADS 0;
BA_ "GenSigSwitchedByIgnition" SG_ 262 ESP_Lenkeingriff_ADS 0;
BA_ "GenSigSendType" SG_ 262 ESP_Prefill_ausgeloest 0;
BA_ "GenSigSwitchedByIgnition" SG_ 262 ESP_Prefill_ausgeloest 0;
BA_ "GenSigSendType" SG_ 262 ESP_QBit_Bremsdruck 0;
BA_ "GenSigStartValue" SG_ 262 ESP_QBit_Bremsdruck 1;
BA_ "GenSigSwitchedByIgnition" SG_ 262 ESP_QBit_Bremsdruck 0;
BA_ "GenSigSendType" SG_ 262 ESP_QBit_Fahrer_bremst 0;
BA_ "GenSigStartValue" SG_ 262 ESP_QBit_Fahrer_bremst 1;
BA_ "GenSigSwitchedByIgnition" SG_ 262 ESP_QBit_Fahrer_bremst 0;
BA_ "GenSigSendType" SG_ 262 ESP_Rueckwaertsfahrt_erkannt 0;
BA_ "GenSigSwitchedByIgnition" SG_ 262 ESP_Rueckwaertsfahrt_erkannt 0;
BA_ "GenSigSendType" SG_ 262 ESP_Schwelle_Unterdruck 0;
BA_ "GenSigSwitchedByIgnition" SG_ 262 ESP_Schwelle_Unterdruck 0;
BA_ "GenSigSendType" SG_ 262 ESP_StartStopp_Info 0;
BA_ "GenSigSwitchedByIgnition" SG_ 262 ESP_StartStopp_Info 0;
BA_ "GenSigSendType" SG_ 262 ESP_Status_Anfahrhilfe 0;
BA_ "GenSigSwitchedByIgnition" SG_ 262 ESP_Status_Anfahrhilfe 0;
BA_ "GenSigSendType" SG_ 262 ESP_Status_Bremsdruck 0;
BA_ "GenSigSwitchedByIgnition" SG_ 262 ESP_Status_Bremsdruck 0;
BA_ "GenSigSendType" SG_ 262 ESP_Status_Bremsentemp 0;
BA_ "GenSigSwitchedByIgnition" SG_ 262 ESP_Status_Bremsentemp 0;
BA_ "GenSigSendType" SG_ 262 ESP_Verz_EPB_aktiv 0;
BA_ "GenSigSwitchedByIgnition" SG_ 262 ESP_Verz_EPB_aktiv 0;
BA_ "GenSigSendType" SG_ 262 ESP_Verz_TSK_aktiv 0;
BA_ "GenSigSwitchedByIgnition" SG_ 262 ESP_Verz_TSK_aktiv 0;
BA_ "GenSigSendType" SG_ 262 ESP_Verzoeg_EPB_verf 0;
BA_ "GenSigSwitchedByIgnition" SG_ 262 ESP_Verzoeg_EPB_verf 0;
BA_ "GenSigSendType" SG_ 914 ESP_07_BZ 0;
BA_ "GenSigFuncType" SG_ 914 ESP_07_BZ 1;
BA_ "GenSigSwitchedByIgnition" SG_ 914 ESP_07_BZ 0;
BA_ "GenSigSendType" SG_ 914 ESP_07_CRC 0;
BA_ "GenSigFuncType" SG_ 914 ESP_07_CRC 2;
BA_ "GenSigSwitchedByIgnition" SG_ 914 ESP_07_CRC 0;
BA_ "GenSigSendType" SG_ 914 ESP_ACC_LDE 0;
BA_ "GenSigSwitchedByIgnition" SG_ 914 ESP_ACC_LDE 0;
BA_ "GenSigSendType" SG_ 914 ESP_Allrad_Antrieb 0;
BA_ "GenSigFuncType" SG_ 914 ESP_Allrad_Antrieb 8;
BA_ "GenSigSwitchedByIgnition" SG_ 914 ESP_Allrad_Antrieb 0;
BA_ "GenSigSendType" SG_ 914 ESP_CM_Variante 0;
BA_ "GenSigSwitchedByIgnition" SG_ 914 ESP_CM_Variante 0;
BA_ "GenSigSendType" SG_ 914 ESP_Codierung_ADS 0;
BA_ "GenSigFuncType" SG_ 914 ESP_Codierung_ADS 8;
BA_ "GenSigSwitchedByIgnition" SG_ 914 ESP_Codierung_ADS 0;
BA_ "GenSigSendType" SG_ 914 ESP_MKB_ausloesbar 0;
BA_ "GenSigSwitchedByIgnition" SG_ 914 ESP_MKB_ausloesbar 0;
BA_ "GenSigSendType" SG_ 914 ESP_nachtr_Stopp_Anf 0;
BA_ "GenSigSwitchedByIgnition" SG_ 914 ESP_nachtr_Stopp_Anf 0;
BA_ "GenSigSendType" SG_ 914 ESP_OBD_Status 0;
BA_ "GenSigSwitchedByIgnition" SG_ 914 ESP_OBD_Status 0;
BA_ "GenSigSendType" SG_ 914 ESP_Offroad_Modus 0;
BA_ "GenSigSwitchedByIgnition" SG_ 914 ESP_Offroad_Modus 0;
BA_ "GenSigSendType" SG_ 914 ESP_Qualifizierung_Antriebsart 0;
BA_ "GenSigFuncType" SG_ 914 ESP_Qualifizierung_Antriebsart 8;
BA_ "GenSigSwitchedByIgnition" SG_ 914 ESP_Qualifizierung_Antriebsart 0;
BA_ "GenSigSendType" SG_ 914 ESP_Rollenmodus_Deaktivieren 0;
BA_ "GenSigSwitchedByIgnition" SG_ 914 ESP_Rollenmodus_Deaktivieren 0;
BA_ "GenSigSendType" SG_ 914 ESP_RTA_HL 0;
BA_ "GenSigStartValue" SG_ 914 ESP_RTA_HL 254;
BA_ "GenSigSwitchedByIgnition" SG_ 914 ESP_RTA_HL 0;
BA_ "Fehlerwert" SG_ 914 ESP_RTA_HL 255;
BA_ "GenSigSendType" SG_ 914 ESP_RTA_HR 0;
BA_ "GenSigStartValue" SG_ 914 ESP_RTA_HR 254;
BA_ "GenSigSwitchedByIgnition" SG_ 914 ESP_RTA_HR 0;
BA_ "Fehlerwert" SG_ 914 ESP_RTA_HR 255;
BA_ "GenSigSendType" SG_ 914 ESP_RTA_VR 0;
BA_ "GenSigStartValue" SG_ 914 ESP_RTA_VR 254;
BA_ "GenSigSwitchedByIgnition" SG_ 914 ESP_RTA_VR 0;
BA_ "Fehlerwert" SG_ 914 ESP_RTA_VR 255;
BA_ "GenSigSendType" SG_ 914 ESP_Stat_FallBack_eBKV 0;
BA_ "GenSigSwitchedByIgnition" SG_ 914 ESP_Stat_FallBack_eBKV 0;
BA_ "GenSigSendType" SG_ 914 OBD_Fehler_Radsensor_HL 0;
BA_ "GenSigSwitchedByIgnition" SG_ 914 OBD_Fehler_Radsensor_HL 0;
BA_ "GenSigSendType" SG_ 914 OBD_Fehler_Radsensor_HR 0;
BA_ "GenSigSwitchedByIgnition" SG_ 914 OBD_Fehler_Radsensor_HR 0;
BA_ "GenSigSendType" SG_ 914 OBD_Fehler_Radsensor_VL 0;
BA_ "GenSigSwitchedByIgnition" SG_ 914 OBD_Fehler_Radsensor_VL 0;
BA_ "GenSigSendType" SG_ 914 OBD_Fehler_Radsensor_VR 0;
BA_ "GenSigSwitchedByIgnition" SG_ 914 OBD_Fehler_Radsensor_VR 0;
BA_ "GenSigSendType" SG_ 286 ESC_Bremsdruckgradient 0;
BA_ "GenSigStartValue" SG_ 286 ESC_Bremsdruckgradient 254;
BA_ "GenSigSwitchedByIgnition" SG_ 286 ESC_Bremsdruckgradient 0;
BA_ "Fehlerwert" SG_ 286 ESC_Bremsdruckgradient 255;
BA_ "GenSigSendType" SG_ 286 ESP_08_BZ 0;
BA_ "GenSigFuncType" SG_ 286 ESP_08_BZ 1;
BA_ "GenSigSwitchedByIgnition" SG_ 286 ESP_08_BZ 0;
BA_ "GenSigSendType" SG_ 286 ESP_08_CRC 0;
BA_ "GenSigFuncType" SG_ 286 ESP_08_CRC 2;
BA_ "GenSigSwitchedByIgnition" SG_ 286 ESP_08_CRC 0;
BA_ "GenSigSendType" SG_ 286 ESP_Abrutschen_Stillstand 0;
BA_ "GenSigSwitchedByIgnition" SG_ 286 ESP_Abrutschen_Stillstand 0;
BA_ "GenSigSendType" SG_ 286 ESP_ANB_CM_Rueckk_Umsetz 0;
BA_ "GenSigSwitchedByIgnition" SG_ 286 ESP_ANB_CM_Rueckk_Umsetz 0;
BA_ "GenSigSendType" SG_ 286 ESP_Fahrer_tritt_ZBR_Schw 0;
BA_ "GenSigSwitchedByIgnition" SG_ 286 ESP_Fahrer_tritt_ZBR_Schw 0;
BA_ "GenSigSendType" SG_ 286 ESP_Konsistenz_ACC_Botschaft 0;
BA_ "GenSigSwitchedByIgnition" SG_ 286 ESP_Konsistenz_ACC_Botschaft 0;
BA_ "GenSigSendType" SG_ 286 ESP_QBit_v_ref 0;
BA_ "GenSigStartValue" SG_ 286 ESP_QBit_v_ref 1;
BA_ "GenSigSwitchedByIgnition" SG_ 286 ESP_QBit_v_ref 0;
BA_ "GenSigSendType" SG_ 286 ESP_Stillstandsphase_erschoepft 0;
BA_ "GenSigSwitchedByIgnition" SG_ 286 ESP_Stillstandsphase_erschoepft 0;
BA_ "GenSigSendType" SG_ 286 ESP_Tuerkontakt_Fahrertuer 0;
BA_ "GenSigSwitchedByIgnition" SG_ 286 ESP_Tuerkontakt_Fahrertuer 0;
BA_ "GenSigSendType" SG_ 286 ESP_v_ref 0;
BA_ "GenSigStartValue" SG_ 286 ESP_v_ref 4094;
BA_ "GenSigSwitchedByIgnition" SG_ 286 ESP_v_ref 0;
BA_ "Fehlerwert" SG_ 286 ESP_v_ref 4095;
BA_ "GenSigSendType" SG_ 286 ESP_v_ref_Fahrtrichtung 0;
BA_ "GenSigSwitchedByIgnition" SG_ 286 ESP_v_ref_Fahrtrichtung 0;
BA_ "GenSigSendType" SG_ 286 ESP_ZT_Rueckk_Umsetz 0;
BA_ "GenSigSwitchedByIgnition" SG_ 286 ESP_ZT_Rueckk_Umsetz 0;
BA_ "GenSigSendType" SG_ 278 ESP_10_BZ 0;
BA_ "GenSigFuncType" SG_ 278 ESP_10_BZ 1;
BA_ "GenSigSwitchedByIgnition" SG_ 278 ESP_10_BZ 0;
BA_ "GenSigSendType" SG_ 278 ESP_10_CRC 0;
BA_ "GenSigFuncType" SG_ 278 ESP_10_CRC 2;
BA_ "GenSigSwitchedByIgnition" SG_ 278 ESP_10_CRC 0;
BA_ "GenSigSendType" SG_ 278 ESP_HL_Fahrtrichtung 0;
BA_ "GenSigStartValue" SG_ 278 ESP_HL_Fahrtrichtung 2;
BA_ "GenSigSwitchedByIgnition" SG_ 278 ESP_HL_Fahrtrichtung 0;
BA_ "GenSigSendType" SG_ 278 ESP_HR_Fahrtrichtung 0;
BA_ "GenSigStartValue" SG_ 278 ESP_HR_Fahrtrichtung 2;
BA_ "GenSigSwitchedByIgnition" SG_ 278 ESP_HR_Fahrtrichtung 0;
BA_ "GenSigSendType" SG_ 278 ESP_QBit_Wegimpuls_HL 0;
BA_ "GenSigStartValue" SG_ 278 ESP_QBit_Wegimpuls_HL 1;
BA_ "GenSigSwitchedByIgnition" SG_ 278 ESP_QBit_Wegimpuls_HL 0;
BA_ "GenSigSendType" SG_ 278 ESP_QBit_Wegimpuls_HR 0;
BA_ "GenSigStartValue" SG_ 278 ESP_QBit_Wegimpuls_HR 1;
BA_ "GenSigSwitchedByIgnition" SG_ 278 ESP_QBit_Wegimpuls_HR 0;
BA_ "GenSigSendType" SG_ 278 ESP_QBit_Wegimpuls_VL 0;
BA_ "GenSigStartValue" SG_ 278 ESP_QBit_Wegimpuls_VL 1;
BA_ "GenSigSwitchedByIgnition" SG_ 278 ESP_QBit_Wegimpuls_VL 0;
BA_ "GenSigSendType" SG_ 278 ESP_QBit_Wegimpuls_VR 0;
BA_ "GenSigStartValue" SG_ 278 ESP_QBit_Wegimpuls_VR 1;
BA_ "GenSigSwitchedByIgnition" SG_ 278 ESP_QBit_Wegimpuls_VR 0;
BA_ "GenSigSendType" SG_ 278 ESP_VL_Fahrtrichtung 0;
BA_ "GenSigStartValue" SG_ 278 ESP_VL_Fahrtrichtung 2;
BA_ "GenSigSwitchedByIgnition" SG_ 278 ESP_VL_Fahrtrichtung 0;
BA_ "GenSigSendType" SG_ 278 ESP_VR_Fahrtrichtung 0;
BA_ "GenSigStartValue" SG_ 278 ESP_VR_Fahrtrichtung 2;
BA_ "GenSigSwitchedByIgnition" SG_ 278 ESP_VR_Fahrtrichtung 0;
BA_ "GenSigSendType" SG_ 278 ESP_Wegimpuls_HL 0;
BA_ "GenSigStartValue" SG_ 278 ESP_Wegimpuls_HL 1021;
BA_ "GenSigSwitchedByIgnition" SG_ 278 ESP_Wegimpuls_HL 0;
BA_ "Fehlerwert" SG_ 278 ESP_Wegimpuls_HL 1023;
BA_ "GenSigSendType" SG_ 278 ESP_Wegimpuls_HR 0;
BA_ "GenSigStartValue" SG_ 278 ESP_Wegimpuls_HR 1021;
BA_ "GenSigSwitchedByIgnition" SG_ 278 ESP_Wegimpuls_HR 0;
BA_ "Fehlerwert" SG_ 278 ESP_Wegimpuls_HR 1023;
BA_ "GenSigSendType" SG_ 278 ESP_Wegimpuls_VL 0;
BA_ "GenSigStartValue" SG_ 278 ESP_Wegimpuls_VL 1021;
BA_ "GenSigSwitchedByIgnition" SG_ 278 ESP_Wegimpuls_VL 0;
BA_ "Fehlerwert" SG_ 278 ESP_Wegimpuls_VL 1023;
BA_ "GenSigSendType" SG_ 278 ESP_Wegimpuls_VR 0;
BA_ "GenSigStartValue" SG_ 278 ESP_Wegimpuls_VR 1021;
BA_ "GenSigSwitchedByIgnition" SG_ 278 ESP_Wegimpuls_VR 0;
BA_ "Fehlerwert" SG_ 278 ESP_Wegimpuls_VR 1023;
BA_ "GenSigSendType" SG_ 138 BR_Status_Quer_ESP 0;
BA_ "GenSigStartValue" SG_ 138 BR_Status_Quer_ESP 1;
BA_ "GenSigSwitchedByIgnition" SG_ 138 BR_Status_Quer_ESP 0;
BA_ "GenSigSendType" SG_ 138 BR_Vorg_Allrad_Max 0;
BA_ "GenSigStartValue" SG_ 138 BR_Vorg_Allrad_Max 254;
BA_ "GenSigSwitchedByIgnition" SG_ 138 BR_Vorg_Allrad_Max 0;
BA_ "Fehlerwert" SG_ 138 BR_Vorg_Allrad_Max 255;
BA_ "GenSigSendType" SG_ 138 BR_Vorg_Allrad_Min 0;
BA_ "GenSigStartValue" SG_ 138 BR_Vorg_Allrad_Min 254;
BA_ "GenSigSwitchedByIgnition" SG_ 138 BR_Vorg_Allrad_Min 0;
BA_ "Fehlerwert" SG_ 138 BR_Vorg_Allrad_Min 255;
BA_ "GenSigSendType" SG_ 138 BR_Vorg_Quer_Max 0;
BA_ "GenSigStartValue" SG_ 138 BR_Vorg_Quer_Max 254;
BA_ "GenSigSwitchedByIgnition" SG_ 138 BR_Vorg_Quer_Max 0;
BA_ "Fehlerwert" SG_ 138 BR_Vorg_Quer_Max 255;
BA_ "GenSigSendType" SG_ 138 BR_Vorg_Quer_Min 0;
BA_ "GenSigStartValue" SG_ 138 BR_Vorg_Quer_Min 254;
BA_ "GenSigSwitchedByIgnition" SG_ 138 BR_Vorg_Quer_Min 0;
BA_ "Fehlerwert" SG_ 138 BR_Vorg_Quer_Min 255;
BA_ "GenSigSendType" SG_ 138 ESP_14_Anf_Lenkmomoffset_DSR 0;
BA_ "GenSigSwitchedByIgnition" SG_ 138 ESP_14_Anf_Lenkmomoffset_DSR 0;
BA_ "GenSigSendType" SG_ 138 ESP_14_BZ 0;
BA_ "GenSigFuncType" SG_ 138 ESP_14_BZ 1;
BA_ "GenSigSwitchedByIgnition" SG_ 138 ESP_14_BZ 0;
BA_ "GenSigSendType" SG_ 138 ESP_14_CRC 0;
BA_ "GenSigFuncType" SG_ 138 ESP_14_CRC 2;
BA_ "GenSigSwitchedByIgnition" SG_ 138 ESP_14_CRC 0;
BA_ "GenSigSendType" SG_ 138 ESP_14_Sendestatus 5;
BA_ "GenSigSwitchedByIgnition" SG_ 138 ESP_14_Sendestatus 0;
BA_ "GenSigSendType" SG_ 138 ESP_14_Status_DSR 0;
BA_ "GenSigSwitchedByIgnition" SG_ 138 ESP_14_Status_DSR 0;
BA_ "GenSigSendType" SG_ 138 ESP_14_VZ_Anf_Lenkmomoffset_DSR 0;
BA_ "GenSigSwitchedByIgnition" SG_ 138 ESP_14_VZ_Anf_Lenkmomoffset_DSR 0;
BA_ "GenSigSendType" SG_ 418 ESP_15_BZ 0;
BA_ "GenSigFuncType" SG_ 418 ESP_15_BZ 1;
BA_ "GenSigSwitchedByIgnition" SG_ 418 ESP_15_BZ 0;
BA_ "GenSigSendType" SG_ 418 ESP_15_CRC 0;
BA_ "GenSigFuncType" SG_ 418 ESP_15_CRC 2;
BA_ "GenSigSwitchedByIgnition" SG_ 418 ESP_15_CRC 0;
BA_ "GenSigSendType" SG_ 418 ESP_Haltemoment 0;
BA_ "GenSigStartValue" SG_ 418 ESP_Haltemoment 1022;
BA_ "GenSigSwitchedByIgnition" SG_ 418 ESP_Haltemoment 0;
BA_ "Fehlerwert" SG_ 418 ESP_Haltemoment 1023;
BA_ "GenSigSendType" SG_ 418 ESP_Index_Haltemoment 0;
BA_ "GenSigSwitchedByIgnition" SG_ 418 ESP_Index_Haltemoment 0;
BA_ "GenSigSendType" SG_ 418 HMS_aktives_System 3;
BA_ "GenSigSwitchedByIgnition" SG_ 418 HMS_aktives_System 0;
BA_ "GenSigSendType" SG_ 418 HMS_Anforderung_GE 3;
BA_ "GenSigSwitchedByIgnition" SG_ 418 HMS_Anforderung_GE 0;
BA_ "GenSigSendType" SG_ 418 HMS_Fehlerstatus 3;
BA_ "GenSigSwitchedByIgnition" SG_ 418 HMS_Fehlerstatus 0;
BA_ "GenSigSendType" SG_ 418 HMS_halten_nicht_verfuegbar 3;
BA_ "GenSigSwitchedByIgnition" SG_ 418 HMS_halten_nicht_verfuegbar 0;
BA_ "GenSigSendType" SG_ 418 HMS_Konsistenz_ACC 3;
BA_ "GenSigSwitchedByIgnition" SG_ 418 HMS_Konsistenz_ACC 0;
BA_ "GenSigSendType" SG_ 418 HMS_Konsistenz_EBKV 3;
BA_ "GenSigSwitchedByIgnition" SG_ 418 HMS_Konsistenz_EBKV 0;
BA_ "GenSigSendType" SG_ 418 HMS_Konsistenz_GE 3;
BA_ "GenSigSwitchedByIgnition" SG_ 418 HMS_Konsistenz_GE 0;
BA_ "GenSigSendType" SG_ 418 HMS_Konsistenz_HVLM 3;
BA_ "GenSigSwitchedByIgnition" SG_ 418 HMS_Konsistenz_HVLM 0;
BA_ "GenSigSendType" SG_ 418 HMS_Konsistenz_IPA 3;
BA_ "GenSigSwitchedByIgnition" SG_ 418 HMS_Konsistenz_IPA 0;
BA_ "GenSigSendType" SG_ 418 HMS_Konsistenz_MO 3;
BA_ "GenSigSwitchedByIgnition" SG_ 418 HMS_Konsistenz_MO 0;
BA_ "GenSigSendType" SG_ 418 HMS_Konsistenz_RCTA 3;
BA_ "GenSigSwitchedByIgnition" SG_ 418 HMS_Konsistenz_RCTA 0;
BA_ "GenSigSendType" SG_ 418 HMS_Konsistenz_STA 3;
BA_ "GenSigSwitchedByIgnition" SG_ 418 HMS_Konsistenz_STA 0;
BA_ "GenSigSendType" SG_ 418 HMS_Notstopp_Status 3;
BA_ "GenSigSwitchedByIgnition" SG_ 418 HMS_Notstopp_Status 0;
BA_ "GenSigSendType" SG_ 418 HMS_P_beibehalten_GE 0;
BA_ "GenSigStartValue" SG_ 418 HMS_P_beibehalten_GE 2;
BA_ "GenSigSwitchedByIgnition" SG_ 418 HMS_P_beibehalten_GE 0;
BA_ "Fehlerwert" SG_ 418 HMS_P_beibehalten_GE 3;
BA_ "GenSigSendType" SG_ 418 HMS_parken_nicht_verfuegbar 3;
BA_ "GenSigSwitchedByIgnition" SG_ 418 HMS_parken_nicht_verfuegbar 0;
BA_ "GenSigSendType" SG_ 418 HMS_Stillstand 3;
BA_ "GenSigStartValue" SG_ 418 HMS_Stillstand 6;
BA_ "GenSigSwitchedByIgnition" SG_ 418 HMS_Stillstand 0;
BA_ "Fehlerwert" SG_ 418 HMS_Stillstand 7;
BA_ "GenSigSendType" SG_ 418 HMS_Systemstatus 3;
BA_ "GenSigStartValue" SG_ 418 HMS_Systemstatus 14;
BA_ "GenSigSwitchedByIgnition" SG_ 418 HMS_Systemstatus 0;
BA_ "Fehlerwert" SG_ 418 HMS_Systemstatus 15;
BA_ "GenSigSendType" SG_ 418 NL_PRIM_STP_01_Status 3;
BA_ "GenSigSwitchedByIgnition" SG_ 418 NL_PRIM_STP_01_Status 0;
BA_ "GenSigSendType" SG_ 178 ESP_HL_Radgeschw_02 0;
BA_ "GenSigStartValue" SG_ 178 ESP_HL_Radgeschw_02 65534;
BA_ "GenSigSwitchedByIgnition" SG_ 178 ESP_HL_Radgeschw_02 0;
BA_ "Fehlerwert" SG_ 178 ESP_HL_Radgeschw_02 65535;
BA_ "GenSigSendType" SG_ 178 ESP_HR_Radgeschw_02 0;
BA_ "GenSigStartValue" SG_ 178 ESP_HR_Radgeschw_02 65534;
BA_ "GenSigSwitchedByIgnition" SG_ 178 ESP_HR_Radgeschw_02 0;
BA_ "Fehlerwert" SG_ 178 ESP_HR_Radgeschw_02 65535;
BA_ "GenSigSendType" SG_ 178 ESP_VL_Radgeschw_02 0;
BA_ "GenSigStartValue" SG_ 178 ESP_VL_Radgeschw_02 65534;
BA_ "GenSigSwitchedByIgnition" SG_ 178 ESP_VL_Radgeschw_02 0;
BA_ "Fehlerwert" SG_ 178 ESP_VL_Radgeschw_02 65535;
BA_ "GenSigSendType" SG_ 178 ESP_VR_Radgeschw_02 0;
BA_ "GenSigStartValue" SG_ 178 ESP_VR_Radgeschw_02 65534;
BA_ "GenSigSwitchedByIgnition" SG_ 178 ESP_VR_Radgeschw_02 0;
BA_ "Fehlerwert" SG_ 178 ESP_VR_Radgeschw_02 65535;
BA_ "GenSigSendType" SG_ 1629 BR_QBit_Reifenumfang 0;
BA_ "GenSigStartValue" SG_ 1629 BR_QBit_Reifenumfang 1;
BA_ "GenSigSwitchedByIgnition" SG_ 1629 BR_QBit_Reifenumfang 0;
BA_ "GenSigSendType" SG_ 1629 BR_Reifenumfang 0;
BA_ "GenSigSwitchedByIgnition" SG_ 1629 BR_Reifenumfang 0;
BA_ "GenSigSendType" SG_ 1629 BR_Systemart 0;
BA_ "GenSigFuncType" SG_ 1629 BR_Systemart 8;
BA_ "GenSigSwitchedByIgnition" SG_ 1629 BR_Systemart 0;
BA_ "GenSigSendType" SG_ 1629 ESP_20_BZ 0;
BA_ "GenSigFuncType" SG_ 1629 ESP_20_BZ 1;
BA_ "GenSigSwitchedByIgnition" SG_ 1629 ESP_20_BZ 0;
BA_ "GenSigSendType" SG_ 1629 ESP_20_CRC 0;
BA_ "GenSigFuncType" SG_ 1629 ESP_20_CRC 2;
BA_ "GenSigSwitchedByIgnition" SG_ 1629 ESP_20_CRC 0;
BA_ "GenSigSendType" SG_ 1629 ESP_Charisma_FahrPr 3;
BA_ "GenSigSwitchedByIgnition" SG_ 1629 ESP_Charisma_FahrPr 0;
BA_ "GenSigSendType" SG_ 1629 ESP_Charisma_Status 3;
BA_ "GenSigSwitchedByIgnition" SG_ 1629 ESP_Charisma_Status 0;
BA_ "GenSigSendType" SG_ 1629 ESP_Dachrelingsensor 0;
BA_ "GenSigSwitchedByIgnition" SG_ 1629 ESP_Dachrelingsensor 0;
BA_ "Fehlerwert" SG_ 1629 ESP_Dachrelingsensor 3;
BA_ "GenSigSendType" SG_ 1629 ESP_SpannungsAnf_02 3;
BA_ "GenSigSwitchedByIgnition" SG_ 1629 ESP_SpannungsAnf_02 0;
BA_ "GenSigSendType" SG_ 1629 ESP_Stoppverbot_Anz_01 3;
BA_ "GenSigSwitchedByIgnition" SG_ 1629 ESP_Stoppverbot_Anz_01 0;
BA_ "GenSigSendType" SG_ 1629 ESP_Stoppverbot_Anz_02 3;
BA_ "GenSigSwitchedByIgnition" SG_ 1629 ESP_Stoppverbot_Anz_02 0;
BA_ "GenSigSendType" SG_ 1629 ESP_Stoppverbot_Anz_03 3;
BA_ "GenSigSwitchedByIgnition" SG_ 1629 ESP_Stoppverbot_Anz_03 0;
BA_ "GenSigSendType" SG_ 1629 ESP_Stoppverbot_Anz_04 3;
BA_ "GenSigSwitchedByIgnition" SG_ 1629 ESP_Stoppverbot_Anz_04 0;
BA_ "GenSigSendType" SG_ 1629 ESP_Stoppverbot_Anz_05 3;
BA_ "GenSigSwitchedByIgnition" SG_ 1629 ESP_Stoppverbot_Anz_05 0;
BA_ "GenSigSendType" SG_ 1629 ESP_Stoppverbot_Anz_06 3;
BA_ "GenSigSwitchedByIgnition" SG_ 1629 ESP_Stoppverbot_Anz_06 0;
BA_ "GenSigSendType" SG_ 1629 ESP_Stoppverbot_Anz_07 3;
BA_ "GenSigSwitchedByIgnition" SG_ 1629 ESP_Stoppverbot_Anz_07 0;
BA_ "GenSigSendType" SG_ 1629 ESP_Stoppverbot_Anz_08 3;
BA_ "GenSigSwitchedByIgnition" SG_ 1629 ESP_Stoppverbot_Anz_08 0;
BA_ "GenSigSendType" SG_ 1629 ESP_Stoppverbot_Anz_Std 3;
BA_ "GenSigSwitchedByIgnition" SG_ 1629 ESP_Stoppverbot_Anz_Std 0;
BA_ "GenSigSendType" SG_ 1629 ESP_Wiederstart_Anz_01 3;
BA_ "GenSigSwitchedByIgnition" SG_ 1629 ESP_Wiederstart_Anz_01 0;
BA_ "GenSigSendType" SG_ 1629 ESP_Wiederstart_Anz_02 3;
BA_ "GenSigSwitchedByIgnition" SG_ 1629 ESP_Wiederstart_Anz_02 0;
BA_ "GenSigSendType" SG_ 1629 ESP_Wiederstart_Anz_03 3;
BA_ "GenSigSwitchedByIgnition" SG_ 1629 ESP_Wiederstart_Anz_03 0;
BA_ "GenSigSendType" SG_ 1629 ESP_Wiederstart_Anz_04 3;
BA_ "GenSigSwitchedByIgnition" SG_ 1629 ESP_Wiederstart_Anz_04 0;
BA_ "GenSigSendType" SG_ 1629 ESP_Zaehnezahl 0;
BA_ "GenSigFuncType" SG_ 1629 ESP_Zaehnezahl 8;
BA_ "GenSigSwitchedByIgnition" SG_ 1629 ESP_Zaehnezahl 0;
BA_ "GenSigSendType" SG_ 1629 HDC_Charisma_FahrPr 3;
BA_ "GenSigSwitchedByIgnition" SG_ 1629 HDC_Charisma_FahrPr 0;
BA_ "GenSigSendType" SG_ 1629 HDC_Charisma_Status 3;
BA_ "GenSigSwitchedByIgnition" SG_ 1629 HDC_Charisma_Status 0;
BA_ "GenSigSendType" SG_ 253 ABS_Bremsung 0;
BA_ "GenSigSwitchedByIgnition" SG_ 253 ABS_Bremsung 0;
BA_ "GenSigSendType" SG_ 253 ASR_Anf 0;
BA_ "GenSigSwitchedByIgnition" SG_ 253 ASR_Anf 0;
BA_ "GenSigSendType" SG_ 253 ASR_Schalteingriff 0;
BA_ "GenSigSwitchedByIgnition" SG_ 253 ASR_Schalteingriff 0;
BA_ "GenSigSendType" SG_ 253 ASR_Tastung_passiv 0;
BA_ "GenSigSwitchedByIgnition" SG_ 253 ASR_Tastung_passiv 0;
BA_ "GenSigSendType" SG_ 253 BR_Eingriffsmoment 0;
BA_ "GenSigStartValue" SG_ 253 BR_Eingriffsmoment 1022;
BA_ "GenSigSwitchedByIgnition" SG_ 253 BR_Eingriffsmoment 0;
BA_ "Fehlerwert" SG_ 253 BR_Eingriffsmoment 1023;
BA_ "GenSigSendType" SG_ 253 EBV_Eingriff 0;
BA_ "GenSigSwitchedByIgnition" SG_ 253 EBV_Eingriff 0;
BA_ "GenSigSendType" SG_ 253 EDS_Eingriff 0;
BA_ "GenSigSwitchedByIgnition" SG_ 253 EDS_Eingriff 0;
BA_ "GenSigSendType" SG_ 253 ESC_Reku_Freigabe 0;
BA_ "GenSigSwitchedByIgnition" SG_ 253 ESC_Reku_Freigabe 0;
BA_ "GenSigSendType" SG_ 253 ESC_v_Signal_Qualifier_High_Low 0;
BA_ "GenSigStartValue" SG_ 253 ESC_v_Signal_Qualifier_High_Low 6;
BA_ "GenSigSwitchedByIgnition" SG_ 253 ESC_v_Signal_Qualifier_High_Low 0;
BA_ "Fehlerwert" SG_ 253 ESC_v_Signal_Qualifier_High_Low 7;
BA_ "GenSigSendType" SG_ 253 ESP_21_BZ 0;
BA_ "GenSigFuncType" SG_ 253 ESP_21_BZ 1;
BA_ "GenSigSwitchedByIgnition" SG_ 253 ESP_21_BZ 0;
BA_ "GenSigSendType" SG_ 253 ESP_21_CRC 0;
BA_ "GenSigFuncType" SG_ 253 ESP_21_CRC 2;
BA_ "GenSigSwitchedByIgnition" SG_ 253 ESP_21_CRC 0;
BA_ "GenSigSendType" SG_ 253 ESP_Anhaltevorgang_ACC_aktiv 0;
BA_ "GenSigSwitchedByIgnition" SG_ 253 ESP_Anhaltevorgang_ACC_aktiv 0;
BA_ "GenSigSendType" SG_ 253 ESP_ASP 0;
BA_ "GenSigSwitchedByIgnition" SG_ 253 ESP_ASP 0;
BA_ "GenSigSendType" SG_ 253 ESP_AWV3_Brems_aktiv 0;
BA_ "GenSigSwitchedByIgnition" SG_ 253 ESP_AWV3_Brems_aktiv 0;
BA_ "GenSigSendType" SG_ 253 ESP_Diagnose 0;
BA_ "GenSigSwitchedByIgnition" SG_ 253 ESP_Diagnose 0;
BA_ "GenSigSendType" SG_ 253 ESP_Eingriff 0;
BA_ "GenSigSwitchedByIgnition" SG_ 253 ESP_Eingriff 0;
BA_ "GenSigSendType" SG_ 253 ESP_Haltebestaetigung 0;
BA_ "GenSigSwitchedByIgnition" SG_ 253 ESP_Haltebestaetigung 0;
BA_ "GenSigSendType" SG_ 253 ESP_MKB_Abbruch_Geschw 0;
BA_ "GenSigSwitchedByIgnition" SG_ 253 ESP_MKB_Abbruch_Geschw 0;
BA_ "GenSigSendType" SG_ 253 ESP_PLA_Bremseingriff 0;
BA_ "GenSigSwitchedByIgnition" SG_ 253 ESP_PLA_Bremseingriff 0;
BA_ "GenSigSendType" SG_ 253 ESP_QBit_v_Signal 0;
BA_ "GenSigStartValue" SG_ 253 ESP_QBit_v_Signal 1;
BA_ "GenSigSwitchedByIgnition" SG_ 253 ESP_QBit_v_Signal 0;
BA_ "GenSigSendType" SG_ 253 ESP_Systemstatus 0;
BA_ "GenSigSwitchedByIgnition" SG_ 253 ESP_Systemstatus 0;
BA_ "GenSigSendType" SG_ 253 ESP_Tastung_passiv 0;
BA_ "GenSigSwitchedByIgnition" SG_ 253 ESP_Tastung_passiv 0;
BA_ "GenSigSendType" SG_ 253 ESP_v_Signal 0;
BA_ "GenSigStartValue" SG_ 253 ESP_v_Signal 65534;
BA_ "GenSigSwitchedByIgnition" SG_ 253 ESP_v_Signal 0;
BA_ "Fehlerwert" SG_ 253 ESP_v_Signal 65535;
BA_ "GenSigMissingSourceValue" SG_ 253 ESP_v_Signal 65534;
BA_ "GenSigSendType" SG_ 253 ESP_Vorsteuerung 0;
BA_ "GenSigSwitchedByIgnition" SG_ 253 ESP_Vorsteuerung 0;
BA_ "GenSigSendType" SG_ 253 MSR_Anf 0;
BA_ "GenSigSwitchedByIgnition" SG_ 253 MSR_Anf 0;
BA_ "GenSigSendType" SG_ 253 OBD_QBit_Schlechtweg 0;
BA_ "GenSigStartValue" SG_ 253 OBD_QBit_Schlechtweg 1;
BA_ "GenSigSwitchedByIgnition" SG_ 253 OBD_QBit_Schlechtweg 0;
BA_ "GenSigSendType" SG_ 253 OBD_Schlechtweg 0;
BA_ "GenSigSwitchedByIgnition" SG_ 253 OBD_Schlechtweg 0;
BA_REL_ "GenSigTimeoutTime" BU_SG_REL_ Allrad_Haldex SG_ 1714 DGN_Verlernzaehler 5000;
BA_REL_ "GenSigTimeoutTime" BU_SG_REL_ Allrad_Haldex SG_ 1714 KBI_Kilometerstand 5000;
BA_REL_ "GenSigTimeoutTime" BU_SG_REL_ Allrad_Haldex SG_ 1714 UH_Jahr 5000;
BA_REL_ "GenSigTimeoutTime" BU_SG_REL_ Allrad_Haldex SG_ 1714 UH_Monat 5000;
BA_REL_ "GenSigTimeoutTime" BU_SG_REL_ Allrad_Haldex SG_ 1714 UH_Tag 5000;
BA_REL_ "GenSigTimeoutTime" BU_SG_REL_ Allrad_Haldex SG_ 1714 UH_Stunde 5000;
BA_REL_ "GenSigTimeoutTime" BU_SG_REL_ Allrad_Haldex SG_ 1714 UH_Minute 5000;
BA_REL_ "GenSigTimeoutTime" BU_SG_REL_ Allrad_Haldex SG_ 1714 UH_Sekunde 5000;
BA_REL_ "GenSigTimeoutTime" BU_SG_REL_ Allrad_Haldex SG_ 257 ESP_02_BZ 500;
BA_REL_ "GenSigTimeoutTime" BU_SG_REL_ Allrad_Haldex SG_ 257 ESP_QBit_Gierrate 500;
BA_REL_ "GenSigTimeoutTime" BU_SG_REL_ Allrad_Haldex SG_ 257 ESP_QBit_Laengsbeschl 500;
BA_REL_ "GenSigTimeoutTime" BU_SG_REL_ Allrad_Haldex SG_ 257 ESP_QBit_Querb 500;
BA_REL_ "GenSigTimeoutTime" BU_SG_REL_ Allrad_Haldex SG_ 257 ESP_Querbeschleunigung 500;
BA_REL_ "GenSigTimeoutTime" BU_SG_REL_ Allrad_Haldex SG_ 257 ESP_Laengsbeschl 500;
BA_REL_ "GenSigTimeoutTime" BU_SG_REL_ Allrad_Haldex SG_ 257 ESP_Gierrate 500;
BA_REL_ "GenSigTimeoutTime" BU_SG_REL_ Allrad_Haldex SG_ 257 ESP_VZ_Gierrate 500;
BA_REL_ "GenSigTimeoutTime" BU_SG_REL_ Allrad_Haldex SG_ 262 ESP_05_BZ 500;
BA_REL_ "GenSigTimeoutTime" BU_SG_REL_ Allrad_Haldex SG_ 262 ESP_QBit_Fahrer_bremst 500;
BA_REL_ "GenSigTimeoutTime" BU_SG_REL_ Allrad_Haldex SG_ 262 ESP_Bremsdruck 500;
BA_REL_ "GenSigTimeoutTime" BU_SG_REL_ Allrad_Haldex SG_ 262 ESP_Fahrer_bremst 500;
BA_REL_ "GenSigTimeoutTime" BU_SG_REL_ Allrad_Haldex SG_ 262 ESP_Verz_TSK_aktiv 500;
BA_REL_ "GenSigTimeoutTime" BU_SG_REL_ Allrad_Haldex SG_ 262 ESP_Verz_EPB_aktiv 500;
BA_REL_ "GenSigTimeoutTime" BU_SG_REL_ Allrad_Haldex SG_ 914 ESP_Rollenmodus_Deaktivieren 1000;
BA_REL_ "GenSigTimeoutTime" BU_SG_REL_ Allrad_Haldex SG_ 138 BR_Vorg_Allrad_Min 5000;
BA_REL_ "GenSigTimeoutTime" BU_SG_REL_ Allrad_Haldex SG_ 138 BR_Vorg_Allrad_Max 5000;
BA_REL_ "GenSigTimeoutTime" BU_SG_REL_ Allrad_Haldex SG_ 178 ESP_HL_Radgeschw_02 500;
BA_REL_ "GenSigTimeoutTime" BU_SG_REL_ Allrad_Haldex SG_ 178 ESP_HR_Radgeschw_02 500;
BA_REL_ "GenSigTimeoutTime" BU_SG_REL_ Allrad_Haldex SG_ 178 ESP_VL_Radgeschw_02 500;
BA_REL_ "GenSigTimeoutTime" BU_SG_REL_ Allrad_Haldex SG_ 178 ESP_VR_Radgeschw_02 500;
BA_REL_ "GenSigTimeoutTime" BU_SG_REL_ Allrad_Haldex SG_ 1629 BR_Systemart 5000;
BA_REL_ "GenSigTimeoutTime" BU_SG_REL_ Allrad_Haldex SG_ 1629 BR_QBit_Reifenumfang 5000;
BA_REL_ "GenSigTimeoutTime" BU_SG_REL_ Allrad_Haldex SG_ 1629 BR_Reifenumfang 5000;
BA_REL_ "GenSigTimeoutTime" BU_SG_REL_ Allrad_Haldex SG_ 253 ESP_21_BZ 500;
BA_REL_ "GenSigTimeoutTime" BU_SG_REL_ Allrad_Haldex SG_ 253 ABS_Bremsung 500;
BA_REL_ "GenSigTimeoutTime" BU_SG_REL_ Allrad_Haldex SG_ 253 ASR_Anf 500;
BA_REL_ "GenSigTimeoutTime" BU_SG_REL_ Allrad_Haldex SG_ 253 EDS_Eingriff 500;
BA_REL_ "GenSigTimeoutTime" BU_SG_REL_ Allrad_Haldex SG_ 253 ESP_Eingriff 500;
BA_REL_ "GenSigTimeoutTime" BU_SG_REL_ AreaView_MQB SG_ 1714 DGN_Verlernzaehler 5000;
BA_REL_ "GenSigTimeoutTime" BU_SG_REL_ AreaView_MQB SG_ 1714 KBI_Kilometerstand 5000;
BA_REL_ "GenSigTimeoutTime" BU_SG_REL_ AreaView_MQB SG_ 1714 UH_Jahr 5000;
BA_REL_ "GenSigTimeoutTime" BU_SG_REL_ AreaView_MQB SG_ 1714 UH_Monat 5000;
BA_REL_ "GenSigTimeoutTime" BU_SG_REL_ AreaView_MQB SG_ 1714 UH_Tag 5000;
BA_REL_ "GenSigTimeoutTime" BU_SG_REL_ AreaView_MQB SG_ 1714 UH_Stunde 5000;
BA_REL_ "GenSigTimeoutTime" BU_SG_REL_ AreaView_MQB SG_ 1714 UH_Minute 5000;
BA_REL_ "GenSigTimeoutTime" BU_SG_REL_ AreaView_MQB SG_ 1714 UH_Sekunde 5000;
BA_REL_ "GenSigTimeoutTime" BU_SG_REL_ AreaView_MQB SG_ 1714 Kombi_02_alt 5000;
BA_REL_ "GenSigTimeoutTime" BU_SG_REL_ AreaView_MQB SG_ 1714 Uhrzeit_01_alt 5000;
BA_REL_ "GenSigTimeoutTime" BU_SG_REL_ AreaView_MQB SG_ 1520 DI_KL_58xd 2000;
BA_REL_ "GenSigTimeoutTime" BU_SG_REL_ AreaView_MQB SG_ 260 EPB_Status 500;
BA_REL_ "GenSigTimeoutTime" BU_SG_REL_ AreaView_MQB SG_ 257 ESP_QBit_Gierrate 500;
BA_REL_ "GenSigTimeoutTime" BU_SG_REL_ AreaView_MQB SG_ 257 ESP_QBit_Laengsbeschl 500;
BA_REL_ "GenSigTimeoutTime" BU_SG_REL_ AreaView_MQB SG_ 257 ESP_QBit_Querb 500;
BA_REL_ "GenSigTimeoutTime" BU_SG_REL_ AreaView_MQB SG_ 257 ESP_Querbeschleunigung 500;
BA_REL_ "GenSigTimeoutTime" BU_SG_REL_ AreaView_MQB SG_ 257 ESP_Laengsbeschl 500;
BA_REL_ "GenSigTimeoutTime" BU_SG_REL_ AreaView_MQB SG_ 257 ESP_Gierrate 500;
BA_REL_ "GenSigTimeoutTime" BU_SG_REL_ AreaView_MQB SG_ 257 ESP_VZ_Gierrate 500;
BA_REL_ "GenSigTimeoutTime" BU_SG_REL_ AreaView_MQB SG_ 278 ESP_QBit_Wegimpuls_VL 500;
BA_REL_ "GenSigTimeoutTime" BU_SG_REL_ AreaView_MQB SG_ 278 ESP_QBit_Wegimpuls_VR 500;
BA_REL_ "GenSigTimeoutTime" BU_SG_REL_ AreaView_MQB SG_ 278 ESP_QBit_Wegimpuls_HL 500;
BA_REL_ "GenSigTimeoutTime" BU_SG_REL_ AreaView_MQB SG_ 278 ESP_QBit_Wegimpuls_HR 500;
BA_REL_ "GenSigTimeoutTime" BU_SG_REL_ AreaView_MQB SG_ 278 ESP_Wegimpuls_VL 500;
BA_REL_ "GenSigTimeoutTime" BU_SG_REL_ AreaView_MQB SG_ 278 ESP_Wegimpuls_VR 500;
BA_REL_ "GenSigTimeoutTime" BU_SG_REL_ AreaView_MQB SG_ 278 ESP_Wegimpuls_HL 500;
BA_REL_ "GenSigTimeoutTime" BU_SG_REL_ AreaView_MQB SG_ 278 ESP_Wegimpuls_HR 500;
BA_REL_ "GenSigTimeoutTime" BU_SG_REL_ AreaView_MQB SG_ 278 ESP_VL_Fahrtrichtung 500;
BA_REL_ "GenSigTimeoutTime" BU_SG_REL_ AreaView_MQB SG_ 278 ESP_VR_Fahrtrichtung 500;
BA_REL_ "GenSigTimeoutTime" BU_SG_REL_ AreaView_MQB SG_ 278 ESP_HL_Fahrtrichtung 500;
BA_REL_ "GenSigTimeoutTime" BU_SG_REL_ AreaView_MQB SG_ 278 ESP_HR_Fahrtrichtung 500;
BA_REL_ "GenSigTimeoutTime" BU_SG_REL_ AreaView_MQB SG_ 178 ESP_HL_Radgeschw_02 500;
BA_REL_ "GenSigTimeoutTime" BU_SG_REL_ AreaView_MQB SG_ 178 ESP_HR_Radgeschw_02 500;
BA_REL_ "GenSigTimeoutTime" BU_SG_REL_ AreaView_MQB SG_ 178 ESP_VL_Radgeschw_02 500;
BA_REL_ "GenSigTimeoutTime" BU_SG_REL_ AreaView_MQB SG_ 178 ESP_VR_Radgeschw_02 500;
BA_REL_ "GenSigTimeoutTime" BU_SG_REL_ AreaView_MQB SG_ 1629 ESP_Zaehnezahl 5000;
BA_REL_ "GenSigTimeoutTime" BU_SG_REL_ AreaView_MQB SG_ 1629 BR_QBit_Reifenumfang 5000;
BA_REL_ "GenSigTimeoutTime" BU_SG_REL_ AreaView_MQB SG_ 1629 BR_Reifenumfang 5000;
BA_REL_ "GenSigTimeoutTime" BU_SG_REL_ AreaView_MQB SG_ 253 ESP_v_Signal 500;
BA_REL_ "GenSigTimeoutTime" BU_SG_REL_ AreaView_MQB SG_ 253 ASR_Tastung_passiv 500;
BA_REL_ "GenSigTimeoutTime" BU_SG_REL_ AreaView_MQB SG_ 253 ESP_Tastung_passiv 500;
BA_REL_ "GenSigTimeoutTime" BU_SG_REL_ AreaView_MQB SG_ 253 ESP_Systemstatus 500;
BA_REL_ "GenSigTimeoutTime" BU_SG_REL_ AreaView_MQB SG_ 253 ESP_QBit_v_Signal 500;
BA_REL_ "GenSigTimeoutTime" BU_SG_REL_ AreaView_MQB SG_ 253 ABS_Bremsung 500;
BA_REL_ "GenSigTimeoutTime" BU_SG_REL_ AreaView_MQB SG_ 253 ASR_Anf 500;
BA_REL_ "GenSigTimeoutTime" BU_SG_REL_ AreaView_MQB SG_ 253 MSR_Anf 500;
BA_REL_ "GenSigTimeoutTime" BU_SG_REL_ AreaView_MQB SG_ 253 EBV_Eingriff 500;
BA_REL_ "GenSigTimeoutTime" BU_SG_REL_ AreaView_MQB SG_ 253 EDS_Eingriff 500;
BA_REL_ "GenSigTimeoutTime" BU_SG_REL_ AreaView_MQB SG_ 253 ESP_Eingriff 500;
BA_REL_ "GenSigTimeoutTime" BU_SG_REL_ Bremse_ABS_MK100 SG_ 1714 DGN_Verlernzaehler 5000;
BA_REL_ "GenSigTimeoutTime" BU_SG_REL_ Bremse_ABS_MK100 SG_ 1714 KBI_Kilometerstand 5000;
BA_REL_ "GenSigTimeoutTime" BU_SG_REL_ Bremse_ABS_MK100 SG_ 1714 UH_Jahr 5000;
BA_REL_ "GenSigTimeoutTime" BU_SG_REL_ Bremse_ABS_MK100 SG_ 1714 UH_Monat 5000;
BA_REL_ "GenSigTimeoutTime" BU_SG_REL_ Bremse_ABS_MK100 SG_ 1714 UH_Tag 5000;
BA_REL_ "GenSigTimeoutTime" BU_SG_REL_ Bremse_ABS_MK100 SG_ 1714 UH_Stunde 5000;
BA_REL_ "GenSigTimeoutTime" BU_SG_REL_ Bremse_ABS_MK100 SG_ 1714 UH_Minute 5000;
BA_REL_ "GenSigTimeoutTime" BU_SG_REL_ Bremse_ABS_MK100 SG_ 1714 UH_Sekunde 5000;
BA_REL_ "GenSigTimeoutTime" BU_SG_REL_ Bremse_ABS_MK100 SG_ 1714 Kombi_02_alt 5000;
BA_REL_ "GenSigTimeoutTime" BU_SG_REL_ Bremse_ABS_MK100 SG_ 1714 Uhrzeit_01_alt 5000;
BA_REL_ "GenSigTimeoutTime" BU_SG_REL_ Bremse_ESP_EPB_EBC460Vi SG_ 1714 DGN_Verlernzaehler 5000;
BA_REL_ "GenSigTimeoutTime" BU_SG_REL_ Bremse_ESP_EPB_EBC460Vi SG_ 1714 KBI_Kilometerstand 5000;
BA_REL_ "GenSigTimeoutTime" BU_SG_REL_ Bremse_ESP_EPB_EBC460Vi SG_ 1714 UH_Jahr 5000;
BA_REL_ "GenSigTimeoutTime" BU_SG_REL_ Bremse_ESP_EPB_EBC460Vi SG_ 1714 UH_Monat 5000;
BA_REL_ "GenSigTimeoutTime" BU_SG_REL_ Bremse_ESP_EPB_EBC460Vi SG_ 1714 UH_Tag 5000;
BA_REL_ "GenSigTimeoutTime" BU_SG_REL_ Bremse_ESP_EPB_EBC460Vi SG_ 1714 UH_Stunde 5000;
BA_REL_ "GenSigTimeoutTime" BU_SG_REL_ Bremse_ESP_EPB_EBC460Vi SG_ 1714 UH_Minute 5000;
BA_REL_ "GenSigTimeoutTime" BU_SG_REL_ Bremse_ESP_EPB_EBC460Vi SG_ 1714 UH_Sekunde 5000;
BA_REL_ "GenSigTimeoutTime" BU_SG_REL_ Bremse_ESP_EPB_EBC460Vi SG_ 1714 Kombi_02_alt 5000;
BA_REL_ "GenSigTimeoutTime" BU_SG_REL_ Bremse_ESP_EPB_EBC460Vi SG_ 1714 Uhrzeit_01_alt 5000;
BA_REL_ "GenSigTimeoutTime" BU_SG_REL_ Bremse_ESP_EPB_EBC460Vi SG_ 1520 DI_KL_58xd 2000;
BA_REL_ "GenSigTimeoutTime" BU_SG_REL_ Bremse_ESP_EPB_MK100 SG_ 1714 DGN_Verlernzaehler 5000;
BA_REL_ "GenSigTimeoutTime" BU_SG_REL_ Bremse_ESP_EPB_MK100 SG_ 1714 KBI_Kilometerstand 5000;
BA_REL_ "GenSigTimeoutTime" BU_SG_REL_ Bremse_ESP_EPB_MK100 SG_ 1714 UH_Jahr 5000;
BA_REL_ "GenSigTimeoutTime" BU_SG_REL_ Bremse_ESP_EPB_MK100 SG_ 1714 UH_Monat 5000;
BA_REL_ "GenSigTimeoutTime" BU_SG_REL_ Bremse_ESP_EPB_MK100 SG_ 1714 UH_Tag 5000;
BA_REL_ "GenSigTimeoutTime" BU_SG_REL_ Bremse_ESP_EPB_MK100 SG_ 1714 UH_Stunde 5000;
BA_REL_ "GenSigTimeoutTime" BU_SG_REL_ Bremse_ESP_EPB_MK100 SG_ 1714 UH_Minute 5000;
BA_REL_ "GenSigTimeoutTime" BU_SG_REL_ Bremse_ESP_EPB_MK100 SG_ 1714 UH_Sekunde 5000;
BA_REL_ "GenSigTimeoutTime" BU_SG_REL_ Bremse_ESP_EPB_MK100 SG_ 1714 Kombi_02_alt 5000;
BA_REL_ "GenSigTimeoutTime" BU_SG_REL_ Bremse_ESP_EPB_MK100 SG_ 1714 Uhrzeit_01_alt 5000;
BA_REL_ "GenSigTimeoutTime" BU_SG_REL_ Bremse_ESP_EPB_MK100 SG_ 1520 DI_KL_58xd 2000;
BA_REL_ "GenSigTimeoutTime" BU_SG_REL_ Bremse_ESP_MK100 SG_ 1714 DGN_Verlernzaehler 5000;
BA_REL_ "GenSigTimeoutTime" BU_SG_REL_ Bremse_ESP_MK100 SG_ 1714 KBI_Kilometerstand 5000;
BA_REL_ "GenSigTimeoutTime" BU_SG_REL_ Bremse_ESP_MK100 SG_ 1714 UH_Jahr 5000;
BA_REL_ "GenSigTimeoutTime" BU_SG_REL_ Bremse_ESP_MK100 SG_ 1714 UH_Monat 5000;
BA_REL_ "GenSigTimeoutTime" BU_SG_REL_ Bremse_ESP_MK100 SG_ 1714 UH_Tag 5000;
BA_REL_ "GenSigTimeoutTime" BU_SG_REL_ Bremse_ESP_MK100 SG_ 1714 UH_Stunde 5000;
BA_REL_ "GenSigTimeoutTime" BU_SG_REL_ Bremse_ESP_MK100 SG_ 1714 UH_Minute 5000;
BA_REL_ "GenSigTimeoutTime" BU_SG_REL_ Bremse_ESP_MK100 SG_ 1714 UH_Sekunde 5000;
BA_REL_ "GenSigTimeoutTime" BU_SG_REL_ Bremse_ESP_MK100 SG_ 1714 Kombi_02_alt 5000;
BA_REL_ "GenSigTimeoutTime" BU_SG_REL_ Bremse_ESP_MK100 SG_ 1714 Uhrzeit_01_alt 5000;
BA_REL_ "GenSigTimeoutTime" BU_SG_REL_ Daempfer SG_ 1714 DGN_Verlernzaehler 5000;
BA_REL_ "GenSigTimeoutTime" BU_SG_REL_ Daempfer SG_ 1714 KBI_Kilometerstand 5000;
BA_REL_ "GenSigTimeoutTime" BU_SG_REL_ Daempfer SG_ 1714 UH_Jahr 5000;
BA_REL_ "GenSigTimeoutTime" BU_SG_REL_ Daempfer SG_ 1714 UH_Monat 5000;
BA_REL_ "GenSigTimeoutTime" BU_SG_REL_ Daempfer SG_ 1714 UH_Tag 5000;
BA_REL_ "GenSigTimeoutTime" BU_SG_REL_ Daempfer SG_ 1714 UH_Stunde 5000;
BA_REL_ "GenSigTimeoutTime" BU_SG_REL_ Daempfer SG_ 1714 UH_Minute 5000;
BA_REL_ "GenSigTimeoutTime" BU_SG_REL_ Daempfer SG_ 1714 UH_Sekunde 5000;
BA_REL_ "GenSigTimeoutTime" BU_SG_REL_ Daempfer SG_ 260 EPB_Freig_Verzoeg_Anf 500;
BA_REL_ "GenSigTimeoutTime" BU_SG_REL_ Daempfer SG_ 260 EPB_Verzoeg_Anf 500;
BA_REL_ "GenSigTimeoutTime" BU_SG_REL_ Daempfer SG_ 257 ESP_QBit_Gierrate 500;
BA_REL_ "GenSigTimeoutTime" BU_SG_REL_ Daempfer SG_ 257 ESP_QBit_Laengsbeschl 500;
BA_REL_ "GenSigTimeoutTime" BU_SG_REL_ Daempfer SG_ 257 ESP_QBit_Querb 500;
BA_REL_ "GenSigTimeoutTime" BU_SG_REL_ Daempfer SG_ 257 ESP_Querbeschleunigung 500;
BA_REL_ "GenSigTimeoutTime" BU_SG_REL_ Daempfer SG_ 257 ESP_Laengsbeschl 500;
BA_REL_ "GenSigTimeoutTime" BU_SG_REL_ Daempfer SG_ 257 ESP_Gierrate 500;
BA_REL_ "GenSigTimeoutTime" BU_SG_REL_ Daempfer SG_ 257 ESP_VZ_Gierrate 500;
BA_REL_ "GenSigTimeoutTime" BU_SG_REL_ Daempfer SG_ 262 ESP_QBit_Bremsdruck 500;
BA_REL_ "GenSigTimeoutTime" BU_SG_REL_ Daempfer SG_ 262 ESP_Bremsdruck 500;
BA_REL_ "GenSigTimeoutTime" BU_SG_REL_ Daempfer SG_ 914 ESP_Rollenmodus_Deaktivieren 1000;
BA_REL_ "GenSigTimeoutTime" BU_SG_REL_ Daempfer SG_ 253 ESP_v_Signal 500;
BA_REL_ "GenSigTimeoutTime" BU_SG_REL_ Daempfer SG_ 253 ESP_QBit_v_Signal 500;
BA_REL_ "GenSigTimeoutTime" BU_SG_REL_ Daempfer SG_ 253 ABS_Bremsung 500;
BA_REL_ "GenSigTimeoutTime" BU_SG_REL_ Daempfer SG_ 253 ASR_Anf 500;
BA_REL_ "GenSigTimeoutTime" BU_SG_REL_ Daempfer SG_ 253 EBV_Eingriff 500;
BA_REL_ "GenSigTimeoutTime" BU_SG_REL_ Daempfer SG_ 253 EDS_Eingriff 500;
BA_REL_ "GenSigTimeoutTime" BU_SG_REL_ Daempfer SG_ 253 ESP_Eingriff 500;
BA_REL_ "GenSigTimeoutTime" BU_SG_REL_ Gateway_MQB SG_ 257 ESP_QBit_Gierrate 500;
BA_REL_ "GenSigTimeoutTime" BU_SG_REL_ Gateway_MQB SG_ 257 ESP_QBit_Querb 500;
BA_REL_ "GenSigTimeoutTime" BU_SG_REL_ Gateway_MQB SG_ 257 ESP_Querbeschleunigung 500;
BA_REL_ "GenSigTimeoutTime" BU_SG_REL_ Gateway_MQB SG_ 257 ESC_SeitenwindAssistent_Eingriff 500;
BA_REL_ "GenSigTimeoutTime" BU_SG_REL_ Gateway_MQB SG_ 257 ESP_Gierrate 500;
BA_REL_ "GenSigTimeoutTime" BU_SG_REL_ Gateway_MQB SG_ 257 ESP_VZ_Gierrate 500;
BA_REL_ "GenSigTimeoutTime" BU_SG_REL_ Gateway_MQB SG_ 257 ESP_SpannungsAnf 500;
BA_REL_ "GenSigTimeoutTime" BU_SG_REL_ Gateway_MQB SG_ 262 ESP_QBit_Bremsdruck 500;
BA_REL_ "GenSigTimeoutTime" BU_SG_REL_ Gateway_MQB SG_ 262 ESP_QBit_Fahrer_bremst 500;
BA_REL_ "GenSigTimeoutTime" BU_SG_REL_ Gateway_MQB SG_ 262 ESP_Bremsdruck 500;
BA_REL_ "GenSigTimeoutTime" BU_SG_REL_ Gateway_MQB SG_ 262 ESP_Fahrer_bremst 500;
BA_REL_ "GenSigTimeoutTime" BU_SG_REL_ Gateway_MQB SG_ 914 ESP_Rollenmodus_Deaktivieren 1000;
BA_REL_ "GenSigTimeoutTime" BU_SG_REL_ Gateway_MQB SG_ 138 ESP_14_Status_DSR 5000;
BA_REL_ "GenSigTimeoutTime" BU_SG_REL_ Gateway_MQB SG_ 138 ESP_14_Anf_Lenkmomoffset_DSR 5000;
BA_REL_ "GenSigTimeoutTime" BU_SG_REL_ Gateway_MQB SG_ 138 ESP_14_VZ_Anf_Lenkmomoffset_DSR 5000;
BA_REL_ "GenSigTimeoutTime" BU_SG_REL_ Gateway_MQB SG_ 1629 ESP_SpannungsAnf_02 5000;
BA_REL_ "GenSigTimeoutTime" BU_SG_REL_ Gateway_MQB SG_ 1629 ESP_Zaehnezahl 5000;
BA_REL_ "GenSigTimeoutTime" BU_SG_REL_ Gateway_MQB SG_ 1629 ESP_Charisma_FahrPr 5000;
BA_REL_ "GenSigTimeoutTime" BU_SG_REL_ Gateway_MQB SG_ 1629 ESP_Charisma_Status 5000;
BA_REL_ "GenSigTimeoutTime" BU_SG_REL_ Gateway_MQB SG_ 1629 ESP_Wiederstart_Anz_01 5000;
BA_REL_ "GenSigTimeoutTime" BU_SG_REL_ Gateway_MQB SG_ 1629 ESP_Wiederstart_Anz_02 5000;
BA_REL_ "GenSigTimeoutTime" BU_SG_REL_ Gateway_MQB SG_ 1629 ESP_Wiederstart_Anz_03 5000;
BA_REL_ "GenSigTimeoutTime" BU_SG_REL_ Gateway_MQB SG_ 1629 ESP_Wiederstart_Anz_04 5000;
BA_REL_ "GenSigTimeoutTime" BU_SG_REL_ Gateway_MQB SG_ 1629 ESP_Stoppverbot_Anz_01 5000;
BA_REL_ "GenSigTimeoutTime" BU_SG_REL_ Gateway_MQB SG_ 1629 ESP_Stoppverbot_Anz_02 5000;
BA_REL_ "GenSigTimeoutTime" BU_SG_REL_ Gateway_MQB SG_ 1629 ESP_Stoppverbot_Anz_03 5000;
BA_REL_ "GenSigTimeoutTime" BU_SG_REL_ Gateway_MQB SG_ 1629 ESP_Stoppverbot_Anz_04 5000;
BA_REL_ "GenSigTimeoutTime" BU_SG_REL_ Gateway_MQB SG_ 1629 ESP_Stoppverbot_Anz_05 5000;
BA_REL_ "GenSigTimeoutTime" BU_SG_REL_ Gateway_MQB SG_ 1629 ESP_Stoppverbot_Anz_06 5000;
BA_REL_ "GenSigTimeoutTime" BU_SG_REL_ Gateway_MQB SG_ 1629 ESP_Stoppverbot_Anz_07 5000;
BA_REL_ "GenSigTimeoutTime" BU_SG_REL_ Gateway_MQB SG_ 1629 ESP_Stoppverbot_Anz_Std 5000;
BA_REL_ "GenSigTimeoutTime" BU_SG_REL_ Gateway_MQB SG_ 1629 ESP_Stoppverbot_Anz_08 5000;
BA_REL_ "GenSigTimeoutTime" BU_SG_REL_ Gateway_MQB SG_ 1629 HDC_Charisma_FahrPr 5000;
BA_REL_ "GenSigTimeoutTime" BU_SG_REL_ Gateway_MQB SG_ 1629 HDC_Charisma_Status 5000;
BA_REL_ "GenSigTimeoutTime" BU_SG_REL_ Gateway_MQB SG_ 1629 BR_QBit_Reifenumfang 5000;
BA_REL_ "GenSigTimeoutTime" BU_SG_REL_ Gateway_MQB SG_ 1629 BR_Reifenumfang 5000;
BA_REL_ "GenSigTimeoutTime" BU_SG_REL_ Gateway_MQB SG_ 253 ESP_v_Signal 500;
BA_REL_ "GenSigTimeoutTime" BU_SG_REL_ Gateway_MQB SG_ 253 ASR_Tastung_passiv 500;
BA_REL_ "GenSigTimeoutTime" BU_SG_REL_ Gateway_MQB SG_ 253 ESP_Tastung_passiv 500;
BA_REL_ "GenSigTimeoutTime" BU_SG_REL_ Gateway_MQB SG_ 253 ESP_QBit_v_Signal 500;
BA_REL_ "GenSigTimeoutTime" BU_SG_REL_ Gateway_MQB SG_ 253 ABS_Bremsung 500;
BA_REL_ "GenSigTimeoutTime" BU_SG_REL_ Gateway_MQB SG_ 253 ASR_Anf 500;
BA_REL_ "GenSigTimeoutTime" BU_SG_REL_ Gateway_MQB SG_ 253 EDS_Eingriff 500;
BA_REL_ "GenSigTimeoutTime" BU_SG_REL_ Gateway_MQB SG_ 253 ESP_Eingriff 500;
BA_REL_ "GenSigTimeoutTime" BU_SG_REL_ Lenkhilfe_EPS SG_ 1714 DGN_Verlernzaehler 5000;
BA_REL_ "GenSigTimeoutTime" BU_SG_REL_ Lenkhilfe_EPS SG_ 1714 KBI_Kilometerstand 5000;
BA_REL_ "GenSigTimeoutTime" BU_SG_REL_ Lenkhilfe_EPS SG_ 1714 UH_Jahr 5000;
BA_REL_ "GenSigTimeoutTime" BU_SG_REL_ Lenkhilfe_EPS SG_ 1714 UH_Monat 5000;
BA_REL_ "GenSigTimeoutTime" BU_SG_REL_ Lenkhilfe_EPS SG_ 1714 UH_Tag 5000;
BA_REL_ "GenSigTimeoutTime" BU_SG_REL_ Lenkhilfe_EPS SG_ 1714 UH_Stunde 5000;
BA_REL_ "GenSigTimeoutTime" BU_SG_REL_ Lenkhilfe_EPS SG_ 1714 UH_Minute 5000;
BA_REL_ "GenSigTimeoutTime" BU_SG_REL_ Lenkhilfe_EPS SG_ 1714 UH_Sekunde 5000;
BA_REL_ "GenSigTimeoutTime" BU_SG_REL_ Lenkhilfe_EPS SG_ 1714 Kombi_02_alt 5000;
BA_REL_ "GenSigTimeoutTime" BU_SG_REL_ Lenkhilfe_EPS SG_ 1714 Uhrzeit_01_alt 5000;
BA_REL_ "GenSigTimeoutTime" BU_SG_REL_ Lenkhilfe_EPS SG_ 257 ESP_02_CRC 500;
BA_REL_ "GenSigTimeoutTime" BU_SG_REL_ Lenkhilfe_EPS SG_ 257 ESP_02_BZ 500;
BA_REL_ "GenSigTimeoutTime" BU_SG_REL_ Lenkhilfe_EPS SG_ 257 ESP_QBit_Gierrate 500;
BA_REL_ "GenSigTimeoutTime" BU_SG_REL_ Lenkhilfe_EPS SG_ 257 ESP_QBit_Laengsbeschl 500;
BA_REL_ "GenSigTimeoutTime" BU_SG_REL_ Lenkhilfe_EPS SG_ 257 ESP_QBit_Querb 500;
BA_REL_ "GenSigTimeoutTime" BU_SG_REL_ Lenkhilfe_EPS SG_ 257 ESP_Querbeschleunigung 500;
BA_REL_ "GenSigTimeoutTime" BU_SG_REL_ Lenkhilfe_EPS SG_ 257 ESP_Laengsbeschl 500;
BA_REL_ "GenSigTimeoutTime" BU_SG_REL_ Lenkhilfe_EPS SG_ 257 ESP_Gierrate 500;
BA_REL_ "GenSigTimeoutTime" BU_SG_REL_ Lenkhilfe_EPS SG_ 257 ESP_VZ_Gierrate 500;
BA_REL_ "GenSigTimeoutTime" BU_SG_REL_ Lenkhilfe_EPS SG_ 262 ESP_05_CRC 500;
BA_REL_ "GenSigTimeoutTime" BU_SG_REL_ Lenkhilfe_EPS SG_ 262 ESP_05_BZ 500;
BA_REL_ "GenSigTimeoutTime" BU_SG_REL_ Lenkhilfe_EPS SG_ 262 ESP_QBit_Bremsdruck 500;
BA_REL_ "GenSigTimeoutTime" BU_SG_REL_ Lenkhilfe_EPS SG_ 262 ESP_QBit_Fahrer_bremst 500;
BA_REL_ "GenSigTimeoutTime" BU_SG_REL_ Lenkhilfe_EPS SG_ 262 ESP_Bremsdruck 500;
BA_REL_ "GenSigTimeoutTime" BU_SG_REL_ Lenkhilfe_EPS SG_ 262 ESP_Fahrer_bremst 500;
BA_REL_ "GenSigTimeoutTime" BU_SG_REL_ Lenkhilfe_EPS SG_ 278 ESP_10_CRC 500;
BA_REL_ "GenSigTimeoutTime" BU_SG_REL_ Lenkhilfe_EPS SG_ 278 ESP_10_BZ 500;
BA_REL_ "GenSigTimeoutTime" BU_SG_REL_ Lenkhilfe_EPS SG_ 278 ESP_QBit_Wegimpuls_VL 500;
BA_REL_ "GenSigTimeoutTime" BU_SG_REL_ Lenkhilfe_EPS SG_ 278 ESP_QBit_Wegimpuls_VR 500;
BA_REL_ "GenSigTimeoutTime" BU_SG_REL_ Lenkhilfe_EPS SG_ 278 ESP_QBit_Wegimpuls_HL 500;
BA_REL_ "GenSigTimeoutTime" BU_SG_REL_ Lenkhilfe_EPS SG_ 278 ESP_QBit_Wegimpuls_HR 500;
BA_REL_ "GenSigTimeoutTime" BU_SG_REL_ Lenkhilfe_EPS SG_ 278 ESP_Wegimpuls_VL 500;
BA_REL_ "GenSigTimeoutTime" BU_SG_REL_ Lenkhilfe_EPS SG_ 278 ESP_Wegimpuls_VR 500;
BA_REL_ "GenSigTimeoutTime" BU_SG_REL_ Lenkhilfe_EPS SG_ 278 ESP_Wegimpuls_HL 500;
BA_REL_ "GenSigTimeoutTime" BU_SG_REL_ Lenkhilfe_EPS SG_ 278 ESP_Wegimpuls_HR 500;
BA_REL_ "GenSigTimeoutTime" BU_SG_REL_ Lenkhilfe_EPS SG_ 278 ESP_VL_Fahrtrichtung 500;
BA_REL_ "GenSigTimeoutTime" BU_SG_REL_ Lenkhilfe_EPS SG_ 278 ESP_VR_Fahrtrichtung 500;
BA_REL_ "GenSigTimeoutTime" BU_SG_REL_ Lenkhilfe_EPS SG_ 278 ESP_HL_Fahrtrichtung 500;
BA_REL_ "GenSigTimeoutTime" BU_SG_REL_ Lenkhilfe_EPS SG_ 278 ESP_HR_Fahrtrichtung 500;
BA_REL_ "GenSigTimeoutTime" BU_SG_REL_ Lenkhilfe_EPS SG_ 138 ESP_14_CRC 5000;
BA_REL_ "GenSigTimeoutTime" BU_SG_REL_ Lenkhilfe_EPS SG_ 138 ESP_14_BZ 5000;
BA_REL_ "GenSigTimeoutTime" BU_SG_REL_ Lenkhilfe_EPS SG_ 138 ESP_14_Status_DSR 5000;
BA_REL_ "GenSigTimeoutTime" BU_SG_REL_ Lenkhilfe_EPS SG_ 138 ESP_14_Anf_Lenkmomoffset_DSR 5000;
BA_REL_ "GenSigTimeoutTime" BU_SG_REL_ Lenkhilfe_EPS SG_ 138 ESP_14_VZ_Anf_Lenkmomoffset_DSR 5000;
BA_REL_ "GenSigTimeoutTime" BU_SG_REL_ Lenkhilfe_EPS SG_ 178 ESP_HL_Radgeschw_02 500;
BA_REL_ "GenSigTimeoutTime" BU_SG_REL_ Lenkhilfe_EPS SG_ 178 ESP_HR_Radgeschw_02 500;
BA_REL_ "GenSigTimeoutTime" BU_SG_REL_ Lenkhilfe_EPS SG_ 178 ESP_VL_Radgeschw_02 500;
BA_REL_ "GenSigTimeoutTime" BU_SG_REL_ Lenkhilfe_EPS SG_ 178 ESP_VR_Radgeschw_02 500;
BA_REL_ "GenSigTimeoutTime" BU_SG_REL_ Lenkhilfe_EPS SG_ 1629 ESP_20_CRC 5000;
BA_REL_ "GenSigTimeoutTime" BU_SG_REL_ Lenkhilfe_EPS SG_ 1629 ESP_20_BZ 5000;
BA_REL_ "GenSigTimeoutTime" BU_SG_REL_ Lenkhilfe_EPS SG_ 1629 ESP_Zaehnezahl 5000;
BA_REL_ "GenSigTimeoutTime" BU_SG_REL_ Lenkhilfe_EPS SG_ 1629 BR_QBit_Reifenumfang 5000;
BA_REL_ "GenSigTimeoutTime" BU_SG_REL_ Lenkhilfe_EPS SG_ 1629 BR_Reifenumfang 5000;
BA_REL_ "GenSigTimeoutTime" BU_SG_REL_ Lenkhilfe_EPS SG_ 253 ESP_21_CRC 500;
BA_REL_ "GenSigTimeoutTime" BU_SG_REL_ Lenkhilfe_EPS SG_ 253 ESP_21_BZ 500;
BA_REL_ "GenSigTimeoutTime" BU_SG_REL_ Lenkhilfe_EPS SG_ 253 ESP_v_Signal 500;
BA_REL_ "GenSigTimeoutTime" BU_SG_REL_ Lenkhilfe_EPS SG_ 253 ASR_Schalteingriff 500;
BA_REL_ "GenSigTimeoutTime" BU_SG_REL_ Lenkhilfe_EPS SG_ 253 ESP_QBit_v_Signal 500;
BA_REL_ "GenSigTimeoutTime" BU_SG_REL_ Lenkhilfe_EPS SG_ 253 ABS_Bremsung 500;
BA_REL_ "GenSigTimeoutTime" BU_SG_REL_ Lenkhilfe_EPS SG_ 253 ASR_Anf 500;
BA_REL_ "GenSigTimeoutTime" BU_SG_REL_ Lenkhilfe_EPS SG_ 253 MSR_Anf 500;
BA_REL_ "GenSigTimeoutTime" BU_SG_REL_ Lenkhilfe_EPS SG_ 253 EBV_Eingriff 500;
BA_REL_ "GenSigTimeoutTime" BU_SG_REL_ Lenkhilfe_EPS SG_ 253 EDS_Eingriff 500;
BA_REL_ "GenSigTimeoutTime" BU_SG_REL_ Lenkhilfe_EPS SG_ 253 ESP_Eingriff 500;
BA_REL_ "GenSigTimeoutTime" BU_SG_REL_ PDC SG_ 1714 DGN_Verlernzaehler 5000;
BA_REL_ "GenSigTimeoutTime" BU_SG_REL_ PDC SG_ 1714 KBI_Kilometerstand 5000;
BA_REL_ "GenSigTimeoutTime" BU_SG_REL_ PDC SG_ 1714 UH_Jahr 5000;
BA_REL_ "GenSigTimeoutTime" BU_SG_REL_ PDC SG_ 1714 UH_Monat 5000;
BA_REL_ "GenSigTimeoutTime" BU_SG_REL_ PDC SG_ 1714 UH_Tag 5000;
BA_REL_ "GenSigTimeoutTime" BU_SG_REL_ PDC SG_ 1714 UH_Stunde 5000;
BA_REL_ "GenSigTimeoutTime" BU_SG_REL_ PDC SG_ 1714 UH_Minute 5000;
BA_REL_ "GenSigTimeoutTime" BU_SG_REL_ PDC SG_ 1714 UH_Sekunde 5000;
BA_REL_ "GenSigTimeoutTime" BU_SG_REL_ PDC SG_ 1714 Uhrzeit_01_alt 5000;
BA_REL_ "GenSigTimeoutTime" BU_SG_REL_ PDC SG_ 1520 DI_KL_58xd 2000;
BA_REL_ "GenSigTimeoutTime" BU_SG_REL_ PDC SG_ 260 EPB_Fehlerstatus 500;
BA_REL_ "GenSigTimeoutTime" BU_SG_REL_ PDC SG_ 260 EPB_Status 500;
BA_REL_ "GenSigTimeoutTime" BU_SG_REL_ PDC SG_ 257 ESP_Gierrate 500;
BA_REL_ "GenSigTimeoutTime" BU_SG_REL_ PDC SG_ 257 ESP_VZ_Gierrate 500;
BA_REL_ "GenSigTimeoutTime" BU_SG_REL_ PDC SG_ 914 ESP_Rollenmodus_Deaktivieren 1000;
BA_REL_ "GenSigTimeoutTime" BU_SG_REL_ PDC SG_ 278 ESP_10_CRC 500;
BA_REL_ "GenSigTimeoutTime" BU_SG_REL_ PDC SG_ 278 ESP_10_BZ 500;
BA_REL_ "GenSigTimeoutTime" BU_SG_REL_ PDC SG_ 278 ESP_QBit_Wegimpuls_VL 500;
BA_REL_ "GenSigTimeoutTime" BU_SG_REL_ PDC SG_ 278 ESP_QBit_Wegimpuls_VR 500;
BA_REL_ "GenSigTimeoutTime" BU_SG_REL_ PDC SG_ 278 ESP_QBit_Wegimpuls_HL 500;
BA_REL_ "GenSigTimeoutTime" BU_SG_REL_ PDC SG_ 278 ESP_QBit_Wegimpuls_HR 500;
BA_REL_ "GenSigTimeoutTime" BU_SG_REL_ PDC SG_ 278 ESP_Wegimpuls_VL 500;
BA_REL_ "GenSigTimeoutTime" BU_SG_REL_ PDC SG_ 278 ESP_Wegimpuls_VR 500;
BA_REL_ "GenSigTimeoutTime" BU_SG_REL_ PDC SG_ 278 ESP_Wegimpuls_HL 500;
BA_REL_ "GenSigTimeoutTime" BU_SG_REL_ PDC SG_ 278 ESP_Wegimpuls_HR 500;
BA_REL_ "GenSigTimeoutTime" BU_SG_REL_ PDC SG_ 278 ESP_VL_Fahrtrichtung 500;
BA_REL_ "GenSigTimeoutTime" BU_SG_REL_ PDC SG_ 278 ESP_VR_Fahrtrichtung 500;
BA_REL_ "GenSigTimeoutTime" BU_SG_REL_ PDC SG_ 278 ESP_HL_Fahrtrichtung 500;
BA_REL_ "GenSigTimeoutTime" BU_SG_REL_ PDC SG_ 278 ESP_HR_Fahrtrichtung 500;
BA_REL_ "GenSigTimeoutTime" BU_SG_REL_ PDC SG_ 178 ESP_HL_Radgeschw_02 500;
BA_REL_ "GenSigTimeoutTime" BU_SG_REL_ PDC SG_ 178 ESP_HR_Radgeschw_02 500;
BA_REL_ "GenSigTimeoutTime" BU_SG_REL_ PDC SG_ 178 ESP_VL_Radgeschw_02 500;
BA_REL_ "GenSigTimeoutTime" BU_SG_REL_ PDC SG_ 178 ESP_VR_Radgeschw_02 500;
BA_REL_ "GenSigTimeoutTime" BU_SG_REL_ PDC SG_ 253 ESP_21_CRC 500;
BA_REL_ "GenSigTimeoutTime" BU_SG_REL_ PDC SG_ 253 ESP_21_BZ 500;
BA_REL_ "GenSigTimeoutTime" BU_SG_REL_ PDC SG_ 253 ESP_v_Signal 500;
BA_REL_ "GenSigTimeoutTime" BU_SG_REL_ PDC SG_ 253 ASR_Tastung_passiv 500;
BA_REL_ "GenSigTimeoutTime" BU_SG_REL_ PDC SG_ 253 ESP_Tastung_passiv 500;
BA_REL_ "GenSigTimeoutTime" BU_SG_REL_ PDC SG_ 253 ESP_Systemstatus 500;
BA_REL_ "GenSigTimeoutTime" BU_SG_REL_ PDC SG_ 253 ESP_Haltebestaetigung 500;
BA_REL_ "GenSigTimeoutTime" BU_SG_REL_ PDC SG_ 253 ESP_QBit_v_Signal 500;
BA_REL_ "GenSigTimeoutTime" BU_SG_REL_ PDC SG_ 253 ABS_Bremsung 500;
BA_REL_ "GenSigTimeoutTime" BU_SG_REL_ PDC SG_ 253 ASR_Anf 500;
BA_REL_ "GenSigTimeoutTime" BU_SG_REL_ PDC SG_ 253 MSR_Anf 500;
BA_REL_ "GenSigTimeoutTime" BU_SG_REL_ PDC SG_ 253 EDS_Eingriff 500;
BA_REL_ "GenSigTimeoutTime" BU_SG_REL_ PDC SG_ 253 ESP_Eingriff 500;
BA_REL_ "GenSigTimeoutTime" BU_SG_REL_ PDC_PLA SG_ 1714 DGN_Verlernzaehler 5000;
BA_REL_ "GenSigTimeoutTime" BU_SG_REL_ PDC_PLA SG_ 1714 KBI_Kilometerstand 5000;
BA_REL_ "GenSigTimeoutTime" BU_SG_REL_ PDC_PLA SG_ 1714 UH_Jahr 5000;
BA_REL_ "GenSigTimeoutTime" BU_SG_REL_ PDC_PLA SG_ 1714 UH_Monat 5000;
BA_REL_ "GenSigTimeoutTime" BU_SG_REL_ PDC_PLA SG_ 1714 UH_Tag 5000;
BA_REL_ "GenSigTimeoutTime" BU_SG_REL_ PDC_PLA SG_ 1714 UH_Stunde 5000;
BA_REL_ "GenSigTimeoutTime" BU_SG_REL_ PDC_PLA SG_ 1714 UH_Minute 5000;
BA_REL_ "GenSigTimeoutTime" BU_SG_REL_ PDC_PLA SG_ 1714 UH_Sekunde 5000;
BA_REL_ "GenSigTimeoutTime" BU_SG_REL_ PDC_PLA SG_ 1714 Uhrzeit_01_alt 5000;
BA_REL_ "GenSigTimeoutTime" BU_SG_REL_ PDC_PLA SG_ 1520 DI_KL_58xd 2000;
BA_REL_ "GenSigTimeoutTime" BU_SG_REL_ PDC_PLA SG_ 260 EPB_Fehlerstatus 500;
BA_REL_ "GenSigTimeoutTime" BU_SG_REL_ PDC_PLA SG_ 260 EPB_Status 500;
BA_REL_ "GenSigTimeoutTime" BU_SG_REL_ PDC_PLA SG_ 257 ESP_02_CRC 500;
BA_REL_ "GenSigTimeoutTime" BU_SG_REL_ PDC_PLA SG_ 257 ESP_02_BZ 500;
BA_REL_ "GenSigTimeoutTime" BU_SG_REL_ PDC_PLA SG_ 257 ESP_QBit_Gierrate 500;
BA_REL_ "GenSigTimeoutTime" BU_SG_REL_ PDC_PLA SG_ 257 ESP_QBit_Laengsbeschl 500;
BA_REL_ "GenSigTimeoutTime" BU_SG_REL_ PDC_PLA SG_ 257 ESP_Laengsbeschl 500;
BA_REL_ "GenSigTimeoutTime" BU_SG_REL_ PDC_PLA SG_ 257 ESP_Gierrate 500;
BA_REL_ "GenSigTimeoutTime" BU_SG_REL_ PDC_PLA SG_ 257 ESP_VZ_Gierrate 500;
BA_REL_ "GenSigTimeoutTime" BU_SG_REL_ PDC_PLA SG_ 257 ESP_PLA_Abbruch 500;
BA_REL_ "GenSigTimeoutTime" BU_SG_REL_ PDC_PLA SG_ 257 ESP_Status_ESP_PLA 500;
BA_REL_ "GenSigTimeoutTime" BU_SG_REL_ PDC_PLA SG_ 262 ESP_05_CRC 500;
BA_REL_ "GenSigTimeoutTime" BU_SG_REL_ PDC_PLA SG_ 262 ESP_05_BZ 500;
BA_REL_ "GenSigTimeoutTime" BU_SG_REL_ PDC_PLA SG_ 262 ESP_QBit_Bremsdruck 500;
BA_REL_ "GenSigTimeoutTime" BU_SG_REL_ PDC_PLA SG_ 262 ESP_Bremsdruck 500;
BA_REL_ "GenSigTimeoutTime" BU_SG_REL_ PDC_PLA SG_ 914 ESP_Rollenmodus_Deaktivieren 1000;
BA_REL_ "GenSigTimeoutTime" BU_SG_REL_ PDC_PLA SG_ 278 ESP_10_CRC 500;
BA_REL_ "GenSigTimeoutTime" BU_SG_REL_ PDC_PLA SG_ 278 ESP_10_BZ 500;
BA_REL_ "GenSigTimeoutTime" BU_SG_REL_ PDC_PLA SG_ 278 ESP_QBit_Wegimpuls_VL 500;
BA_REL_ "GenSigTimeoutTime" BU_SG_REL_ PDC_PLA SG_ 278 ESP_QBit_Wegimpuls_VR 500;
BA_REL_ "GenSigTimeoutTime" BU_SG_REL_ PDC_PLA SG_ 278 ESP_QBit_Wegimpuls_HL 500;
BA_REL_ "GenSigTimeoutTime" BU_SG_REL_ PDC_PLA SG_ 278 ESP_QBit_Wegimpuls_HR 500;
BA_REL_ "GenSigTimeoutTime" BU_SG_REL_ PDC_PLA SG_ 278 ESP_Wegimpuls_VL 500;
BA_REL_ "GenSigTimeoutTime" BU_SG_REL_ PDC_PLA SG_ 278 ESP_Wegimpuls_VR 500;
BA_REL_ "GenSigTimeoutTime" BU_SG_REL_ PDC_PLA SG_ 278 ESP_Wegimpuls_HL 500;
BA_REL_ "GenSigTimeoutTime" BU_SG_REL_ PDC_PLA SG_ 278 ESP_Wegimpuls_HR 500;
BA_REL_ "GenSigTimeoutTime" BU_SG_REL_ PDC_PLA SG_ 278 ESP_VL_Fahrtrichtung 500;
BA_REL_ "GenSigTimeoutTime" BU_SG_REL_ PDC_PLA SG_ 278 ESP_VR_Fahrtrichtung 500;
BA_REL_ "GenSigTimeoutTime" BU_SG_REL_ PDC_PLA SG_ 278 ESP_HL_Fahrtrichtung 500;
BA_REL_ "GenSigTimeoutTime" BU_SG_REL_ PDC_PLA SG_ 278 ESP_HR_Fahrtrichtung 500;
BA_REL_ "GenSigTimeoutTime" BU_SG_REL_ PDC_PLA SG_ 418 HMS_Konsistenz_IPA 2000;
BA_REL_ "GenSigTimeoutTime" BU_SG_REL_ PDC_PLA SG_ 418 HMS_Systemstatus 2000;
BA_REL_ "GenSigTimeoutTime" BU_SG_REL_ PDC_PLA SG_ 418 HMS_Stillstand 2000;
BA_REL_ "GenSigTimeoutTime" BU_SG_REL_ PDC_PLA SG_ 418 HMS_aktives_System 2000;
BA_REL_ "GenSigTimeoutTime" BU_SG_REL_ PDC_PLA SG_ 418 HMS_Fehlerstatus 2000;
BA_REL_ "GenSigTimeoutTime" BU_SG_REL_ PDC_PLA SG_ 178 ESP_HL_Radgeschw_02 500;
BA_REL_ "GenSigTimeoutTime" BU_SG_REL_ PDC_PLA SG_ 178 ESP_HR_Radgeschw_02 500;
BA_REL_ "GenSigTimeoutTime" BU_SG_REL_ PDC_PLA SG_ 178 ESP_VL_Radgeschw_02 500;
BA_REL_ "GenSigTimeoutTime" BU_SG_REL_ PDC_PLA SG_ 178 ESP_VR_Radgeschw_02 500;
BA_REL_ "GenSigTimeoutTime" BU_SG_REL_ PDC_PLA SG_ 1629 ESP_Zaehnezahl 5000;
BA_REL_ "GenSigTimeoutTime" BU_SG_REL_ PDC_PLA SG_ 253 ESP_21_CRC 500;
BA_REL_ "GenSigTimeoutTime" BU_SG_REL_ PDC_PLA SG_ 253 ESP_21_BZ 500;
BA_REL_ "GenSigTimeoutTime" BU_SG_REL_ PDC_PLA SG_ 253 ESP_Vorsteuerung 500;
BA_REL_ "GenSigTimeoutTime" BU_SG_REL_ PDC_PLA SG_ 253 ESP_v_Signal 500;
BA_REL_ "GenSigTimeoutTime" BU_SG_REL_ PDC_PLA SG_ 253 ASR_Tastung_passiv 500;
BA_REL_ "GenSigTimeoutTime" BU_SG_REL_ PDC_PLA SG_ 253 ESP_Tastung_passiv 500;
BA_REL_ "GenSigTimeoutTime" BU_SG_REL_ PDC_PLA SG_ 253 ESP_Systemstatus 500;
BA_REL_ "GenSigTimeoutTime" BU_SG_REL_ PDC_PLA SG_ 253 ESP_Haltebestaetigung 500;
BA_REL_ "GenSigTimeoutTime" BU_SG_REL_ PDC_PLA SG_ 253 ESP_QBit_v_Signal 500;
BA_REL_ "GenSigTimeoutTime" BU_SG_REL_ PDC_PLA SG_ 253 ABS_Bremsung 500;
BA_REL_ "GenSigTimeoutTime" BU_SG_REL_ PDC_PLA SG_ 253 ASR_Anf 500;
BA_REL_ "GenSigTimeoutTime" BU_SG_REL_ PDC_PLA SG_ 253 MSR_Anf 500;
BA_REL_ "GenSigTimeoutTime" BU_SG_REL_ PDC_PLA SG_ 253 EDS_Eingriff 500;
BA_REL_ "GenSigTimeoutTime" BU_SG_REL_ PDC_PLA SG_ 253 ESP_Eingriff 500;
VAL_ 1714 DGN_Verlernzaehler 255 "ungültiger Zählerstand oder kein gültiger Fahrzyklus" ;
VAL_ 1714 KBI_Kilometerstand 1048574 "Init" 1048575 "Fehler" ;
VAL_ 1714 UH_Monat 0 "Init" 14 "reserviert" 15 "Fehler" ;
VAL_ 1714 UH_Tag 0 "Init" ;
VAL_ 1714 Vehicle_Driving_Cycle 0 "kein_Driving_Cycle_erkannt" 1 "Driving_Cycle_erkannt" ;
VAL_ 1714 Kombi_02_alt 0 "aktuell" 1 "veraltet" ;
VAL_ 1714 Uhrzeit_01_alt 0 "aktuell" 1 "veraltet" ;
VAL_ 1520 DI_KL_58xd 254 "Init" 255 "Fehler" ;
VAL_ 1520 DI_KL_58xs 126 "Init" 127 "Fehler" ;
VAL_ 1520 DI_KL_58xt 126 "Init" 127 "Fehler" ;
VAL_ 1520 BCM1_Stellgroesse_Kl_58s 125 "Nicht_verbaut" 126 "Init" 127 "Fehler" ;
VAL_ 260 EPB_QBit_Laengsbeschleunigung 0 "gültiger Wert" 1 "Ersatz-, Init- oder Fehlerwert" ;
VAL_ 260 EPB_QBit_Pedalweg_Kuppl 0 "gültiger Wert" 1 "Ersatz-, Init- oder Fehlerwert" ;
VAL_ 260 EPB_Freig_Verzoeg_Anf 0 "nicht freigegeben" 1 "freigegeben" ;
VAL_ 260 EPB_Pedalweg_Kuppl 0 "Init" 255 "Fehler" ;
VAL_ 260 EPB_DAA_Randbed_erf 0 "Randbed_nicht_erfuellt" 1 "Randbed_erfuellt" ;
VAL_ 260 EPB_Fehlerstatus 0 "kein_Fehler_in_EPB__AVH_darf_von_ESP_ausgefuehrt_werden" 1 "temporaer_nicht_verfuegbar_Grund_1" 2 "temporaer_nicht_verfuegbar_Grund_2" 3 "Fehler_in_EPB__AVH_darf_von_ESP_nicht_ausgefuehrt_werden" ;
VAL_ 260 EPB_Schalterposition 0 "keine Fahreranforderung" 1 "Fahreranforderung Öffnen" 2 "Fahreranforderung Schließen" 3 "Fehler" ;
VAL_ 260 EPB_QBit_Schalterpos 0 "gültiger Wert (volle Funktion)" 1 " Ersatz-, Init- oder Fehlerwert (Schalter ausser Funktion)" ;
VAL_ 260 EPB_Spannkraft 30 "Init" 31 "Fehler" ;
VAL_ 260 EPB_Status 0 "offen" 1 "Bremse_geschl_(Spannkraft_voll/reduziert)" 2 "Aktuator_im_Lauf" 3 "Fehler_oder_unbekannt" ;
VAL_ 781 EPB_Fehlerlampe_Gelb 0 "Aus" 1 "Ein" ;
VAL_ 781 EPB_Fehlerlampe_BKL 0 "BKL aus" 1 "BKL an" ;
VAL_ 781 EPB_Funktionslampe 0 "Aus" 1 "Ein" ;
VAL_ 781 EPB_Texte 0 "keine_Anzeige" 1 "Neigungswinkel_zu_gross" 2 "Parkbremse_von_Hand_oeffnen" 3 "HU_Modus_oder_EPB_in_Diagnose" 4 "Bremspedal_betaetigen" 5 "tbd" 6 "tbd" 7 "Stoerung_Anfahrassistent" 8 "Abschleppschutz_blockiert" 9 "Feststellbremse_nicht_automatisch_geschlossen" 10 "Parkbremse_loesen_nicht_moeglich_Ladekabel_gesteckt" 11 "Notbremsung_ueber_EPB_Taster" 12 "Parkbremse_angezogen" 13 "Parkbremse_loesen_nicht_moeglich_ParkPilot_aktiv" ;
VAL_ 781 EPB_Akustik 0 "Warnton aus" 1 "Warnton an" ;
VAL_ 781 EPB_Autoholdlampe 0 "Lampe aus (Autohold inaktiv)" 1 "Lampe ein (Autohold aktiv)" ;
VAL_ 781 EPB_Bremsbelag_Warn 0 "Bremsbelag_ok" 1 "Bremsbelag_unter_Minimum" ;
VAL_ 781 EPB_Fehlermeldungen 0 "keine_Anzeige" 1 "Systemstoerung_Kl15an" 2 "Systemstoerung_Kl15aus" 3 "Parkbremse_betaetigen" 4 "Systemstoerung_Hanghaltefaehigkeit" 5 "Funktionseinschraenkung_Kl15an" 6 "Funktionseinschraenkung_Kl15aus" 7 "HU_Modus_aktiv" 8 "Transportmodus" 9 "Produktionsmodus" ;
VAL_ 2527679683 ESC_ASM_Ereignis 0 "No_Event" 255 "ASM_Trigger" ;
VAL_ 2527679683 ESC_ASM_Zeitstempel 255 "Init" ;
VAL_ 257 ESP_QBit_Gierrate 0 "gueltiger_Wert" 1 "Ersatz_Init_oder_Fehlerwert" ;
VAL_ 257 ESP_QBit_Laengsbeschl 0 "gueltiger_Wert" 1 "Ersatz_Init_oder_Fehlerwert" ;
VAL_ 257 ESP_QBit_Querb 0 "gueltiger_Wert" 1 "Ersatz_Init_oder_Fehlerwert" ;
VAL_ 257 ESP_Stillstandsflag 0 "kein_Stillstand_erkannt" 1 "Stillstand_erkannt" ;
VAL_ 257 ESP_Querbeschleunigung 255 "Fehler" ;
VAL_ 257 ESP_Laengsbeschl 1022 "Signal_nicht_vorhanden" 1023 "Fehler" ;
VAL_ 257 ESC_Motorstartverzoegerung 0 "Startfreigabe" 1 "Anforderung_Startverzoegerung" ;
VAL_ 257 ESC_SeitenwindAssistent_Eingriff 0 "Kein_SWA_Eingriff_und_Init" 1 "SWA_Eingriff_aktiv" ;
VAL_ 257 ESP_Anschleppstart_Freigabe 0 "kein_Schleppstart_oder_NotSchleppstart_erlaubt" 1 "NotSchleppstart_erlaubt" 2 "Schleppstart_und_NotSchleppStart_erlaubt" ;
VAL_ 257 ESP_QBit_Anf_Vert_Wank 0 "gueltiger_Wert" 1 "Ersatz_Init_oder_Fehlerwert" ;
VAL_ 257 ESP_Gierrate 16383 "Fehler" ;
VAL_ 257 ESP_VZ_Gierrate 0 "positiv" 1 "negativ" ;
VAL_ 257 ESP_Notbremsanzeige 0 "keine_Notbremsung_erkannt" 1 "Notbremsung_erkannt" ;
VAL_ 257 ESP_SpannungsAnf 0 "keine_Anforderung" 1 "Anforderung_Spannungswert_1" ;
VAL_ 257 ESP_PLA_Abbruch 0 "Init" 1 "Geschwindigkeitsueberschreitung" 2 "Falscher_PLA_Status" 3 "Deaktivierung_durch_Abbruch_Lenkung" 4 "PLA_Bremsanforderung_nach_Stillstand" 5 "Abbruch_durch_Kl15_aus" 6 "Abbruch_durch_FT_offen" ;
VAL_ 257 ESP_Status_ESP_PLA 0 "ESP_PLA_deaktiv" 1 "ESP_PLA_Init" 2 "ESP_PLA_Fehler" 4 "ESP_PLA_aktivierbar" 6 "ESP_PLA_Bremse_aktiv" 8 "ESP_PLA_funktionsbereit" 9 "ESP_PLA_Neustart" 10 "ESP_PLA_Abbruch" ;
VAL_ 262 ESP_QBit_Bremsdruck 0 "gueltiger_Wert" 1 "Ersatz_Init_oder_Fehlerwert" ;
VAL_ 262 ESP_QBit_Fahrer_bremst 0 "gueltiger_Wert" 1 "Ersatz_Init_oder_Fehlerwert" ;
VAL_ 262 ESP_Schwelle_Unterdruck 0 "kein_Signal" 1 "Unterdruck_kleiner_gleich_450_mbar" 2 "Unterdruck_groesser_450_mbar" 3 "Fehler_Unterdrucksensor" ;
VAL_ 262 ESP_Bremsdruck 1023 "Fehler" ;
VAL_ 262 ESP_Fahrer_bremst 0 "Bremsdruckschwelle_nicht_ueberschritten" 1 "Bremsdruckschwelle_ueberschritten" ;
VAL_ 262 ESP_Verz_TSK_aktiv 0 "TSK_Verzoegerung_inaktiv" 1 "TSK_Verzoegerung_aktiv" ;
VAL_ 262 ESP_Lenkeingriff_ADS 0 "kein_Lenkeingriff" 1 "stabilisierender_Lenkeingriff" ;
VAL_ 262 ESP_Konsistenz_TSK 0 "Botschaft_fuer_Verzoegerungsanforderung_konsistent" 1 "Botschaft_fuer_Verzoegerungsanforderung_nicht_konsistent" ;
VAL_ 262 ESP_Bremsruck_AWV2 0 "kein_Bremsruck_ausgefuehrt" 1 "Bremsruck_ausgefuehrt" ;
VAL_ 262 ESP_Konsistenz_AWV2 0 "Botschaft_fuer_AWV2_konsistent" 1 "Botschaft_fuer_AWV2_nicht_konsistent" ;
VAL_ 262 ECD_Fehler 0 "ECD_iO" 1 "ECD_Fehler" ;
VAL_ 262 ECD_nicht_verfuegbar 0 "ECD_Funktion_verfuegbar" 1 "ECD_Funktion_nicht_verfuegbar" ;
VAL_ 262 ESP_Status_Bremsentemp 0 "Bremse_nicht_ueberhitzt" 1 "Bremse_ueberhitzt" ;
VAL_ 262 ESP_Autohold_Standby 0 "Autohold_nicht_im_Standby" 1 "Autohold_im_Standby" ;
VAL_ 262 ESP_HDC_Standby 0 "HDC_Funktion_nicht_im_Standby" 1 "HDC_Funktion_im_Standby" ;
VAL_ 262 ESP_HBA_aktiv 0 "HBA_nicht_aktiv" 1 "HBA_aktiv" ;
VAL_ 262 ESP_Prefill_ausgeloest 0 "nicht_ausgeloest" 1 "Prefill_ausgeloest" ;
VAL_ 262 ESP_Rueckwaertsfahrt_erkannt 0 "keine_Rueckwaetsfahrt" 1 "Rueckwaertsfahrt_sicher_erkannt" ;
VAL_ 262 ESP_Status_Anfahrhilfe 0 "Aus" 1 "Ein" ;
VAL_ 262 ESP_HDC_aktiv 0 "inaktiv" 1 "aktiv" ;
VAL_ 262 ESP_StartStopp_Info 0 "Motorlauf_nicht_notwendig_(Stoppfreigabe)" 1 "Motoranlauf_nicht_zwingend_notwendig_(Stoppverbot,keine_Startanforderung)" 2 "Motoranlauf_zwingend_notwendig_(Startanforderung)" 3 "Systemfehler" ;
VAL_ 262 ESP_Eingr_HL 0 "kein_Eingriff" 1 "ESP_Eingriff_HL" ;
VAL_ 262 ESP_Eingr_HR 0 "kein_Eingriff" 1 "ESP_Eingriff_HR" ;
VAL_ 262 ESP_Eingr_VL 0 "kein_Eingriff" 1 "ESP_Eingriff_VL" ;
VAL_ 262 ESP_Eingr_VR 0 "kein_Eingriff" 1 "ESP_Eingriff_VR" ;
VAL_ 262 ESP_BKV_Unterdruck 0 "nicht_verbaut_oder_nicht_kodiert" 254 "Init" 255 "Fehler" ;
VAL_ 262 ESP_Autohold_aktiv 0 "Autohold_inaktiv" 1 "Autohold_aktiv" ;
VAL_ 262 ESP_FStatus_Anfahrhilfe 0 "kein_Fehler" 1 "Fehler" ;
VAL_ 262 ESP_Verz_EPB_aktiv 0 "nicht_aktiviert" 1 "aktiviert" ;
VAL_ 262 ECD_Bremslicht 0 "Aus" 1 "Ein" ;
VAL_ 262 ESP_Verzoeg_EPB_verf 0 "nicht_verfuegbar" 1 "System_verfuegbar" ;
VAL_ 262 ESP_Status_Bremsdruck 0 "Bremse_drucklos" 1 "mit_Bremsdruck" ;
VAL_ 262 ESP_Anforderung_EPB 0 "keine_Anforderung" 1 "Anforderung_Oeffnen" 2 "Anforderung_Schliessen" 3 "reserviert" ;
VAL_ 914 ESP_ACC_LDE 0 "Lebensdauerende_nicht_erreicht" 1 "Lebensdauerende_erreicht" ;
VAL_ 914 ESP_Allrad_Antrieb 0 "Front" 1 "Allrad" ;
VAL_ 914 ESP_Codierung_ADS 0 "Init" 1 "ESP_nicht_ADS_codiert" 2 "ADS_codiert" 3 "tbd" ;
VAL_ 914 ESP_RTA_HL 254 "Abgleich_nocht_nicht_genuegend_konvergent" 255 "Fehler" ;
VAL_ 914 ESP_RTA_HR 254 "Abgleich_nocht_nicht_genuegend_konvergent" 255 "Fehler" ;
VAL_ 914 ESP_RTA_VR 254 "Abgleich_nocht_nicht_genuegend_konvergent" 255 "Fehler" ;
VAL_ 914 OBD_Fehler_Radsensor_HL 0 "kein Fehler / Init / nicht verbaut" 1 "KS- (Kurzschluss nach minus)" 2 "KS+ (Kurzschluss nach plus)" 3 "OC (Leitungsunterbrechung)" 4 "OOR+ (Signal zu gross)" 5 "OOR- (Signal zu klein)" 6 "RC+ (Signal unplausibel zu gross)" 7 "RC- (Signal unplausibel zu klein)" 8 "KS+/OC (Kurzschluss nach plus/Unterbrechung)" 9 "KS-/OC  (Kurzschluss nach minus/Unterbrechung)" 10 "KS-/KS+  (Kurzschluss nach minus/plus)" 11 "KS-/KS+/OC (Kurzschluss nach minus/plus/Unterbrechung)" 12 "frei" 13 "frei" 14 "frei" 15 "frei" ;
VAL_ 914 OBD_Fehler_Radsensor_HR 0 "kein Fehler / Init / nicht verbaut" 1 "KS- (Kurzschluss nach minus)" 2 "KS+ (Kurzschluss nach plus)" 3 "OC (Leitungsunterbrechung)" 4 "OOR+ (Signal zu gross)" 5 "OOR- (Signal zu klein)" 6 "RC+ (Signal unplausibel zu gross)" 7 "RC- (Signal unplausibel zu klein)" 8 "KS+/OC (Kurzschluss nach plus/Unterbrechung)" 9 "KS-/OC  (Kurzschluss nach minus/Unterbrechung)" 10 "KS-/KS+  (Kurzschluss nach minus/plus)" 11 "KS-/KS+/OC (Kurzschluss nach minus/plus/Unterbrechung)" 12 "frei" 13 "frei" 14 "frei" 15 "frei" ;
VAL_ 914 OBD_Fehler_Radsensor_VL 0 "kein Fehler / Init / nicht verbaut" 1 "KS- (Kurzschluss nach minus)" 2 "KS+ (Kurzschluss nach plus)" 3 "OC (Leitungsunterbrechung)" 4 "OOR+ (Signal zu gross)" 5 "OOR- (Signal zu klein)" 6 "RC+ (Signal unplausibel zu gross)" 7 "RC- (Signal unplausibel zu klein)" 8 "KS+/OC (Kurzschluss nach plus/Unterbrechung)" 9 "KS-/OC  (Kurzschluss nach minus/Unterbrechung)" 10 "KS-/KS+  (Kurzschluss nach minus/plus)" 11 "KS-/KS+/OC (Kurzschluss nach minus/plus/Unterbrechung)" 12 "frei" 13 "frei" 14 "frei" 15 "frei" ;
VAL_ 914 OBD_Fehler_Radsensor_VR 0 "kein Fehler / Init / nicht verbaut" 1 "KS- (Kurzschluss nach minus)" 2 "KS+ (Kurzschluss nach plus)" 3 "OC (Leitungsunterbrechung)" 4 "OOR+ (Signal zu gross)" 5 "OOR- (Signal zu klein)" 6 "RC+ (Signal unplausibel zu gross)" 7 "RC- (Signal unplausibel zu klein)" 8 "KS+/OC (Kurzschluss nach plus/Unterbrechung)" 9 "KS-/OC  (Kurzschluss nach minus/Unterbrechung)" 10 "KS-/KS+  (Kurzschluss nach minus/plus)" 11 "KS-/KS+/OC (Kurzschluss nach minus/plus/Unterbrechung)" 12 "frei" 13 "frei" 14 "frei" 15 "frei" ;
VAL_ 914 ESP_Qualifizierung_Antriebsart 0 "alte_Bedeutung_Bit_ESP_Allrad_Antrieb" 1 "neue_Bedeutung_Bit_ESP_Allrad_Antrieb" ;
VAL_ 914 ESP_Offroad_Modus 0 "kein_ESP_Offroadmodus" 1 "ESP_Offroadmodus" ;
VAL_ 914 ESP_MKB_ausloesbar 0 "Multikollisionsbremsung_nicht_freigeschaltet" 1 "Multikollisionsbremsung_freigeschaltet" ;
VAL_ 914 ESP_Stat_FallBack_eBKV 0 "Rueckfallebene_nicht_vorhanden" 1 "Rueckfallebene_vorhanden" ;
VAL_ 914 ESP_CM_Variante 0 "Standard" 1 "Erweitert" ;
VAL_ 914 ESP_OBD_Status 0 "MIL_aus" 1 "MIL_ein" ;
VAL_ 914 ESP_Rollenmodus_Deaktivieren 0 "keine_Aenderung" 1 "Abbruch" ;
VAL_ 914 ESP_nachtr_Stopp_Anf 0 "nicht_angefordert" 1 "angefordert" ;
VAL_ 286 ESP_ANB_CM_Rueckk_Umsetz 0 "keine_Ausfuehrung" 1 "Ausfuehrung" ;
VAL_ 286 ESP_Konsistenz_ACC_Botschaft 0 "Botschaft_fuer_ACC_konsistent" 1 "Botschaft_fuer_ACC_nicht_konsistent" ;
VAL_ 286 ESP_Stillstandsphase_erschoepft 0 "sicheres_Halten_moeglich" 1 "kein_sicheres_Halten_moeglich" ;
VAL_ 286 ESP_ZT_Rueckk_Umsetz 0 "keine_Ausfuehrung" 1 "Ausfuehrung" ;
VAL_ 286 ESP_Tuerkontakt_Fahrertuer 0 "Schalter_geschlossen" 1 "Schalter_offen" ;
VAL_ 286 ESP_Abrutschen_Stillstand 0 "kein_Abrutschen_erkannt" 1 "Abrutschen_erkannt" ;
VAL_ 286 ESP_Fahrer_tritt_ZBR_Schw 0 "Fahrer_uebertritt_ZBR_Schwelle_nicht" 1 "Fahrer_uebertritt_ZBR_Schwelle" ;
VAL_ 286 ESP_QBit_v_ref 0 "gueltiger_Wert" 1 "Ersatz_Init_oder_Fehlerwert" ;
VAL_ 286 ESP_v_ref_Fahrtrichtung 0 "Fahrtrichtung_nicht_definiert" 1 "Vorwaerts" 2 "Rueckwaerts" 3 "Stillstand" ;
VAL_ 286 ESC_Bremsdruckgradient 251 "groesser_2500_bar_per_sec" 254 "Init" 255 "Fehler" ;
VAL_ 286 ESP_v_ref 4093 "Unterspannung" 4094 "Init" 4095 "Fehler" ;
VAL_ 278 ESP_QBit_Wegimpuls_VL 0 "gueltiger_Wert" 1 "Ersatz_Init_oder_Fehlerwert" ;
VAL_ 278 ESP_QBit_Wegimpuls_VR 0 "gueltiger_Wert" 1 "Ersatz_Init_oder_Fehlerwert" ;
VAL_ 278 ESP_QBit_Wegimpuls_HL 0 "gueltiger_Wert" 1 "Ersatz_Init_oder_Fehlerwert" ;
VAL_ 278 ESP_QBit_Wegimpuls_HR 0 "gueltiger_Wert" 1 "Ersatz_Init_oder_Fehlerwert" ;
VAL_ 278 ESP_Wegimpuls_VL 1021 "Init" 1022 "Unterspannung" 1023 "Fehler" ;
VAL_ 278 ESP_Wegimpuls_VR 1021 "Init" 1022 "Unterspannung" 1023 "Fehler" ;
VAL_ 278 ESP_Wegimpuls_HL 1021 "Init" 1022 "Unterspannung" 1023 "Fehler" ;
VAL_ 278 ESP_Wegimpuls_HR 1021 "Init" 1022 "Unterspannung" 1023 "Fehler" ;
VAL_ 278 ESP_VL_Fahrtrichtung 0 "Vorwaerts" 1 "Rueckwaerts" 2 "Init" 3 "ungueltig_oder_nicht_verbaut" ;
VAL_ 278 ESP_VR_Fahrtrichtung 0 "Vorwaerts" 1 "Rueckwaerts" 2 "Init" 3 "ungueltig_oder_nicht_verbaut" ;
VAL_ 278 ESP_HL_Fahrtrichtung 0 "Vorwaerts" 1 "Rueckwaerts" 2 "Init" 3 "ungueltig_oder_nicht_verbaut" ;
VAL_ 278 ESP_HR_Fahrtrichtung 0 "Vorwaerts" 1 "Rueckwaerts" 2 "Init" 3 "ungueltig_oder_nicht_verbaut" ;
VAL_ 138 ESP_14_Status_DSR 0 "DSR_deaktiviert" 1 "DSR_Anf_nicht_ausfuehrbar" 2 "Kom_EPS_gestoert" 3 "ESP_DSR_funktionsbereit" 4 "reserviert" 5 "ext_Momeingriff_aktiv" 6 "reserviert" 7 "Moment_mit_reduziertem_active_return" 8 "reserviert" 9 "reserviert" 10 "reserviert" 11 "reserviert" 12 "reserviert" 13 "reserviert" 14 "reserviert" 15 "reserviert" ;
VAL_ 138 ESP_14_VZ_Anf_Lenkmomoffset_DSR 0 "positiv" 1 "negativ" ;
VAL_ 138 ESP_14_Sendestatus 0 "Bremse_sendet_mit_1000ms" 1 "Bremse_sendet_mit_10ms" ;
VAL_ 138 BR_Status_Quer_ESP 0 "Quersperre_deaktiviert" 1 "ESP_Fehlerstatus" 2 "Kommunikation_Quersp_gestoert" 3 "ESP_bereit" 4 "ESP_Anf_Quersperre" 5 "AYC_Unterst_mo_regl_aktiv" ;
VAL_ 138 BR_Vorg_Quer_Min 252 "Kupplung_schnell_zu" 254 "Init" 255 "Fehler" ;
VAL_ 138 BR_Vorg_Quer_Max 252 "Kupplung_schnell_offen" 254 "Init" 255 "Fehler" ;
VAL_ 138 BR_Vorg_Allrad_Min 251 "Ueberanpressung" 252 "Kupplung_schnell_zu" 254 "Init" 255 "Fehler" ;
VAL_ 138 BR_Vorg_Allrad_Max 251 "Ueberanpressung" 252 "Kupplung_schnell_offen" 254 "Init" 255 "Fehler" ;
VAL_ 418 HMS_P_beibehalten_GE 0 "P_nicht_beibehalten" 1 "P_beibehalten" 2 "Init" 3 "Fehler" ;
VAL_ 418 HMS_Konsistenz_GE 0 "kein_Fehler_erkannt" 1 "Fehler_erkannt" ;
VAL_ 418 HMS_Konsistenz_IPA 0 "kein_Fehler_erkannt" 1 "Fehler_erkannt" ;
VAL_ 418 HMS_Konsistenz_EBKV 0 "kein_Fehler_erkannt" 1 "Fehler_erkannt" ;
VAL_ 418 HMS_Konsistenz_RCTA 0 "kein_Fehler_erkannt" 1 "Fehler_erkannt" ;
VAL_ 418 HMS_Konsistenz_STA 0 "kein_Fehler_erkannt" 1 "Fehler_erkannt" ;
VAL_ 418 HMS_Konsistenz_MO 0 "kein_Fehler_erkannt" 1 "Fehler_erkannt" ;
VAL_ 418 HMS_halten_nicht_verfuegbar 0 "verfuegbar" 1 "nicht_verfuegbar" ;
VAL_ 418 NL_PRIM_STP_01_Status 0 "Primaersystem_Notlauf_off" 1 "Primaersystem_Notlauf_inaktiv" 2 "Primaersystem_Notlauf_standby" 3 "Primaersystem_Notlauf_ready" 4 "Primaersystem_Notlauf_aktiv" 5 "Primaersystem_Notlauf_nicht_verf" ;
VAL_ 418 HMS_Notstopp_Status 0 "Off_Init" 1 "Inaktiv" 2 "Ready" 3 "Aktiv" 4 "Pending" 7 "nicht_Verfuegbar" ;
VAL_ 418 HMS_parken_nicht_verfuegbar 0 "verfuegbar" 1 "nicht_verfuegbar" ;
VAL_ 418 HMS_Anforderung_GE 0 "keine_Anforderung" 1 "P_einlegen" ;
VAL_ 418 HMS_Systemstatus 0 "keine_Funktion_aktiv" 1 "Halten_aktiv" 2 "Parken_angefordert" 3 "Parken_aktiv" 4 "Parken_beibehalten_aktiv" 5 "Anfahren_aktiv" 6 "Loeseanforderung_aktiv" 7 "Loeseanforderung_durch_Fahrer" 8 "Abrutschen_erkannt" 9 "Halten_Standby_aktiv" 10 "Anfahren_Standby_aktiv" 14 "Init" 15 "Fehler" ;
VAL_ 418 HMS_Stillstand 0 "kein_Stillstand" 1 "Stillstand_frueh" 2 "Stillstand" 6 "Init" 7 "Fehler" ;
VAL_ 418 HMS_aktives_System 0 "kein_System__Init_Fehler" 1 "Fahreranforderung_aktiv" 2 "HMS_intern_aktiv" 3 "ACC_aktiv" 4 "Autohold_aktiv" 5 "HHC_aktiv" 6 "HVLM_aktiv" 7 "Getriebe_aktiv" 8 "EBKV_aktiv" 9 "IPA_aktiv" 10 "ARA_aktiv" 12 "autonomous_Hold_aktiv" 13 "STA_aktiv" 14 "Motor_aktiv" 15 "EA_aktiv" ;
VAL_ 418 HMS_Konsistenz_HVLM 0 "kein_Fehler_erkannt" 1 "Fehler_erkannt" ;
VAL_ 418 HMS_Konsistenz_ACC 0 "kein_Fehler_erkannt" 1 "Fehler_erkannt" ;
VAL_ 418 HMS_Fehlerstatus 0 "kein_Fehler" 1 "Halten_nicht_moeglich" 2 "Sonderbetriebsmodus_aktiv" 3 "Systemeinschraenkung" 4 "Systemstoerung" ;
VAL_ 418 ESP_Index_Haltemoment 0 "Bremsmoment" 1 "Antriebsmoment" ;
VAL_ 418 ESP_Haltemoment 1022 "Init" 1023 "Fehler" ;
VAL_ 178 ESP_HL_Radgeschw_02 65533 "Unterspannung" 65534 "Init" 65535 "Fehler" ;
VAL_ 178 ESP_HR_Radgeschw_02 65533 "Unterspannung" 65534 "Init" 65535 "Fehler" ;
VAL_ 178 ESP_VL_Radgeschw_02 65533 "Unterspannung" 65534 "Init" 65535 "Fehler" ;
VAL_ 178 ESP_VR_Radgeschw_02 65533 "Unterspannung" 65534 "Init" 65535 "Fehler" ;
VAL_ 1629 BR_Systemart 0 "ABS" 1 "ABS_ASR" 2 "ESP" 3 "ESP_mit_integrierter_EPB" ;
VAL_ 1629 ESP_SpannungsAnf_02 0 "keine_Anforderung" 1 "Anforderung_Stufe1" 2 "Anforderung_Stufe2" 3 "Anforderung_Stufe3" ;
VAL_ 1629 ESP_Charisma_FahrPr 0 "keine_Funktion" 1 "Programm_1" 2 "Programm_2" 3 "Programm_3" 4 "Programm_4" 5 "Programm_5" 6 "Programm_6" 7 "Programm_7" 8 "Programm_8" 9 "Programm_9" 10 "Programm_10" 11 "Programm_11" 12 "Programm_12" 13 "Programm_13" 14 "Programm_14" 15 "Programm_15" ;
VAL_ 1629 ESP_Charisma_Status 0 "Init" 1 "verfuegbar" 2 "nicht_verfuegbar" 3 "asynchron_durch_Fahrerwunsch" ;
VAL_ 1629 ESP_Wiederstart_Anz_01 0 "keine_Anzeige" 1 "Rueckwaertsrollen" ;
VAL_ 1629 ESP_Wiederstart_Anz_02 0 "keine_Anzeige" 1 "Autohold_Rutschen" ;
VAL_ 1629 ESP_Wiederstart_Anz_03 0 "keine_Anzeige" 1 "Offroad_HDC" ;
VAL_ 1629 ESP_Wiederstart_Anz_04 0 "keine_Anzeige" 1 "ESC_Off" ;
VAL_ 1629 ESP_Stoppverbot_Anz_01 0 "keine_Anzeige" 1 "Notbremsung_aktiv" ;
VAL_ 1629 ESP_Stoppverbot_Anz_02 0 "keine_Anzeige" 1 "Autohold_AVH_Rutschen" ;
VAL_ 1629 ESP_Stoppverbot_Anz_03 0 "keine_Anzeige" 1 "Rueckwaertsrollen" ;
VAL_ 1629 ESP_Stoppverbot_Anz_04 0 "keine_Anzeige" 1 "ESP_Pumpenlauf" ;
VAL_ 1629 ESP_Stoppverbot_Anz_05 0 "keine_Anzeige" 1 "ESP_OFF" ;
VAL_ 1629 ESP_Stoppverbot_Anz_06 0 "keine_Anzeige" 1 "Offroad_HDC" ;
VAL_ 1629 ESP_Stoppverbot_Anz_07 0 "keine_Anzeige" 1 "ESP_Haltefunktion_nicht_verfuegbar" ;
VAL_ 1629 ESP_Stoppverbot_Anz_Std 0 "keine_Anzeige" 1 "Standard_Stoppvetogrund" ;
VAL_ 1629 ESP_Dachrelingsensor 0 "Sensor_nicht_verbaut" 1 "Quertraeger_montiert" 2 "Quertraeger_nicht_montiert" 3 "Fehler" ;
VAL_ 1629 ESP_Stoppverbot_Anz_08 0 "keine_Anzeige" 1 "Neigungsbegrenzung" ;
VAL_ 1629 HDC_Charisma_FahrPr 0 "keine_Funktion" 1 "Programm_1" 2 "Programm_2" 3 "Programm_3" 4 "Programm_4" 5 "Programm_5" 6 "Programm_6" 7 "Programm_7" 8 "Programm_8" 9 "Programm_9" 10 "Programm_10" 11 "Programm_11" 12 "Programm_12" 13 "Programm_13" 14 "Programm_14" 15 "Programm_15" ;
VAL_ 1629 HDC_Charisma_Status 0 "Init" 1 "verfuegbar" 2 "nicht_verfuegbar" 3 "asynchron_durch_Fahrerwunsch" ;
VAL_ 1629 BR_QBit_Reifenumfang 0 "gueltiger_Wert" 1 "Ersatz_Init_oder_Fehlerwert" ;
VAL_ 253 BR_Eingriffsmoment 1022 "Init" 1023 "Fehler" ;
VAL_ 253 ESP_PLA_Bremseingriff 0 "inaktiv" 1 "aktiv" ;
VAL_ 253 ESP_Diagnose 0 "ESP_nicht_in_Diagnose" 1 "ESP_in_Diagnose" ;
VAL_ 253 ESC_Reku_Freigabe 0 "keine_Freigabe_der_Rekuperation" 1 "Freigabe_der_Rekuperation" ;
VAL_ 253 ESC_v_Signal_Qualifier_High_Low 0 "Gueteschwelle_kleiner_1kmh" 1 "Gueteschwelle_kleiner_3kmh" 2 "Gueteschwelle_kleiner_5kmh" 3 "Gueteschwelle_kleiner_10kmh" 4 "Gueteschwelle_kleiner_20kmh" 5 "Gueteschwelle_groessergleich_20kmh" 6 "Init" 7 "Fehler" ;
VAL_ 253 ESP_Vorsteuerung 0 "keine_Vorsteuerung_aktiv" 1 "Vorsteuerung_aktiv" ;
VAL_ 253 ESP_AWV3_Brems_aktiv 0 "inaktiv" 1 "aktiv" ;
VAL_ 253 OBD_Schlechtweg 0 "kein_Schlechtweg_erkannt" 1 "Schlechtweg_erkannt" ;
VAL_ 253 OBD_QBit_Schlechtweg 0 "gueltiger_Wert" 1 "Ersatz_Init_oder_Fehlerwert" ;
VAL_ 253 ESP_v_Signal 65533 "Unterspannung" 65534 "Init" 65535 "Fehler" ;
VAL_ 253 ASR_Tastung_passiv 0 "ASR_aktiviert" 1 "ASR_passiv_getastet_oder_Schwellen_geaendert" ;
VAL_ 253 ESP_Tastung_passiv 0 "ESP_aktiviert" 1 "ESP_passiv_getastet_oder_Schwellen_geaendert" ;
VAL_ 253 ESP_Systemstatus 0 "iO" 1 "Fehler" ;
VAL_ 253 ASR_Schalteingriff 0 "keine_Anforderung" 1 "ASR_Schaltkennfeld" 2 "Rueckschaltung" 3 "Schaltverbot" ;
VAL_ 253 ESP_Haltebestaetigung 0 "kein_sicheres_Halten" 1 "sicheres_Halten" ;
VAL_ 253 ESP_MKB_Abbruch_Geschw 0 "MKB_nicht_beendet_wg_v_Schwelle" 1 "MKB_beendet_wg_v_Schwelle" ;
VAL_ 253 ESP_QBit_v_Signal 0 "gueltiger_Wert" 1 "Ersatz_Init_oder_Fehlerwert" ;
VAL_ 253 ABS_Bremsung 0 "keine_ABS_Regelung" 1 "ABS_Regelung_aktiv" ;
VAL_ 253 ASR_Anf 0 "keine_Anforderung" 1 "ASR_Anforderung" ;
VAL_ 253 MSR_Anf 0 "keine Anfoderung" 1 "MSR-Anforderung" ;
VAL_ 253 EBV_Eingriff 0 "kein_EBV_Eingriff" 1 "EBV_Eingriff" ;
VAL_ 253 EDS_Eingriff 0 "kein_EDS_Eingriff" 1 "EDS_Eingriff" ;
VAL_ 253 ESP_Eingriff 0 "kein_ESP_Eingriff" 1 "ESP_Eingriff_aktiv" ;
VAL_ 253 ESP_ASP 0 "inaktiv" 1 "aktiv" ;
VAL_ 253 ESP_Anhaltevorgang_ACC_aktiv 0 "inaktiv" 1 "aktiv" ;
